VERSION ""

NS_ :

BS_:

BU_: NBICU SBICU NBCMU SBCMU DAPP Vector_XXX

BO_ 2561802145 NBCMU01_WarningInfo1: 8 NBCMU
 SG_ NBCMU01_HeatCurr : 7|12@0+ (0.1,-200) [-200|200] "A"  DAPP
 SG_ NBCMU01_SysFailSta : 9|2@0+ (1,0) [0|3] ""  DAPP
 SG_ NBCMU01_InsRes_polarity : 11|2@0+ (1,0) [0|3] ""  DAPP
 SG_ NBCMU01_BattVolt_HighWarning : 17|2@0+ (1,0) [0|3] ""  DAPP
 SG_ NBCMU01_BattVolt_LowWarning : 19|2@0+ (1,0) [0|3] ""  DAPP
 SG_ NBCMU01_CellVolt_HighWarning : 21|2@0+ (1,0) [0|3] ""  DAPP
 SG_ NBCMU01_CellVolt_LowWarning : 23|2@0+ (1,0) [0|3] ""  DAPP
 SG_ NBCMU01_ChrgTemp_HighWarning : 25|2@0+ (1,0) [0|3] ""  DAPP
 SG_ NBCMU01_ChrgTemp_LowWarning : 27|2@0+ (1,0) [0|3] ""  DAPP
 SG_ NBCMU01_DischrgTemp_HighWarning : 29|2@0+ (1,0) [0|3] ""  DAPP
 SG_ NBCMU01_DischrgTemp_LowWarning : 31|2@0+ (1,0) [0|3] ""  DAPP
 SG_ NBCMU01_TempDiff_Warning : 33|2@0+ (1,0) [0|3] ""  DAPP
 SG_ NBCMU01_CellVoltDiff_Warning : 35|2@0+ (1,0) [0|3] ""  DAPP
 SG_ NBCMU01_DischrgCurr_OverWarning : 37|2@0+ (1,0) [0|3] ""  DAPP
 SG_ NBCMU01_ChrgCurr_OverWarning : 39|2@0+ (1,0) [0|3] ""  DAPP
 SG_ NBCMU01_InsulationWarning : 41|2@0+ (1,0) [0|3] ""  DAPP
 SG_ NBCMU01_SOC_LowWarning : 43|2@0+ (1,0) [0|3] ""  DAPP
 SG_ NBCMU01_AmbientTemp_HighWarning : 45|2@0+ (1,0) [0|3] ""  DAPP
 SG_ NBCMU01_AmbientTemp_LowWarning : 47|2@0+ (1,0) [0|3] ""  DAPP
 SG_ NBCMU01_ContactorPosi_Fault : 49|2@0+ (1,0) [0|3] ""  DAPP
 SG_ NBCMU01_ContactorNega_Fault : 51|2@0+ (1,0) [0|3] ""  DAPP
 SG_ NBCMU01_ContactorBalan_Fault : 53|2@0+ (1,0) [0|3] ""  DAPP
 SG_ NBCMU01_ContactorHeat_Fault : 55|2@0+ (1,0) [0|3] ""  DAPP
 SG_ NBCMU01_CurrSensor_TimeOut : 57|1@0+ (1,0) [0|1] ""  DAPP
 SG_ NBCMU01_SOH_LowWarning : 59|2@0+ (1,0) [0|3] ""  DAPP
 SG_ NBCMU01_HVIL_Fault : 62|1@0+ (1,0) [0|1] ""  DAPP
 SG_ NBCMU01_Fuse_Fault : 63|1@0+ (1,0) [0|1] ""  DAPP

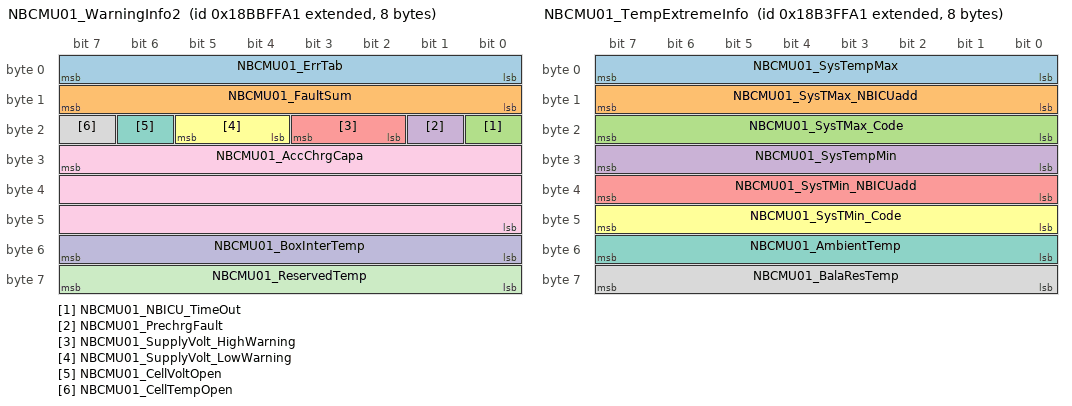
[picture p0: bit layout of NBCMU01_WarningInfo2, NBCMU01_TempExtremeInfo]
BO_ 2562457505 NBCMU01_WarningInfo2: 8 NBCMU
 SG_ NBCMU01_ErrTab : 7|8@0+ (1,0) [0|255] ""  DAPP
 SG_ NBCMU01_FaultSum : 15|8@0+ (1,0) [0|255] ""  DAPP
 SG_ NBCMU01_NBICU_TimeOut : 16|1@0+ (1,0) [0|1] ""  DAPP
 SG_ NBCMU01_PrechrgFault : 17|1@0+ (1,0) [0|1] ""  DAPP
 SG_ NBCMU01_SupplyVolt_HighWarning : 19|2@0+ (1,0) [0|3] ""  DAPP
 SG_ NBCMU01_SupplyVolt_LowWarning : 21|2@0+ (1,0) [0|3] ""  DAPP
 SG_ NBCMU01_CellVoltOpen : 22|1@0+ (1,0) [0|1] ""  DAPP
 SG_ NBCMU01_CellTempOpen : 23|1@0+ (1,0) [0|1] ""  DAPP
 SG_ NBCMU01_AccChrgCapa : 31|24@0+ (1,0) [0|16777215] "Ah"  DAPP
 SG_ NBCMU01_BoxInterTemp : 55|8@0+ (1,-40) [-40|215] "℃"  DAPP
 SG_ NBCMU01_ReservedTemp : 63|8@0+ (1,-40) [-40|215] "℃"  DAPP

BO_ 2561867681 NBCMU01_VoltExtremeInfo: 8 NBCMU
 SG_ NBCMU01_SysCellVoltMax : 7|16@0+ (1,0) [0|65535] "mV"  DAPP
 SG_ NBCMU01_SysVMax_NBICUadd : 23|8@0+ (1,0) [0|255] ""  DAPP
 SG_ NBCMU01_SysVMax_Code : 31|8@0+ (1,0) [0|255] ""  DAPP
 SG_ NBCMU01_SysCellVoltMin : 39|16@0+ (1,0) [0|65535] "mV"  DAPP
 SG_ NBCMU01_SysVMin_NBICUadd : 55|8@0+ (1,0) [0|255] ""  DAPP
 SG_ NBCMU01_SysVMin_Code : 63|8@0+ (1,0) [0|255] ""  DAPP

BO_ 2561933217 NBCMU01_TempExtremeInfo: 8 NBCMU
 SG_ NBCMU01_SysTempMax : 7|8@0+ (1,-40) [-40|215] "℃"  DAPP
 SG_ NBCMU01_SysTMax_NBICUadd : 15|8@0+ (1,0) [0|255] ""  DAPP
 SG_ NBCMU01_SysTMax_Code : 23|8@0+ (1,0) [0|255] ""  DAPP
 SG_ NBCMU01_SysTempMin : 31|8@0+ (1,-40) [-40|215] "℃"  DAPP
 SG_ NBCMU01_SysTMin_NBICUadd : 39|8@0+ (1,0) [0|255] ""  DAPP
 SG_ NBCMU01_SysTMin_Code : 47|8@0+ (1,0) [0|255] ""  DAPP
 SG_ NBCMU01_AmbientTemp : 55|8@0+ (1,-40) [-40|215] "℃"  DAPP
 SG_ NBCMU01_BalaResTemp : 63|8@0+ (1,-40) [-40|215] "℃"  DAPP

BO_ 2561998753 NBCMU01_SysSOX: 8 NBCMU
 SG_ NBCMU01_SysSOC_Actl : 7|16@0+ (0.1,0) [0|65535] "%"  DAPP
 SG_ NBCMU01_SysSOC_Dis : 23|16@0+ (0.1,0) [0|65535] "%"  DAPP
 SG_ NBCMU01_SysSOH_ByNBICU : 39|8@0+ (1,0) [0|255] "%"  DAPP
 SG_ NBCMU01_SysSOH_Cal : 47|8@0+ (1,0) [0|255] "%"  DAPP
 SG_ NBCMU01_SysSOE : 55|16@0+ (0.1,0) [0|6553.5] "%"  DAPP

BO_ 2562064289 NBCMU01_SysHVoltage: 8 NBCMU
 SG_ NBCMU01_SysHVoltage : 7|16@0+ (0.1,0) [0|6553.5] "V"  DAPP
 SG_ NBCMU01_SysSumVoltage : 23|16@0+ (0.1,0) [0|6553.5] "V"  DAPP
 SG_ NBCMU01_SysSampVoltage : 39|16@0+ (0.1,0) [0|6553.5] "V"  DAPP
 SG_ NBCMU01_SysInsRes : 55|16@0+ (1,0) [0|65535] "KΩ"  DAPP

BO_ 2562195361 NBCMU01_DischrgChrg: 8 NBCMU
 SG_ NBCMU01_MaxConDisCurnt : 7|16@0+ (0.1,0) [0|6553.5] "A"  DAPP
 SG_ NBCMU01_MaxConChrgCurnt : 23|16@0+ (0.1,0) [0|6553.5] "A"  DAPP
 SG_ NBCMU01_MaxInstanDisCurnt : 39|16@0+ (0.1,0) [0|6553.5] "A"  DAPP
 SG_ NBCMU01_MaxInstanChrgCurnt : 55|16@0+ (0.1,0) [0|6553.5] "A"  DAPP

BO_ 2560884641 NBCMU01_WarningInfo3: 8 NBCMU
 SG_ NBCMU01_SumVolt_HighWarning : 1|2@0+ (1,0) [0|3] ""  SBCMU,DAPP
 SG_ NBCMU01_SumVolt_LowWarning : 3|2@0+ (1,0) [0|3] ""  SBCMU,DAPP
 SG_ NBCMU01_CurrentLoop_HighWarning : 8|1@0+ (1,0) [0|1] ""  SBCMU,DAPP
 SG_ NBCMU01_ProtectFault : 9|1@0+ (1,0) [0|1] ""  SBCMU,DAPP
 SG_ NBCMU01_RunLed_State : 10|1@0+ (1,0) [0|1] ""  SBCMU,DAPP
 SG_ NBCMU01_Buzz_State : 11|1@0+ (1,0) [0|1] ""  SBCMU,DAPP
 SG_ NBCMU01_Heating_State : 12|1@0+ (1,0) [0|1] ""  SBCMU,DAPP
 SG_ NBCMU01_Cooling_State : 13|1@0+ (1,0) [0|1] ""  SBCMU,DAPP
 SG_ NBCMU01_BattVoltDiff_Warning : 14|1@0+ (1,0) [0|1] ""  SBCMU,DAPP
 SG_ NBCMU01_EmergyShutdown_Fault : 15|1@0+ (1,0) [0|1] ""  SBCMU,DAPP
 SG_ NBCMU01_PCS_TimeOut : 16|1@0+ (1,0) [0|1] ""  SBCMU,DAPP
 SG_ NBCMU01_EMS_TimeOut : 17|1@0+ (1,0) [0|1] ""  SBCMU,DAPP
 SG_ NBCMU01_TMS_TimeOut : 18|1@0+ (1,0) [0|1] ""  SBCMU,DAPP
 SG_ NBCMU01_SBCMU01_TimeOut : 19|1@0+ (1,0) [0|1] ""  SBCMU,DAPP
 SG_ NBCMU01_InitialFault : 30|1@0+ (1,0) [0|1] ""  SBCMU,DAPP
 SG_ NBCMU01_ThermalManagement_Fault : 31|1@0+ (1,0) [0|3] ""  SBCMU,DAPP
 SG_ NBCMU01_DCS_ActOprtMode : 26|3@0+ (1,0) [0|7] ""  SBCMU,DAPP
 SG_ NBCMU01_ChrgFault : 27|1@0+ (1,0) [0|1] ""  SBCMU,DAPP
 SG_ NBCMU01_DC_ChrgEnable : 28|1@0+ (1,0) [0|1] ""  SBCMU,DAPP
 SG_ NBCMU01_Contactor_DC_Cmd : 29|1@0+ (1,0) [0|1] ""  SBCMU,DAPP
 SG_ NBCMU01_MaxAllowChrgCur_DC : 39|16@0+ (0.1,0) [0|6553.5] "A"  SBCMU,DAPP
 SG_ NBCMU01_MaxAllowChrgVol_DC : 55|16@0+ (0.1,0) [0|6553.5] "V"  SBCMU,DAPP

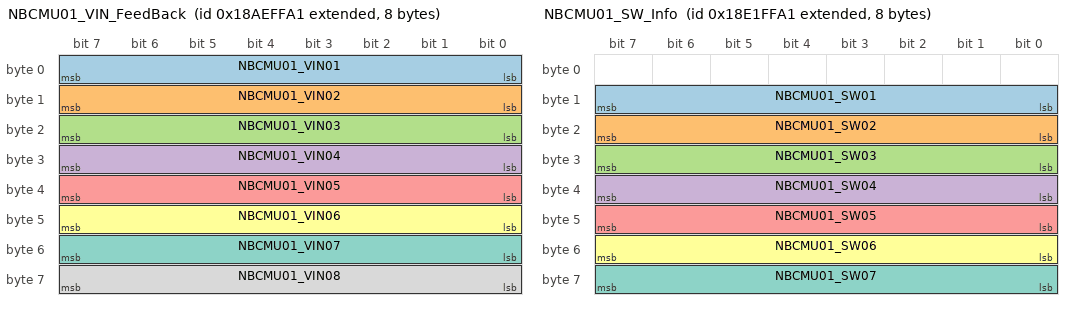
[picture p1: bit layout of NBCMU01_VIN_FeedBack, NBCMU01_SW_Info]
BO_ 2561605537 NBCMU01_VIN_FeedBack: 8 NBCMU
 SG_ NBCMU01_VIN01 : 7|8@0+ (1,0) [0|255] ""  DAPP
 SG_ NBCMU01_VIN02 : 15|8@0+ (1,0) [0|255] ""  DAPP
 SG_ NBCMU01_VIN03 : 23|8@0+ (1,0) [0|255] ""  DAPP
 SG_ NBCMU01_VIN04 : 31|8@0+ (1,0) [0|255] ""  DAPP
 SG_ NBCMU01_VIN05 : 39|8@0+ (1,0) [0|155] ""  DAPP
 SG_ NBCMU01_VIN06 : 47|8@0+ (1,0) [0|255] ""  DAPP
 SG_ NBCMU01_VIN07 : 55|8@0+ (1,0) [0|255] ""  DAPP
 SG_ NBCMU01_VIN08 : 63|8@0+ (1,0) [0|255] ""  DAPP

BO_ 2564947873 NBCMU01_SW_Info: 8 NBCMU
 SG_ NBCMU01_SW01 : 15|8@0+ (1,0) [0|255] ""  DAPP
 SG_ NBCMU01_SW02 : 23|8@0+ (1,0) [0|255] ""  DAPP
 SG_ NBCMU01_SW03 : 31|8@0+ (1,0) [0|255] ""  DAPP
 SG_ NBCMU01_SW04 : 39|8@0+ (1,0) [0|255] ""  DAPP
 SG_ NBCMU01_SW05 : 47|8@0+ (1,0) [0|255] ""  DAPP
 SG_ NBCMU01_SW06 : 55|8@0+ (1,0) [0|255] ""  DAPP
 SG_ NBCMU01_SW07 : 63|8@0+ (1,0) [0|255] ""  DAPP

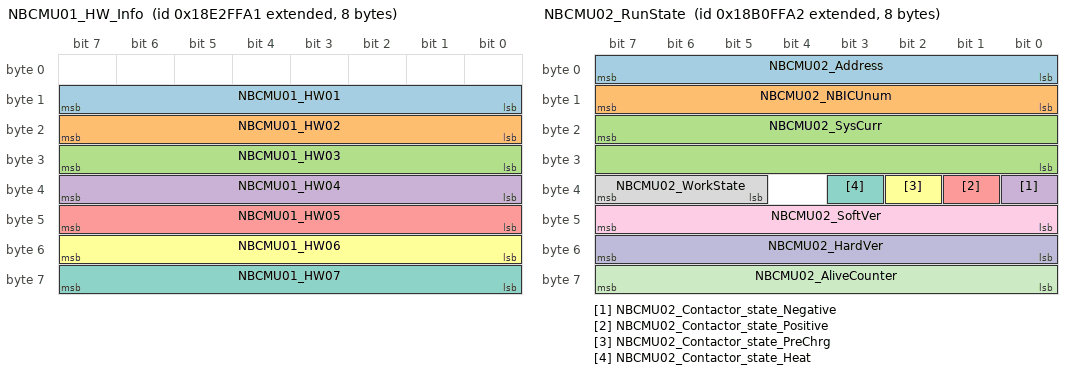
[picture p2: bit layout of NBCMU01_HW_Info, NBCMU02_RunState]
BO_ 2565013409 NBCMU01_HW_Info: 8 NBCMU
 SG_ NBCMU01_HW01 : 15|8@0+ (1,0) [0|255] ""  DAPP
 SG_ NBCMU01_HW02 : 23|8@0+ (1,0) [0|255] ""  DAPP
 SG_ NBCMU01_HW03 : 31|8@0+ (1,0) [0|255] ""  DAPP
 SG_ NBCMU01_HW04 : 39|8@0+ (1,0) [0|255] ""  DAPP
 SG_ NBCMU01_HW05 : 47|8@0+ (1,0) [0|255] ""  DAPP
 SG_ NBCMU01_HW06 : 55|8@0+ (1,0) [0|255] ""  DAPP
 SG_ NBCMU01_HW07 : 63|8@0+ (1,0) [0|255] ""  DAPP

BO_ 2561736610 NBCMU02_RunState: 8 NBCMU
 SG_ NBCMU02_Address : 7|8@0+ (1,0) [0|255] ""  DAPP
 SG_ NBCMU02_NBICUnum : 15|8@0+ (1,0) [0|255] ""  DAPP
 SG_ NBCMU02_SysCurr : 23|16@0+ (0.1,-3000) [-3000|3000] "A"  DAPP
 SG_ NBCMU02_Contactor_state_Negative : 32|1@0+ (1,0) [0|1] ""  DAPP
 SG_ NBCMU02_Contactor_state_Positive : 33|1@0+ (1,0) [0|1] ""  DAPP
 SG_ NBCMU02_Contactor_state_PreChrg : 34|1@0+ (1,0) [0|1] ""  DAPP
 SG_ NBCMU02_Contactor_state_Heat : 35|1@0+ (1,0) [0|1] ""  DAPP
 SG_ NBCMU02_WorkState : 39|3@0+ (1,0) [0|7] ""  DAPP
 SG_ NBCMU02_SoftVer : 47|8@0+ (1,0) [0|255] ""  DAPP
 SG_ NBCMU02_HardVer : 55|8@0+ (1,0) [0|255] ""  DAPP
 SG_ NBCMU02_AliveCounter : 63|8@0+ (1,0) [0|255] ""  DAPP

BO_ 2561802146 NBCMU02_WarningInfo1: 8 NBCMU
 SG_ NBCMU02_HeatCurr : 7|12@0+ (0.1,-200) [-200|200] "A"  DAPP
 SG_ NBCMU02_SysFailSta : 9|2@0+ (1,0) [0|3] ""  DAPP
 SG_ NBCMU02_InsRes_polarity : 11|2@0+ (1,0) [0|3] ""  DAPP
 SG_ NBCMU02_BattVolt_HighWarning : 17|2@0+ (1,0) [0|3] ""  DAPP
 SG_ NBCMU02_BattVolt_LowWarning : 19|2@0+ (1,0) [0|3] ""  DAPP
 SG_ NBCMU02_CellVolt_HighWarning : 21|2@0+ (1,0) [0|3] ""  DAPP
 SG_ NBCMU02_CellVolt_LowWarning : 23|2@0+ (1,0) [0|3] ""  DAPP
 SG_ NBCMU02_ChrgTemp_HighWarning : 25|2@0+ (1,0) [0|3] ""  DAPP
 SG_ NBCMU02_ChrgTemp_LowWarning : 27|2@0+ (1,0) [0|3] ""  DAPP
 SG_ NBCMU02_DischrgTemp_HighWarning : 29|2@0+ (1,0) [0|3] ""  DAPP
 SG_ NBCMU02_DischrgTemp_LowWarning : 31|2@0+ (1,0) [0|3] ""  DAPP
 SG_ NBCMU02_TempDiff_Warning : 33|2@0+ (1,0) [0|3] ""  DAPP
 SG_ NBCMU02_CellVoltDiff_Warning : 35|2@0+ (1,0) [0|3] ""  DAPP
 SG_ NBCMU02_DischrgCurr_OverWarning : 37|2@0+ (1,0) [0|3] ""  DAPP
 SG_ NBCMU02_ChrgCurr_OverWarning : 39|2@0+ (1,0) [0|3] ""  DAPP
 SG_ NBCMU02_InsulationWarning : 41|2@0+ (1,0) [0|3] ""  DAPP
 SG_ NBCMU02_SOC_LowWarning : 43|2@0+ (1,0) [0|3] ""  DAPP
 SG_ NBCMU02_AmbientTemp_HighWarning : 45|2@0+ (1,0) [0|3] ""  DAPP
 SG_ NBCMU02_AmbientTemp_LowWarning : 47|2@0+ (1,0) [0|3] ""  DAPP
 SG_ NBCMU02_ContactorPosi_Fault : 49|2@0+ (1,0) [0|3] ""  DAPP
 SG_ NBCMU02_ContactorNega_Fault : 51|2@0+ (1,0) [0|3] ""  DAPP
 SG_ NBCMU02_ContactorBalan_Fault : 53|2@0+ (1,0) [0|3] ""  DAPP
 SG_ NBCMU02_ContactorHeat_Fault : 55|2@0+ (1,0) [0|3] ""  DAPP
 SG_ NBCMU02_CurrSensor_TimeOut : 57|1@0+ (1,0) [0|1] ""  DAPP
 SG_ NBCMU02_SOH_LowWarning : 59|2@0+ (1,0) [0|3] ""  DAPP
 SG_ NBCMU02_HVIL_Fault : 62|1@0+ (1,0) [0|1] ""  DAPP
 SG_ NBCMU02_Fuse_Fault : 63|1@0+ (1,0) [0|1] ""  DAPP

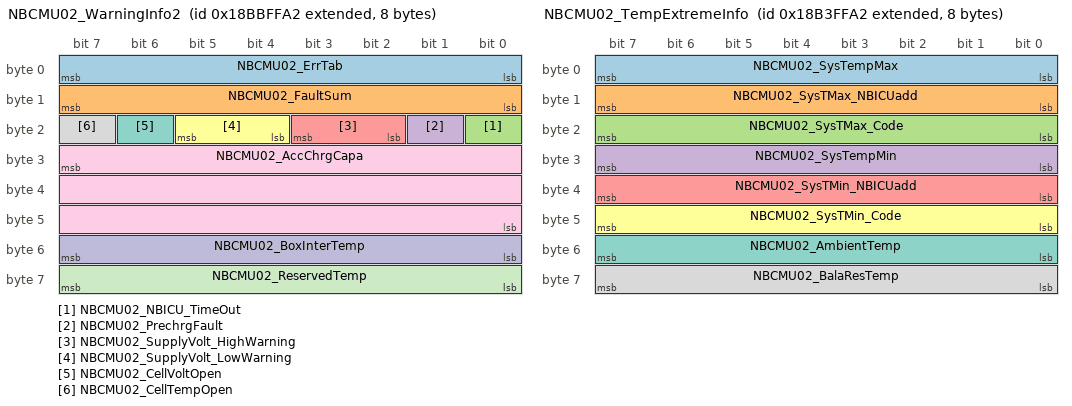
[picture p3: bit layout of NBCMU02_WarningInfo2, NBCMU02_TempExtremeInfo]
BO_ 2562457506 NBCMU02_WarningInfo2: 8 NBCMU
 SG_ NBCMU02_ErrTab : 7|8@0+ (1,0) [0|255] ""  DAPP
 SG_ NBCMU02_FaultSum : 15|8@0+ (1,0) [0|255] ""  DAPP
 SG_ NBCMU02_NBICU_TimeOut : 16|1@0+ (1,0) [0|1] ""  DAPP
 SG_ NBCMU02_PrechrgFault : 17|1@0+ (1,0) [0|1] ""  DAPP
 SG_ NBCMU02_SupplyVolt_HighWarning : 19|2@0+ (1,0) [0|3] ""  DAPP
 SG_ NBCMU02_SupplyVolt_LowWarning : 21|2@0+ (1,0) [0|3] ""  DAPP
 SG_ NBCMU02_CellVoltOpen : 22|1@0+ (1,0) [0|1] ""  DAPP
 SG_ NBCMU02_CellTempOpen : 23|1@0+ (1,0) [0|1] ""  DAPP
 SG_ NBCMU02_AccChrgCapa : 31|24@0+ (1,0) [0|16777215] "Ah"  DAPP
 SG_ NBCMU02_BoxInterTemp : 55|8@0+ (1,-40) [-40|215] "℃"  DAPP
 SG_ NBCMU02_ReservedTemp : 63|8@0+ (1,-40) [-40|215] "℃"  DAPP

BO_ 2561867682 NBCMU02_VoltExtremeInfo: 8 NBCMU
 SG_ NBCMU02_SysCellVoltMax : 7|16@0+ (1,0) [0|65535] "mV"  DAPP
 SG_ NBCMU02_SysVMax_NBICUadd : 23|8@0+ (1,0) [0|255] ""  DAPP
 SG_ NBCMU02_SysVMax_Code : 31|8@0+ (1,0) [0|255] ""  DAPP
 SG_ NBCMU02_SysCellVoltMin : 39|16@0+ (1,0) [0|65535] "mV"  DAPP
 SG_ NBCMU02_SysVMin_NBICUadd : 55|8@0+ (1,0) [0|255] ""  DAPP
 SG_ NBCMU02_SysVMin_Code : 63|8@0+ (1,0) [0|255] ""  DAPP

BO_ 2561933218 NBCMU02_TempExtremeInfo: 8 NBCMU
 SG_ NBCMU02_SysTempMax : 7|8@0+ (1,-40) [-40|215] "℃"  DAPP
 SG_ NBCMU02_SysTMax_NBICUadd : 15|8@0+ (1,0) [0|255] ""  DAPP
 SG_ NBCMU02_SysTMax_Code : 23|8@0+ (1,0) [0|255] ""  DAPP
 SG_ NBCMU02_SysTempMin : 31|8@0+ (1,-40) [-40|215] "℃"  DAPP
 SG_ NBCMU02_SysTMin_NBICUadd : 39|8@0+ (1,0) [0|255] ""  DAPP
 SG_ NBCMU02_SysTMin_Code : 47|8@0+ (1,0) [0|255] ""  DAPP
 SG_ NBCMU02_AmbientTemp : 55|8@0+ (1,-40) [-40|215] "℃"  DAPP
 SG_ NBCMU02_BalaResTemp : 63|8@0+ (1,-40) [-40|215] "℃"  DAPP

BO_ 2561998754 NBCMU02_SysSOX: 8 NBCMU
 SG_ NBCMU02_SysSOC_Actl : 7|16@0+ (0.1,0) [0|65535] "%"  DAPP
 SG_ NBCMU02_SysSOC_Dis : 23|16@0+ (0.1,0) [0|65535] "%"  DAPP
 SG_ NBCMU02_SysSOH_ByNBICU : 39|8@0+ (1,0) [0|255] "%"  DAPP
 SG_ NBCMU02_SysSOH_Cal : 47|8@0+ (1,0) [0|255] "%"  DAPP
 SG_ NBCMU02_SysSOE : 55|16@0+ (0.1,0) [0|6553.5] "%"  DAPP

BO_ 2562064290 NBCMU02_SysHVoltage: 8 NBCMU
 SG_ NBCMU02_SysHVoltage : 7|16@0+ (0.1,0) [0|6553.5] "V"  DAPP
 SG_ NBCMU02_SysSumVoltage : 23|16@0+ (0.1,0) [0|6553.5] "V"  DAPP
 SG_ NBCMU02_SysSampVoltage : 39|16@0+ (0.1,0) [0|6553.5] "V"  DAPP
 SG_ NBCMU02_SysInsRes : 55|16@0+ (1,0) [0|65535] "KΩ"  DAPP

BO_ 2562195362 NBCMU02_DischrgChrg: 8 NBCMU
 SG_ NBCMU02_MaxConDisCurnt : 7|16@0+ (0.1,0) [0|6553.5] "A"  DAPP
 SG_ NBCMU02_MaxConChrgCurnt : 23|16@0+ (0.1,0) [0|6553.5] "A"  DAPP
 SG_ NBCMU02_MaxInstanDisCurnt : 39|16@0+ (0.1,0) [0|6553.5] "A"  DAPP
 SG_ NBCMU02_MaxInstanChrgCurnt : 55|16@0+ (0.1,0) [0|6553.5] "A"  DAPP

BO_ 2560884642 NBCMU02_WarningInfo3: 8 NBCMU
 SG_ NBCMU02_SumVolt_HighWarning : 1|2@0+ (1,0) [0|3] ""  SBCMU,DAPP
 SG_ NBCMU02_SumVolt_LowWarning : 3|2@0+ (1,0) [0|3] ""  SBCMU,DAPP
 SG_ NBCMU02_CurrentLoop_HighWarning : 8|1@0+ (1,0) [0|1] ""  SBCMU,DAPP
 SG_ NBCMU02_ProtectFault : 9|1@0+ (1,0) [0|1] ""  SBCMU,DAPP
 SG_ NBCMU02_RunLed_State : 10|1@0+ (1,0) [0|1] ""  SBCMU,DAPP
 SG_ NBCMU02_Buzz_State : 11|1@0+ (1,0) [0|1] ""  SBCMU,DAPP
 SG_ NBCMU02_Heating_State : 12|1@0+ (1,0) [0|1] ""  SBCMU,DAPP
 SG_ NBCMU02_Cooling_State : 13|1@0+ (1,0) [0|1] ""  SBCMU,DAPP
 SG_ NBCMU02_BattVoltDiff_Warning : 14|1@0+ (1,0) [0|1] ""  SBCMU,DAPP
 SG_ NBCMU02_EmergyShutdown_Fault : 15|1@0+ (1,0) [0|1] ""  SBCMU,DAPP
 SG_ NBCMU02_PCS_TimeOut : 16|1@0+ (1,0) [0|1] ""  SBCMU,DAPP
 SG_ NBCMU02_EMS_TimeOut : 17|1@0+ (1,0) [0|1] ""  SBCMU,DAPP
 SG_ NBCMU02_TMS_TimeOut : 18|1@0+ (1,0) [0|1] ""  SBCMU,DAPP
 SG_ NBCMU02_SBCMU01_TimeOut : 19|1@0+ (1,0) [0|1] ""  SBCMU,DAPP
 SG_ NBCMU02_InitialFault : 30|1@0+ (1,0) [0|1] ""  SBCMU,DAPP
 SG_ NBCMU02_ThermalManagement_Fault : 31|1@0+ (1,0) [0|3] ""  SBCMU,DAPP
 SG_ NBCMU02_DCS_ActOprtMode : 26|3@0+ (1,0) [0|7] ""  SBCMU,DAPP
 SG_ NBCMU02_ChrgFault : 27|1@0+ (1,0) [0|1] ""  SBCMU,DAPP
 SG_ NBCMU02_DC_ChrgEnable : 28|1@0+ (1,0) [0|1] ""  SBCMU,DAPP
 SG_ NBCMU02_Contactor_DC_Cmd : 29|1@0+ (1,0) [0|1] ""  SBCMU,DAPP
 SG_ NBCMU02_MaxAllowChrgCur_DC : 39|16@0+ (0.1,0) [0|6553.5] "A"  SBCMU,DAPP
 SG_ NBCMU02_MaxAllowChrgVol_DC : 55|16@0+ (0.1,0) [0|6553.5] "V"  SBCMU,DAPP

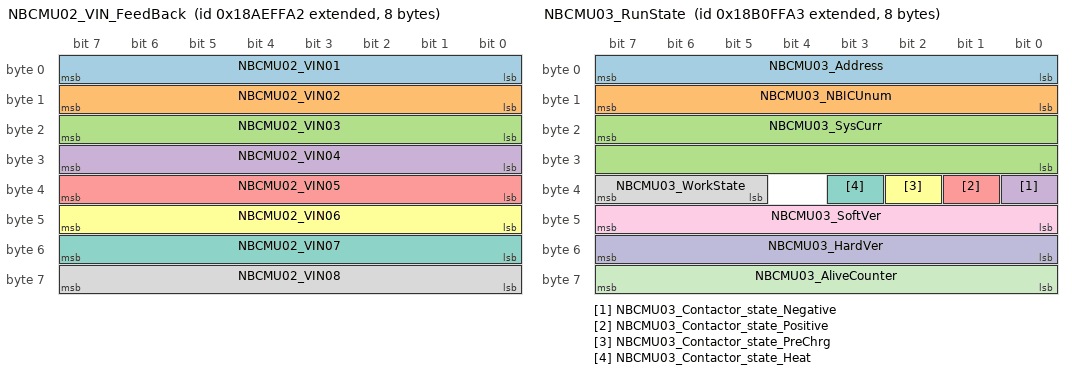
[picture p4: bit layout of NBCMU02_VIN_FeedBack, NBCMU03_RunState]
BO_ 2561605538 NBCMU02_VIN_FeedBack: 8 NBCMU
 SG_ NBCMU02_VIN01 : 7|8@0+ (1,0) [0|255] ""  DAPP
 SG_ NBCMU02_VIN02 : 15|8@0+ (1,0) [0|255] ""  DAPP
 SG_ NBCMU02_VIN03 : 23|8@0+ (1,0) [0|255] ""  DAPP
 SG_ NBCMU02_VIN04 : 31|8@0+ (1,0) [0|255] ""  DAPP
 SG_ NBCMU02_VIN05 : 39|8@0+ (1,0) [0|155] ""  DAPP
 SG_ NBCMU02_VIN06 : 47|8@0+ (1,0) [0|255] ""  DAPP
 SG_ NBCMU02_VIN07 : 55|8@0+ (1,0) [0|255] ""  DAPP
 SG_ NBCMU02_VIN08 : 63|8@0+ (1,0) [0|255] ""  DAPP

BO_ 2564947874 NBCMU02_SW_Info: 8 NBCMU
 SG_ NBCMU02_SW01 : 15|8@0+ (1,0) [0|255] ""  DAPP
 SG_ NBCMU02_SW02 : 23|8@0+ (1,0) [0|255] ""  DAPP
 SG_ NBCMU02_SW03 : 31|8@0+ (1,0) [0|255] ""  DAPP
 SG_ NBCMU02_SW04 : 39|8@0+ (1,0) [0|255] ""  DAPP
 SG_ NBCMU02_SW05 : 47|8@0+ (1,0) [0|255] ""  DAPP
 SG_ NBCMU02_SW06 : 55|8@0+ (1,0) [0|255] ""  DAPP
 SG_ NBCMU02_SW07 : 63|8@0+ (1,0) [0|255] ""  DAPP

BO_ 2565013410 NBCMU02_HW_Info: 8 NBCMU
 SG_ NBCMU02_HW01 : 15|8@0+ (1,0) [0|255] ""  DAPP
 SG_ NBCMU02_HW02 : 23|8@0+ (1,0) [0|255] ""  DAPP
 SG_ NBCMU02_HW03 : 31|8@0+ (1,0) [0|255] ""  DAPP
 SG_ NBCMU02_HW04 : 39|8@0+ (1,0) [0|255] ""  DAPP
 SG_ NBCMU02_HW05 : 47|8@0+ (1,0) [0|255] ""  DAPP
 SG_ NBCMU02_HW06 : 55|8@0+ (1,0) [0|255] ""  DAPP
 SG_ NBCMU02_HW07 : 63|8@0+ (1,0) [0|255] ""  DAPP

BO_ 2561736611 NBCMU03_RunState: 8 NBCMU
 SG_ NBCMU03_Address : 7|8@0+ (1,0) [0|255] ""  DAPP
 SG_ NBCMU03_NBICUnum : 15|8@0+ (1,0) [0|255] ""  DAPP
 SG_ NBCMU03_SysCurr : 23|16@0+ (0.1,-3000) [-3000|3000] "A"  DAPP
 SG_ NBCMU03_Contactor_state_Negative : 32|1@0+ (1,0) [0|1] ""  DAPP
 SG_ NBCMU03_Contactor_state_Positive : 33|1@0+ (1,0) [0|1] ""  DAPP
 SG_ NBCMU03_Contactor_state_PreChrg : 34|1@0+ (1,0) [0|1] ""  DAPP
 SG_ NBCMU03_Contactor_state_Heat : 35|1@0+ (1,0) [0|1] ""  DAPP
 SG_ NBCMU03_WorkState : 39|3@0+ (1,0) [0|7] ""  DAPP
 SG_ NBCMU03_SoftVer : 47|8@0+ (1,0) [0|255] ""  DAPP
 SG_ NBCMU03_HardVer : 55|8@0+ (1,0) [0|255] ""  DAPP
 SG_ NBCMU03_AliveCounter : 63|8@0+ (1,0) [0|255] ""  DAPP

BO_ 2561802147 NBCMU03_WarningInfo1: 8 NBCMU
 SG_ NBCMU03_HeatCurr : 7|12@0+ (0.1,-200) [-200|200] "A"  DAPP
 SG_ NBCMU03_SysFailSta : 9|2@0+ (1,0) [0|3] ""  DAPP
 SG_ NBCMU03_InsRes_polarity : 11|2@0+ (1,0) [0|3] ""  DAPP
 SG_ NBCMU03_BattVolt_HighWarning : 17|2@0+ (1,0) [0|3] ""  DAPP
 SG_ NBCMU03_BattVolt_LowWarning : 19|2@0+ (1,0) [0|3] ""  DAPP
 SG_ NBCMU03_CellVolt_HighWarning : 21|2@0+ (1,0) [0|3] ""  DAPP
 SG_ NBCMU03_CellVolt_LowWarning : 23|2@0+ (1,0) [0|3] ""  DAPP
 SG_ NBCMU03_ChrgTemp_HighWarning : 25|2@0+ (1,0) [0|3] ""  DAPP
 SG_ NBCMU03_ChrgTemp_LowWarning : 27|2@0+ (1,0) [0|3] ""  DAPP
 SG_ NBCMU03_DischrgTemp_HighWarning : 29|2@0+ (1,0) [0|3] ""  DAPP
 SG_ NBCMU03_DischrgTemp_LowWarning : 31|2@0+ (1,0) [0|3] ""  DAPP
 SG_ NBCMU03_TempDiff_Warning : 33|2@0+ (1,0) [0|3] ""  DAPP
 SG_ NBCMU03_CellVoltDiff_Warning : 35|2@0+ (1,0) [0|3] ""  DAPP
 SG_ NBCMU03_DischrgCurr_OverWarning : 37|2@0+ (1,0) [0|3] ""  DAPP
 SG_ NBCMU03_ChrgCurr_OverWarning : 39|2@0+ (1,0) [0|3] ""  DAPP
 SG_ NBCMU03_InsulationWarning : 41|2@0+ (1,0) [0|3] ""  DAPP
 SG_ NBCMU03_SOC_LowWarning : 43|2@0+ (1,0) [0|3] ""  DAPP
 SG_ NBCMU03_AmbientTemp_HighWarning : 45|2@0+ (1,0) [0|3] ""  DAPP
 SG_ NBCMU03_AmbientTemp_LowWarning : 47|2@0+ (1,0) [0|3] ""  DAPP
 SG_ NBCMU03_ContactorPosi_Fault : 49|2@0+ (1,0) [0|3] ""  DAPP
 SG_ NBCMU03_ContactorNega_Fault : 51|2@0+ (1,0) [0|3] ""  DAPP
 SG_ NBCMU03_ContactorBalan_Fault : 53|2@0+ (1,0) [0|3] ""  DAPP
 SG_ NBCMU03_ContactorHeat_Fault : 55|2@0+ (1,0) [0|3] ""  DAPP
 SG_ NBCMU03_CurrSensor_TimeOut : 57|1@0+ (1,0) [0|1] ""  DAPP
 SG_ NBCMU03_SOH_LowWarning : 59|2@0+ (1,0) [0|3] ""  DAPP
 SG_ NBCMU03_HVIL_Fault : 62|1@0+ (1,0) [0|1] ""  DAPP
 SG_ NBCMU03_Fuse_Fault : 63|1@0+ (1,0) [0|1] ""  DAPP

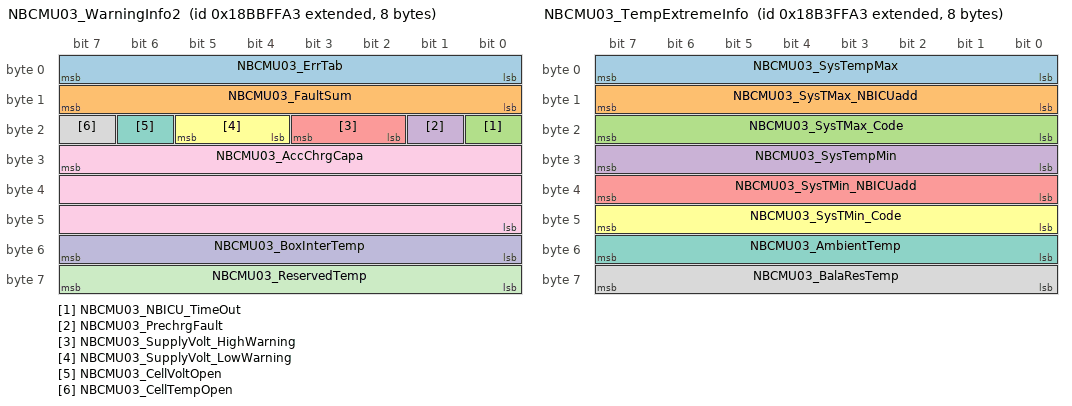
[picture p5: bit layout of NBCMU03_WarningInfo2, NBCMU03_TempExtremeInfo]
BO_ 2562457507 NBCMU03_WarningInfo2: 8 NBCMU
 SG_ NBCMU03_ErrTab : 7|8@0+ (1,0) [0|255] ""  DAPP
 SG_ NBCMU03_FaultSum : 15|8@0+ (1,0) [0|255] ""  DAPP
 SG_ NBCMU03_NBICU_TimeOut : 16|1@0+ (1,0) [0|1] ""  DAPP
 SG_ NBCMU03_PrechrgFault : 17|1@0+ (1,0) [0|1] ""  DAPP
 SG_ NBCMU03_SupplyVolt_HighWarning : 19|2@0+ (1,0) [0|3] ""  DAPP
 SG_ NBCMU03_SupplyVolt_LowWarning : 21|2@0+ (1,0) [0|3] ""  DAPP
 SG_ NBCMU03_CellVoltOpen : 22|1@0+ (1,0) [0|1] ""  DAPP
 SG_ NBCMU03_CellTempOpen : 23|1@0+ (1,0) [0|1] ""  DAPP
 SG_ NBCMU03_AccChrgCapa : 31|24@0+ (1,0) [0|16777215] "Ah"  DAPP
 SG_ NBCMU03_BoxInterTemp : 55|8@0+ (1,-40) [-40|215] "℃"  DAPP
 SG_ NBCMU03_ReservedTemp : 63|8@0+ (1,-40) [-40|215] "℃"  DAPP

BO_ 2561867683 NBCMU03_VoltExtremeInfo: 8 NBCMU
 SG_ NBCMU03_SysCellVoltMax : 7|16@0+ (1,0) [0|65535] "mV"  DAPP
 SG_ NBCMU03_SysVMax_NBICUadd : 23|8@0+ (1,0) [0|255] ""  DAPP
 SG_ NBCMU03_SysVMax_Code : 31|8@0+ (1,0) [0|255] ""  DAPP
 SG_ NBCMU03_SysCellVoltMin : 39|16@0+ (1,0) [0|65535] "mV"  DAPP
 SG_ NBCMU03_SysVMin_NBICUadd : 55|8@0+ (1,0) [0|255] ""  DAPP
 SG_ NBCMU03_SysVMin_Code : 63|8@0+ (1,0) [0|255] ""  DAPP

BO_ 2561933219 NBCMU03_TempExtremeInfo: 8 NBCMU
 SG_ NBCMU03_SysTempMax : 7|8@0+ (1,-40) [-40|215] "℃"  DAPP
 SG_ NBCMU03_SysTMax_NBICUadd : 15|8@0+ (1,0) [0|255] ""  DAPP
 SG_ NBCMU03_SysTMax_Code : 23|8@0+ (1,0) [0|255] ""  DAPP
 SG_ NBCMU03_SysTempMin : 31|8@0+ (1,-40) [-40|215] "℃"  DAPP
 SG_ NBCMU03_SysTMin_NBICUadd : 39|8@0+ (1,0) [0|255] ""  DAPP
 SG_ NBCMU03_SysTMin_Code : 47|8@0+ (1,0) [0|255] ""  DAPP
 SG_ NBCMU03_AmbientTemp : 55|8@0+ (1,-40) [-40|215] "℃"  DAPP
 SG_ NBCMU03_BalaResTemp : 63|8@0+ (1,-40) [-40|215] "℃"  DAPP

BO_ 2561998755 NBCMU03_SysSOX: 8 NBCMU
 SG_ NBCMU03_SysSOC_Actl : 7|16@0+ (0.1,0) [0|65535] "%"  DAPP
 SG_ NBCMU03_SysSOC_Dis : 23|16@0+ (0.1,0) [0|65535] "%"  DAPP
 SG_ NBCMU03_SysSOH_ByNBICU : 39|8@0+ (1,0) [0|255] "%"  DAPP
 SG_ NBCMU03_SysSOH_Cal : 47|8@0+ (1,0) [0|255] "%"  DAPP
 SG_ NBCMU03_SysSOE : 55|16@0+ (0.1,0) [0|6553.5] "%"  DAPP

BO_ 2562064291 NBCMU03_SysHVoltage: 8 NBCMU
 SG_ NBCMU03_SysHVoltage : 7|16@0+ (0.1,0) [0|6553.5] "V"  DAPP
 SG_ NBCMU03_SysSumVoltage : 23|16@0+ (0.1,0) [0|6553.5] "V"  DAPP
 SG_ NBCMU03_SysSampVoltage : 39|16@0+ (0.1,0) [0|6553.5] "V"  DAPP
 SG_ NBCMU03_SysInsRes : 55|16@0+ (1,0) [0|65535] "KΩ"  DAPP

BO_ 2562195363 NBCMU03_DischrgChrg: 8 NBCMU
 SG_ NBCMU03_MaxConDisCurnt : 7|16@0+ (0.1,0) [0|6553.5] "A"  DAPP
 SG_ NBCMU03_MaxConChrgCurnt : 23|16@0+ (0.1,0) [0|6553.5] "A"  DAPP
 SG_ NBCMU03_MaxInstanDisCurnt : 39|16@0+ (0.1,0) [0|6553.5] "A"  DAPP
 SG_ NBCMU03_MaxInstanChrgCurnt : 55|16@0+ (0.1,0) [0|6553.5] "A"  DAPP

BO_ 2560884643 NBCMU03_WarningInfo3: 8 NBCMU
 SG_ NBCMU03_SumVolt_HighWarning : 1|2@0+ (1,0) [0|3] ""  SBCMU,DAPP
 SG_ NBCMU03_SumVolt_LowWarning : 3|2@0+ (1,0) [0|3] ""  SBCMU,DAPP
 SG_ NBCMU03_CurrentLoop_HighWarning : 8|1@0+ (1,0) [0|1] ""  SBCMU,DAPP
 SG_ NBCMU03_ProtectFault : 9|1@0+ (1,0) [0|1] ""  SBCMU,DAPP
 SG_ NBCMU03_RunLed_State : 10|1@0+ (1,0) [0|1] ""  SBCMU,DAPP
 SG_ NBCMU03_Buzz_State : 11|1@0+ (1,0) [0|1] ""  SBCMU,DAPP
 SG_ NBCMU03_Heating_State : 12|1@0+ (1,0) [0|1] ""  SBCMU,DAPP
 SG_ NBCMU03_Cooling_State : 13|1@0+ (1,0) [0|1] ""  SBCMU,DAPP
 SG_ NBCMU03_BattVoltDiff_Warning : 14|1@0+ (1,0) [0|1] ""  SBCMU,DAPP
 SG_ NBCMU03_EmergyShutdown_Fault : 15|1@0+ (1,0) [0|1] ""  SBCMU,DAPP
 SG_ NBCMU03_PCS_TimeOut : 16|1@0+ (1,0) [0|1] ""  SBCMU,DAPP
 SG_ NBCMU03_EMS_TimeOut : 17|1@0+ (1,0) [0|1] ""  SBCMU,DAPP
 SG_ NBCMU03_TMS_TimeOut : 18|1@0+ (1,0) [0|1] ""  SBCMU,DAPP
 SG_ NBCMU03_SBCMU01_TimeOut : 19|1@0+ (1,0) [0|1] ""  SBCMU,DAPP
 SG_ NBCMU03_InitialFault : 30|1@0+ (1,0) [0|1] ""  SBCMU,DAPP
 SG_ NBCMU03_ThermalManagement_Fault : 31|1@0+ (1,0) [0|3] ""  SBCMU,DAPP
 SG_ NBCMU03_DCS_ActOprtMode : 26|3@0+ (1,0) [0|7] ""  SBCMU,DAPP
 SG_ NBCMU03_ChrgFault : 27|1@0+ (1,0) [0|1] ""  SBCMU,DAPP
 SG_ NBCMU03_DC_ChrgEnable : 28|1@0+ (1,0) [0|1] ""  SBCMU,DAPP
 SG_ NBCMU03_Contactor_DC_Cmd : 29|1@0+ (1,0) [0|1] ""  SBCMU,DAPP
 SG_ NBCMU03_MaxAllowChrgCur_DC : 39|16@0+ (0.1,0) [0|6553.5] "A"  SBCMU,DAPP
 SG_ NBCMU03_MaxAllowChrgVol_DC : 55|16@0+ (0.1,0) [0|6553.5] "V"  SBCMU,DAPP

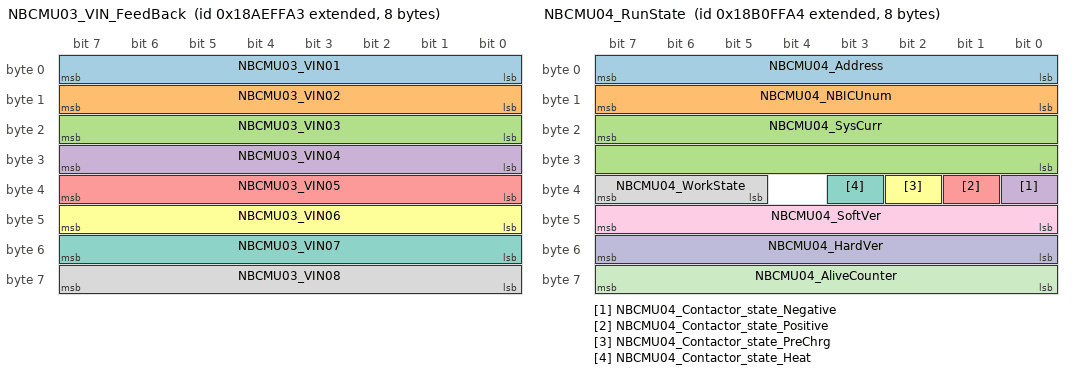
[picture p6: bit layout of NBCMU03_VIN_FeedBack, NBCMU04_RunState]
BO_ 2561605539 NBCMU03_VIN_FeedBack: 8 NBCMU
 SG_ NBCMU03_VIN01 : 7|8@0+ (1,0) [0|255] ""  DAPP
 SG_ NBCMU03_VIN02 : 15|8@0+ (1,0) [0|255] ""  DAPP
 SG_ NBCMU03_VIN03 : 23|8@0+ (1,0) [0|255] ""  DAPP
 SG_ NBCMU03_VIN04 : 31|8@0+ (1,0) [0|255] ""  DAPP
 SG_ NBCMU03_VIN05 : 39|8@0+ (1,0) [0|155] ""  DAPP
 SG_ NBCMU03_VIN06 : 47|8@0+ (1,0) [0|255] ""  DAPP
 SG_ NBCMU03_VIN07 : 55|8@0+ (1,0) [0|255] ""  DAPP
 SG_ NBCMU03_VIN08 : 63|8@0+ (1,0) [0|255] ""  DAPP

BO_ 2564947875 NBCMU03_SW_Info: 8 NBCMU
 SG_ NBCMU03_SW01 : 15|8@0+ (1,0) [0|255] ""  DAPP
 SG_ NBCMU03_SW02 : 23|8@0+ (1,0) [0|255] ""  DAPP
 SG_ NBCMU03_SW03 : 31|8@0+ (1,0) [0|255] ""  DAPP
 SG_ NBCMU03_SW04 : 39|8@0+ (1,0) [0|255] ""  DAPP
 SG_ NBCMU03_SW05 : 47|8@0+ (1,0) [0|255] ""  DAPP
 SG_ NBCMU03_SW06 : 55|8@0+ (1,0) [0|255] ""  DAPP
 SG_ NBCMU03_SW07 : 63|8@0+ (1,0) [0|255] ""  DAPP

BO_ 2565013411 NBCMU03_HW_Info: 8 NBCMU
 SG_ NBCMU03_HW01 : 15|8@0+ (1,0) [0|255] ""  DAPP
 SG_ NBCMU03_HW02 : 23|8@0+ (1,0) [0|255] ""  DAPP
 SG_ NBCMU03_HW03 : 31|8@0+ (1,0) [0|255] ""  DAPP
 SG_ NBCMU03_HW04 : 39|8@0+ (1,0) [0|255] ""  DAPP
 SG_ NBCMU03_HW05 : 47|8@0+ (1,0) [0|255] ""  DAPP
 SG_ NBCMU03_HW06 : 55|8@0+ (1,0) [0|255] ""  DAPP
 SG_ NBCMU03_HW07 : 63|8@0+ (1,0) [0|255] ""  DAPP

BO_ 2561736612 NBCMU04_RunState: 8 NBCMU
 SG_ NBCMU04_Address : 7|8@0+ (1,0) [0|255] ""  DAPP
 SG_ NBCMU04_NBICUnum : 15|8@0+ (1,0) [0|255] ""  DAPP
 SG_ NBCMU04_SysCurr : 23|16@0+ (0.1,-3000) [-3000|3000] "A"  DAPP
 SG_ NBCMU04_Contactor_state_Negative : 32|1@0+ (1,0) [0|1] ""  DAPP
 SG_ NBCMU04_Contactor_state_Positive : 33|1@0+ (1,0) [0|1] ""  DAPP
 SG_ NBCMU04_Contactor_state_PreChrg : 34|1@0+ (1,0) [0|1] ""  DAPP
 SG_ NBCMU04_Contactor_state_Heat : 35|1@0+ (1,0) [0|1] ""  DAPP
 SG_ NBCMU04_WorkState : 39|3@0+ (1,0) [0|7] ""  DAPP
 SG_ NBCMU04_SoftVer : 47|8@0+ (1,0) [0|255] ""  DAPP
 SG_ NBCMU04_HardVer : 55|8@0+ (1,0) [0|255] ""  DAPP
 SG_ NBCMU04_AliveCounter : 63|8@0+ (1,0) [0|255] ""  DAPP

BO_ 2561802148 NBCMU04_WarningInfo1: 8 NBCMU
 SG_ NBCMU04_HeatCurr : 7|12@0+ (0.1,-200) [-200|200] "A"  DAPP
 SG_ NBCMU04_SysFailSta : 9|2@0+ (1,0) [0|3] ""  DAPP
 SG_ NBCMU04_InsRes_polarity : 11|2@0+ (1,0) [0|3] ""  DAPP
 SG_ NBCMU04_BattVolt_HighWarning : 17|2@0+ (1,0) [0|3] ""  DAPP
 SG_ NBCMU04_BattVolt_LowWarning : 19|2@0+ (1,0) [0|3] ""  DAPP
 SG_ NBCMU04_CellVolt_HighWarning : 21|2@0+ (1,0) [0|3] ""  DAPP
 SG_ NBCMU04_CellVolt_LowWarning : 23|2@0+ (1,0) [0|3] ""  DAPP
 SG_ NBCMU04_ChrgTemp_HighWarning : 25|2@0+ (1,0) [0|3] ""  DAPP
 SG_ NBCMU04_ChrgTemp_LowWarning : 27|2@0+ (1,0) [0|3] ""  DAPP
 SG_ NBCMU04_DischrgTemp_HighWarning : 29|2@0+ (1,0) [0|3] ""  DAPP
 SG_ NBCMU04_DischrgTemp_LowWarning : 31|2@0+ (1,0) [0|3] ""  DAPP
 SG_ NBCMU04_TempDiff_Warning : 33|2@0+ (1,0) [0|3] ""  DAPP
 SG_ NBCMU04_CellVoltDiff_Warning : 35|2@0+ (1,0) [0|3] ""  DAPP
 SG_ NBCMU04_DischrgCurr_OverWarning : 37|2@0+ (1,0) [0|3] ""  DAPP
 SG_ NBCMU04_ChrgCurr_OverWarning : 39|2@0+ (1,0) [0|3] ""  DAPP
 SG_ NBCMU04_InsulationWarning : 41|2@0+ (1,0) [0|3] ""  DAPP
 SG_ NBCMU04_SOC_LowWarning : 43|2@0+ (1,0) [0|3] ""  DAPP
 SG_ NBCMU04_AmbientTemp_HighWarning : 45|2@0+ (1,0) [0|3] ""  DAPP
 SG_ NBCMU04_AmbientTemp_LowWarning : 47|2@0+ (1,0) [0|3] ""  DAPP
 SG_ NBCMU04_ContactorPosi_Fault : 49|2@0+ (1,0) [0|3] ""  DAPP
 SG_ NBCMU04_ContactorNega_Fault : 51|2@0+ (1,0) [0|3] ""  DAPP
 SG_ NBCMU04_ContactorBalan_Fault : 53|2@0+ (1,0) [0|3] ""  DAPP
 SG_ NBCMU04_ContactorHeat_Fault : 55|2@0+ (1,0) [0|3] ""  DAPP
 SG_ NBCMU04_CurrSensor_TimeOut : 57|1@0+ (1,0) [0|1] ""  DAPP
 SG_ NBCMU04_SOH_LowWarning : 59|2@0+ (1,0) [0|3] ""  DAPP
 SG_ NBCMU04_HVIL_Fault : 62|1@0+ (1,0) [0|1] ""  DAPP
 SG_ NBCMU04_Fuse_Fault : 63|1@0+ (1,0) [0|1] ""  DAPP

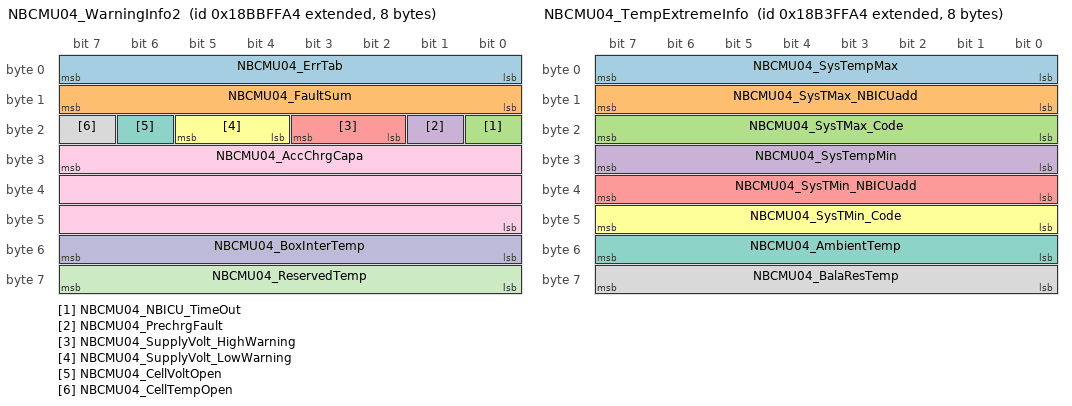
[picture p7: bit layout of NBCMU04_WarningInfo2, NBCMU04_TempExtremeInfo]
BO_ 2562457508 NBCMU04_WarningInfo2: 8 NBCMU
 SG_ NBCMU04_ErrTab : 7|8@0+ (1,0) [0|255] ""  DAPP
 SG_ NBCMU04_FaultSum : 15|8@0+ (1,0) [0|255] ""  DAPP
 SG_ NBCMU04_NBICU_TimeOut : 16|1@0+ (1,0) [0|1] ""  DAPP
 SG_ NBCMU04_PrechrgFault : 17|1@0+ (1,0) [0|1] ""  DAPP
 SG_ NBCMU04_SupplyVolt_HighWarning : 19|2@0+ (1,0) [0|3] ""  DAPP
 SG_ NBCMU04_SupplyVolt_LowWarning : 21|2@0+ (1,0) [0|3] ""  DAPP
 SG_ NBCMU04_CellVoltOpen : 22|1@0+ (1,0) [0|1] ""  DAPP
 SG_ NBCMU04_CellTempOpen : 23|1@0+ (1,0) [0|1] ""  DAPP
 SG_ NBCMU04_AccChrgCapa : 31|24@0+ (1,0) [0|16777215] "Ah"  DAPP
 SG_ NBCMU04_BoxInterTemp : 55|8@0+ (1,-40) [-40|215] "℃"  DAPP
 SG_ NBCMU04_ReservedTemp : 63|8@0+ (1,-40) [-40|215] "℃"  DAPP

BO_ 2561867684 NBCMU04_VoltExtremeInfo: 8 NBCMU
 SG_ NBCMU04_SysCellVoltMax : 7|16@0+ (1,0) [0|65535] "mV"  DAPP
 SG_ NBCMU04_SysVMax_NBICUadd : 23|8@0+ (1,0) [0|255] ""  DAPP
 SG_ NBCMU04_SysVMax_Code : 31|8@0+ (1,0) [0|255] ""  DAPP
 SG_ NBCMU04_SysCellVoltMin : 39|16@0+ (1,0) [0|65535] "mV"  DAPP
 SG_ NBCMU04_SysVMin_NBICUadd : 55|8@0+ (1,0) [0|255] ""  DAPP
 SG_ NBCMU04_SysVMin_Code : 63|8@0+ (1,0) [0|255] ""  DAPP

BO_ 2561933220 NBCMU04_TempExtremeInfo: 8 NBCMU
 SG_ NBCMU04_SysTempMax : 7|8@0+ (1,-40) [-40|215] "℃"  DAPP
 SG_ NBCMU04_SysTMax_NBICUadd : 15|8@0+ (1,0) [0|255] ""  DAPP
 SG_ NBCMU04_SysTMax_Code : 23|8@0+ (1,0) [0|255] ""  DAPP
 SG_ NBCMU04_SysTempMin : 31|8@0+ (1,-40) [-40|215] "℃"  DAPP
 SG_ NBCMU04_SysTMin_NBICUadd : 39|8@0+ (1,0) [0|255] ""  DAPP
 SG_ NBCMU04_SysTMin_Code : 47|8@0+ (1,0) [0|255] ""  DAPP
 SG_ NBCMU04_AmbientTemp : 55|8@0+ (1,-40) [-40|215] "℃"  DAPP
 SG_ NBCMU04_BalaResTemp : 63|8@0+ (1,-40) [-40|215] "℃"  DAPP

BO_ 2561998756 NBCMU04_SysSOX: 8 NBCMU
 SG_ NBCMU04_SysSOC_Actl : 7|16@0+ (0.1,0) [0|65535] "%"  DAPP
 SG_ NBCMU04_SysSOC_Dis : 23|16@0+ (0.1,0) [0|65535] "%"  DAPP
 SG_ NBCMU04_SysSOH_ByNBICU : 39|8@0+ (1,0) [0|255] "%"  DAPP
 SG_ NBCMU04_SysSOH_Cal : 47|8@0+ (1,0) [0|255] "%"  DAPP
 SG_ NBCMU04_SysSOE : 55|16@0+ (0.1,0) [0|6553.5] "%"  DAPP

BO_ 2562064292 NBCMU04_SysHVoltage: 8 NBCMU
 SG_ NBCMU04_SysHVoltage : 7|16@0+ (0.1,0) [0|6553.5] "V"  DAPP
 SG_ NBCMU04_SysSumVoltage : 23|16@0+ (0.1,0) [0|6553.5] "V"  DAPP
 SG_ NBCMU04_SysSampVoltage : 39|16@0+ (0.1,0) [0|6553.5] "V"  DAPP
 SG_ NBCMU04_SysInsRes : 55|16@0+ (1,0) [0|65535] "KΩ"  DAPP

BO_ 2562195364 NBCMU04_DischrgChrg: 8 NBCMU
 SG_ NBCMU04_MaxConDisCurnt : 7|16@0+ (0.1,0) [0|6553.5] "A"  DAPP
 SG_ NBCMU04_MaxConChrgCurnt : 23|16@0+ (0.1,0) [0|6553.5] "A"  DAPP
 SG_ NBCMU04_MaxInstanDisCurnt : 39|16@0+ (0.1,0) [0|6553.5] "A"  DAPP
 SG_ NBCMU04_MaxInstanChrgCurnt : 55|16@0+ (0.1,0) [0|6553.5] "A"  DAPP

BO_ 2560884644 NBCMU04_WarningInfo3: 8 NBCMU
 SG_ NBCMU04_SumVolt_HighWarning : 1|2@0+ (1,0) [0|3] ""  SBCMU,DAPP
 SG_ NBCMU04_SumVolt_LowWarning : 3|2@0+ (1,0) [0|3] ""  SBCMU,DAPP
 SG_ NBCMU04_CurrentLoop_HighWarning : 8|1@0+ (1,0) [0|1] ""  SBCMU,DAPP
 SG_ NBCMU04_ProtectFault : 9|1@0+ (1,0) [0|1] ""  SBCMU,DAPP
 SG_ NBCMU04_RunLed_State : 10|1@0+ (1,0) [0|1] ""  SBCMU,DAPP
 SG_ NBCMU04_Buzz_State : 11|1@0+ (1,0) [0|1] ""  SBCMU,DAPP
 SG_ NBCMU04_Heating_State : 12|1@0+ (1,0) [0|1] ""  SBCMU,DAPP
 SG_ NBCMU04_Cooling_State : 13|1@0+ (1,0) [0|1] ""  SBCMU,DAPP
 SG_ NBCMU04_BattVoltDiff_Warning : 14|1@0+ (1,0) [0|1] ""  SBCMU,DAPP
 SG_ NBCMU04_EmergyShutdown_Fault : 15|1@0+ (1,0) [0|1] ""  SBCMU,DAPP
 SG_ NBCMU04_PCS_TimeOut : 16|1@0+ (1,0) [0|1] ""  SBCMU,DAPP
 SG_ NBCMU04_EMS_TimeOut : 17|1@0+ (1,0) [0|1] ""  SBCMU,DAPP
 SG_ NBCMU04_TMS_TimeOut : 18|1@0+ (1,0) [0|1] ""  SBCMU,DAPP
 SG_ NBCMU04_SBCMU01_TimeOut : 19|1@0+ (1,0) [0|1] ""  SBCMU,DAPP
 SG_ NBCMU04_InitialFault : 30|1@0+ (1,0) [0|1] ""  SBCMU,DAPP
 SG_ NBCMU04_ThermalManagement_Fault : 31|1@0+ (1,0) [0|3] ""  SBCMU,DAPP
 SG_ NBCMU04_DCS_ActOprtMode : 26|3@0+ (1,0) [0|7] ""  SBCMU,DAPP
 SG_ NBCMU04_ChrgFault : 27|1@0+ (1,0) [0|1] ""  SBCMU,DAPP
 SG_ NBCMU04_DC_ChrgEnable : 28|1@0+ (1,0) [0|1] ""  SBCMU,DAPP
 SG_ NBCMU04_Contactor_DC_Cmd : 29|1@0+ (1,0) [0|1] ""  SBCMU,DAPP
 SG_ NBCMU04_MaxAllowChrgCur_DC : 39|16@0+ (0.1,0) [0|6553.5] "A"  SBCMU,DAPP
 SG_ NBCMU04_MaxAllowChrgVol_DC : 55|16@0+ (0.1,0) [0|6553.5] "V"  SBCMU,DAPP

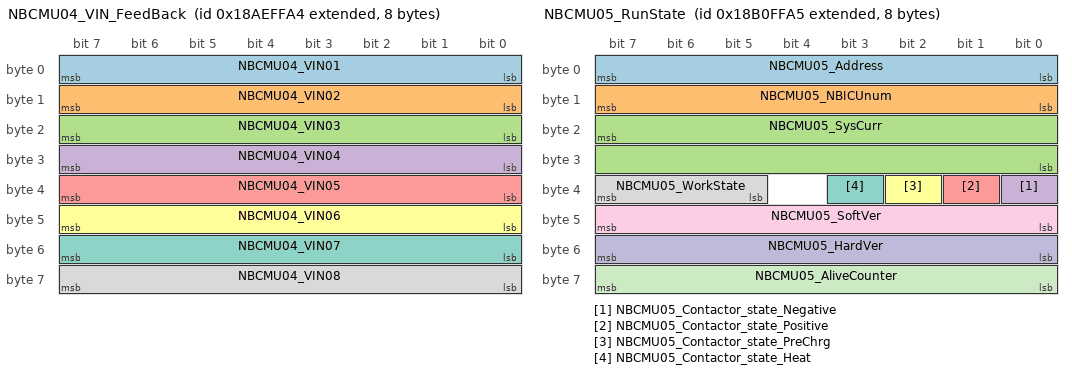
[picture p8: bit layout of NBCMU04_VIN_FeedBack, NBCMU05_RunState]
BO_ 2561605540 NBCMU04_VIN_FeedBack: 8 NBCMU
 SG_ NBCMU04_VIN01 : 7|8@0+ (1,0) [0|255] ""  DAPP
 SG_ NBCMU04_VIN02 : 15|8@0+ (1,0) [0|255] ""  DAPP
 SG_ NBCMU04_VIN03 : 23|8@0+ (1,0) [0|255] ""  DAPP
 SG_ NBCMU04_VIN04 : 31|8@0+ (1,0) [0|255] ""  DAPP
 SG_ NBCMU04_VIN05 : 39|8@0+ (1,0) [0|155] ""  DAPP
 SG_ NBCMU04_VIN06 : 47|8@0+ (1,0) [0|255] ""  DAPP
 SG_ NBCMU04_VIN07 : 55|8@0+ (1,0) [0|255] ""  DAPP
 SG_ NBCMU04_VIN08 : 63|8@0+ (1,0) [0|255] ""  DAPP

BO_ 2564947876 NBCMU04_SW_Info: 8 NBCMU
 SG_ NBCMU04_SW01 : 15|8@0+ (1,0) [0|255] ""  DAPP
 SG_ NBCMU04_SW02 : 23|8@0+ (1,0) [0|255] ""  DAPP
 SG_ NBCMU04_SW03 : 31|8@0+ (1,0) [0|255] ""  DAPP
 SG_ NBCMU04_SW04 : 39|8@0+ (1,0) [0|255] ""  DAPP
 SG_ NBCMU04_SW05 : 47|8@0+ (1,0) [0|255] ""  DAPP
 SG_ NBCMU04_SW06 : 55|8@0+ (1,0) [0|255] ""  DAPP
 SG_ NBCMU04_SW07 : 63|8@0+ (1,0) [0|255] ""  DAPP

BO_ 2565013412 NBCMU04_HW_Info: 8 NBCMU
 SG_ NBCMU04_HW01 : 15|8@0+ (1,0) [0|255] ""  DAPP
 SG_ NBCMU04_HW02 : 23|8@0+ (1,0) [0|255] ""  DAPP
 SG_ NBCMU04_HW03 : 31|8@0+ (1,0) [0|255] ""  DAPP
 SG_ NBCMU04_HW04 : 39|8@0+ (1,0) [0|255] ""  DAPP
 SG_ NBCMU04_HW05 : 47|8@0+ (1,0) [0|255] ""  DAPP
 SG_ NBCMU04_HW06 : 55|8@0+ (1,0) [0|255] ""  DAPP
 SG_ NBCMU04_HW07 : 63|8@0+ (1,0) [0|255] ""  DAPP

BO_ 2561736613 NBCMU05_RunState: 8 NBCMU
 SG_ NBCMU05_Address : 7|8@0+ (1,0) [0|255] ""  DAPP
 SG_ NBCMU05_NBICUnum : 15|8@0+ (1,0) [0|255] ""  DAPP
 SG_ NBCMU05_SysCurr : 23|16@0+ (0.1,-3000) [-3000|3000] "A"  DAPP
 SG_ NBCMU05_Contactor_state_Negative : 32|1@0+ (1,0) [0|1] ""  DAPP
 SG_ NBCMU05_Contactor_state_Positive : 33|1@0+ (1,0) [0|1] ""  DAPP
 SG_ NBCMU05_Contactor_state_PreChrg : 34|1@0+ (1,0) [0|1] ""  DAPP
 SG_ NBCMU05_Contactor_state_Heat : 35|1@0+ (1,0) [0|1] ""  DAPP
 SG_ NBCMU05_WorkState : 39|3@0+ (1,0) [0|7] ""  DAPP
 SG_ NBCMU05_SoftVer : 47|8@0+ (1,0) [0|255] ""  DAPP
 SG_ NBCMU05_HardVer : 55|8@0+ (1,0) [0|255] ""  DAPP
 SG_ NBCMU05_AliveCounter : 63|8@0+ (1,0) [0|255] ""  DAPP

BO_ 2561802149 NBCMU05_WarningInfo1: 8 NBCMU
 SG_ NBCMU05_HeatCurr : 7|12@0+ (0.1,-200) [-200|200] "A"  DAPP
 SG_ NBCMU05_SysFailSta : 9|2@0+ (1,0) [0|3] ""  DAPP
 SG_ NBCMU05_InsRes_polarity : 11|2@0+ (1,0) [0|3] ""  DAPP
 SG_ NBCMU05_BattVolt_HighWarning : 17|2@0+ (1,0) [0|3] ""  DAPP
 SG_ NBCMU05_BattVolt_LowWarning : 19|2@0+ (1,0) [0|3] ""  DAPP
 SG_ NBCMU05_CellVolt_HighWarning : 21|2@0+ (1,0) [0|3] ""  DAPP
 SG_ NBCMU05_CellVolt_LowWarning : 23|2@0+ (1,0) [0|3] ""  DAPP
 SG_ NBCMU05_ChrgTemp_HighWarning : 25|2@0+ (1,0) [0|3] ""  DAPP
 SG_ NBCMU05_ChrgTemp_LowWarning : 27|2@0+ (1,0) [0|3] ""  DAPP
 SG_ NBCMU05_DischrgTemp_HighWarning : 29|2@0+ (1,0) [0|3] ""  DAPP
 SG_ NBCMU05_DischrgTemp_LowWarning : 31|2@0+ (1,0) [0|3] ""  DAPP
 SG_ NBCMU05_TempDiff_Warning : 33|2@0+ (1,0) [0|3] ""  DAPP
 SG_ NBCMU05_CellVoltDiff_Warning : 35|2@0+ (1,0) [0|3] ""  DAPP
 SG_ NBCMU05_DischrgCurr_OverWarning : 37|2@0+ (1,0) [0|3] ""  DAPP
 SG_ NBCMU05_ChrgCurr_OverWarning : 39|2@0+ (1,0) [0|3] ""  DAPP
 SG_ NBCMU05_InsulationWarning : 41|2@0+ (1,0) [0|3] ""  DAPP
 SG_ NBCMU05_SOC_LowWarning : 43|2@0+ (1,0) [0|3] ""  DAPP
 SG_ NBCMU05_AmbientTemp_HighWarning : 45|2@0+ (1,0) [0|3] ""  DAPP
 SG_ NBCMU05_AmbientTemp_LowWarning : 47|2@0+ (1,0) [0|3] ""  DAPP
 SG_ NBCMU05_ContactorPosi_Fault : 49|2@0+ (1,0) [0|3] ""  DAPP
 SG_ NBCMU05_ContactorNega_Fault : 51|2@0+ (1,0) [0|3] ""  DAPP
 SG_ NBCMU05_ContactorBalan_Fault : 53|2@0+ (1,0) [0|3] ""  DAPP
 SG_ NBCMU05_ContactorHeat_Fault : 55|2@0+ (1,0) [0|3] ""  DAPP
 SG_ NBCMU05_CurrSensor_TimeOut : 57|1@0+ (1,0) [0|1] ""  DAPP
 SG_ NBCMU05_SOH_LowWarning : 59|2@0+ (1,0) [0|3] ""  DAPP
 SG_ NBCMU05_HVIL_Fault : 62|1@0+ (1,0) [0|1] ""  DAPP
 SG_ NBCMU05_Fuse_Fault : 63|1@0+ (1,0) [0|1] ""  DAPP

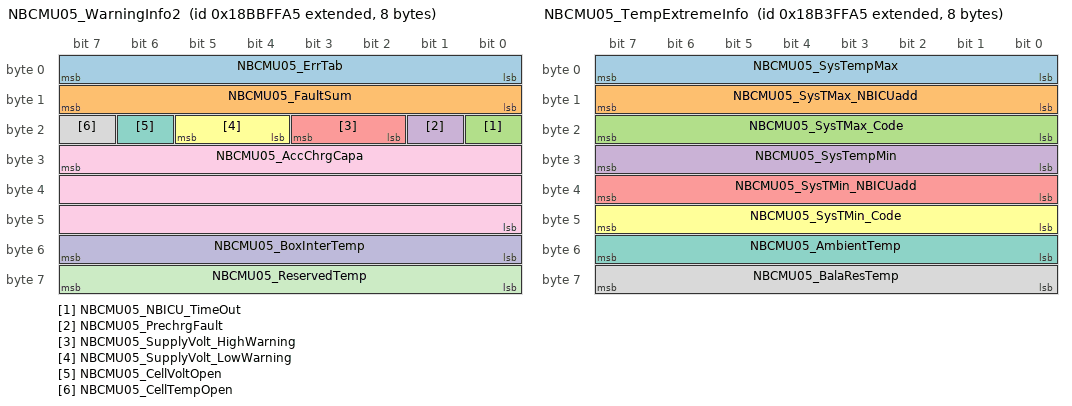
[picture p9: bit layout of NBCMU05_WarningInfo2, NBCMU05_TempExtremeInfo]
BO_ 2562457509 NBCMU05_WarningInfo2: 8 NBCMU
 SG_ NBCMU05_ErrTab : 7|8@0+ (1,0) [0|255] ""  DAPP
 SG_ NBCMU05_FaultSum : 15|8@0+ (1,0) [0|255] ""  DAPP
 SG_ NBCMU05_NBICU_TimeOut : 16|1@0+ (1,0) [0|1] ""  DAPP
 SG_ NBCMU05_PrechrgFault : 17|1@0+ (1,0) [0|1] ""  DAPP
 SG_ NBCMU05_SupplyVolt_HighWarning : 19|2@0+ (1,0) [0|3] ""  DAPP
 SG_ NBCMU05_SupplyVolt_LowWarning : 21|2@0+ (1,0) [0|3] ""  DAPP
 SG_ NBCMU05_CellVoltOpen : 22|1@0+ (1,0) [0|1] ""  DAPP
 SG_ NBCMU05_CellTempOpen : 23|1@0+ (1,0) [0|1] ""  DAPP
 SG_ NBCMU05_AccChrgCapa : 31|24@0+ (1,0) [0|16777215] "Ah"  DAPP
 SG_ NBCMU05_BoxInterTemp : 55|8@0+ (1,-40) [-40|215] "℃"  DAPP
 SG_ NBCMU05_ReservedTemp : 63|8@0+ (1,-40) [-40|215] "℃"  DAPP

BO_ 2561867685 NBCMU05_VoltExtremeInfo: 8 NBCMU
 SG_ NBCMU05_SysCellVoltMax : 7|16@0+ (1,0) [0|65535] "mV"  DAPP
 SG_ NBCMU05_SysVMax_NBICUadd : 23|8@0+ (1,0) [0|255] ""  DAPP
 SG_ NBCMU05_SysVMax_Code : 31|8@0+ (1,0) [0|255] ""  DAPP
 SG_ NBCMU05_SysCellVoltMin : 39|16@0+ (1,0) [0|65535] "mV"  DAPP
 SG_ NBCMU05_SysVMin_NBICUadd : 55|8@0+ (1,0) [0|255] ""  DAPP
 SG_ NBCMU05_SysVMin_Code : 63|8@0+ (1,0) [0|255] ""  DAPP

BO_ 2561933221 NBCMU05_TempExtremeInfo: 8 NBCMU
 SG_ NBCMU05_SysTempMax : 7|8@0+ (1,-40) [-40|215] "℃"  DAPP
 SG_ NBCMU05_SysTMax_NBICUadd : 15|8@0+ (1,0) [0|255] ""  DAPP
 SG_ NBCMU05_SysTMax_Code : 23|8@0+ (1,0) [0|255] ""  DAPP
 SG_ NBCMU05_SysTempMin : 31|8@0+ (1,-40) [-40|215] "℃"  DAPP
 SG_ NBCMU05_SysTMin_NBICUadd : 39|8@0+ (1,0) [0|255] ""  DAPP
 SG_ NBCMU05_SysTMin_Code : 47|8@0+ (1,0) [0|255] ""  DAPP
 SG_ NBCMU05_AmbientTemp : 55|8@0+ (1,-40) [-40|215] "℃"  DAPP
 SG_ NBCMU05_BalaResTemp : 63|8@0+ (1,-40) [-40|215] "℃"  DAPP

BO_ 2561998757 NBCMU05_SysSOX: 8 NBCMU
 SG_ NBCMU05_SysSOC_Actl : 7|16@0+ (0.1,0) [0|65535] "%"  DAPP
 SG_ NBCMU05_SysSOC_Dis : 23|16@0+ (0.1,0) [0|65535] "%"  DAPP
 SG_ NBCMU05_SysSOH_ByNBICU : 39|8@0+ (1,0) [0|255] "%"  DAPP
 SG_ NBCMU05_SysSOH_Cal : 47|8@0+ (1,0) [0|255] "%"  DAPP
 SG_ NBCMU05_SysSOE : 55|16@0+ (0.1,0) [0|6553.5] "%"  DAPP

BO_ 2562064293 NBCMU05_SysHVoltage: 8 NBCMU
 SG_ NBCMU05_SysHVoltage : 7|16@0+ (0.1,0) [0|6553.5] "V"  DAPP
 SG_ NBCMU05_SysSumVoltage : 23|16@0+ (0.1,0) [0|6553.5] "V"  DAPP
 SG_ NBCMU05_SysSampVoltage : 39|16@0+ (0.1,0) [0|6553.5] "V"  DAPP
 SG_ NBCMU05_SysInsRes : 55|16@0+ (1,0) [0|65535] "KΩ"  DAPP

BO_ 2562195365 NBCMU05_DischrgChrg: 8 NBCMU
 SG_ NBCMU05_MaxConDisCurnt : 7|16@0+ (0.1,0) [0|6553.5] "A"  DAPP
 SG_ NBCMU05_MaxConChrgCurnt : 23|16@0+ (0.1,0) [0|6553.5] "A"  DAPP
 SG_ NBCMU05_MaxInstanDisCurnt : 39|16@0+ (0.1,0) [0|6553.5] "A"  DAPP
 SG_ NBCMU05_MaxInstanChrgCurnt : 55|16@0+ (0.1,0) [0|6553.5] "A"  DAPP

BO_ 2560884645 NBCMU05_WarningInfo3: 8 NBCMU
 SG_ NBCMU05_SumVolt_HighWarning : 1|2@0+ (1,0) [0|3] ""  SBCMU,DAPP
 SG_ NBCMU05_SumVolt_LowWarning : 3|2@0+ (1,0) [0|3] ""  SBCMU,DAPP
 SG_ NBCMU05_CurrentLoop_HighWarning : 8|1@0+ (1,0) [0|1] ""  SBCMU,DAPP
 SG_ NBCMU05_ProtectFault : 9|1@0+ (1,0) [0|1] ""  SBCMU,DAPP
 SG_ NBCMU05_RunLed_State : 10|1@0+ (1,0) [0|1] ""  SBCMU,DAPP
 SG_ NBCMU05_Buzz_State : 11|1@0+ (1,0) [0|1] ""  SBCMU,DAPP
 SG_ NBCMU05_Heating_State : 12|1@0+ (1,0) [0|1] ""  SBCMU,DAPP
 SG_ NBCMU05_Cooling_State : 13|1@0+ (1,0) [0|1] ""  SBCMU,DAPP
 SG_ NBCMU05_BattVoltDiff_Warning : 14|1@0+ (1,0) [0|1] ""  SBCMU,DAPP
 SG_ NBCMU05_EmergyShutdown_Fault : 15|1@0+ (1,0) [0|1] ""  SBCMU,DAPP
 SG_ NBCMU05_PCS_TimeOut : 16|1@0+ (1,0) [0|1] ""  SBCMU,DAPP
 SG_ NBCMU05_EMS_TimeOut : 17|1@0+ (1,0) [0|1] ""  SBCMU,DAPP
 SG_ NBCMU05_TMS_TimeOut : 18|1@0+ (1,0) [0|1] ""  SBCMU,DAPP
 SG_ NBCMU05_SBCMU01_TimeOut : 19|1@0+ (1,0) [0|1] ""  SBCMU,DAPP
 SG_ NBCMU05_InitialFault : 30|1@0+ (1,0) [0|1] ""  SBCMU,DAPP
 SG_ NBCMU05_ThermalManagement_Fault : 31|1@0+ (1,0) [0|3] ""  SBCMU,DAPP
 SG_ NBCMU05_DCS_ActOprtMode : 26|3@0+ (1,0) [0|7] ""  SBCMU,DAPP
 SG_ NBCMU05_ChrgFault : 27|1@0+ (1,0) [0|1] ""  SBCMU,DAPP
 SG_ NBCMU05_DC_ChrgEnable : 28|1@0+ (1,0) [0|1] ""  SBCMU,DAPP
 SG_ NBCMU05_Contactor_DC_Cmd : 29|1@0+ (1,0) [0|1] ""  SBCMU,DAPP
 SG_ NBCMU05_MaxAllowChrgCur_DC : 39|16@0+ (0.1,0) [0|6553.5] "A"  SBCMU,DAPP
 SG_ NBCMU05_MaxAllowChrgVol_DC : 55|16@0+ (0.1,0) [0|6553.5] "V"  SBCMU,DAPP

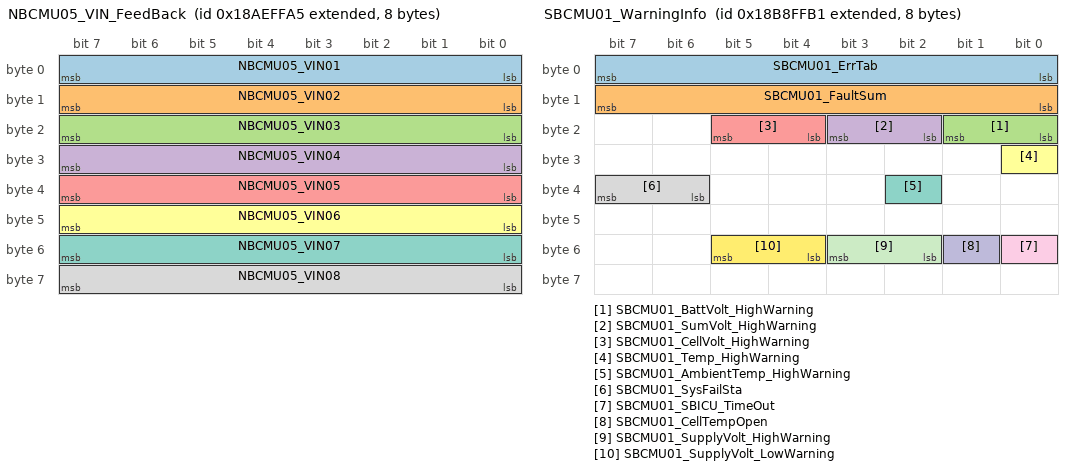
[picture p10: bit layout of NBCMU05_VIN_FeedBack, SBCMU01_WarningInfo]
BO_ 2561605541 NBCMU05_VIN_FeedBack: 8 NBCMU
 SG_ NBCMU05_VIN01 : 7|8@0+ (1,0) [0|255] ""  DAPP
 SG_ NBCMU05_VIN02 : 15|8@0+ (1,0) [0|255] ""  DAPP
 SG_ NBCMU05_VIN03 : 23|8@0+ (1,0) [0|255] ""  DAPP
 SG_ NBCMU05_VIN04 : 31|8@0+ (1,0) [0|255] ""  DAPP
 SG_ NBCMU05_VIN05 : 39|8@0+ (1,0) [0|155] ""  DAPP
 SG_ NBCMU05_VIN06 : 47|8@0+ (1,0) [0|255] ""  DAPP
 SG_ NBCMU05_VIN07 : 55|8@0+ (1,0) [0|255] ""  DAPP
 SG_ NBCMU05_VIN08 : 63|8@0+ (1,0) [0|255] ""  DAPP

BO_ 2564947877 NBCMU05_SW_Info: 8 NBCMU
 SG_ NBCMU05_SW01 : 15|8@0+ (1,0) [0|255] ""  DAPP
 SG_ NBCMU05_SW02 : 23|8@0+ (1,0) [0|255] ""  DAPP
 SG_ NBCMU05_SW03 : 31|8@0+ (1,0) [0|255] ""  DAPP
 SG_ NBCMU05_SW04 : 39|8@0+ (1,0) [0|255] ""  DAPP
 SG_ NBCMU05_SW05 : 47|8@0+ (1,0) [0|255] ""  DAPP
 SG_ NBCMU05_SW06 : 55|8@0+ (1,0) [0|255] ""  DAPP
 SG_ NBCMU05_SW07 : 63|8@0+ (1,0) [0|255] ""  DAPP

BO_ 2565013413 NBCMU05_HW_Info: 8 NBCMU
 SG_ NBCMU05_HW01 : 15|8@0+ (1,0) [0|255] ""  DAPP
 SG_ NBCMU05_HW02 : 23|8@0+ (1,0) [0|255] ""  DAPP
 SG_ NBCMU05_HW03 : 31|8@0+ (1,0) [0|255] ""  DAPP
 SG_ NBCMU05_HW04 : 39|8@0+ (1,0) [0|255] ""  DAPP
 SG_ NBCMU05_HW05 : 47|8@0+ (1,0) [0|255] ""  DAPP
 SG_ NBCMU05_HW06 : 55|8@0+ (1,0) [0|255] ""  DAPP
 SG_ NBCMU05_HW07 : 63|8@0+ (1,0) [0|255] ""  DAPP

BO_ 2562326448 SBCMU_SBICU_Control: 8 SBCMU
 SG_ SBCMU_OnlineSBICUnum : 39|8@0+ (1,0) [0|255] ""  SBICU,DAPP
 SG_ SBCMU_SBICU_Address : 63|8@0+ (1,0) [0|255] ""  SBICU,DAPP

BO_ 2562260913 SBCMU01_WarningInfo: 8 SBCMU
 SG_ SBCMU01_ErrTab : 7|8@0+ (1,0) [0|255] ""  DAPP
 SG_ SBCMU01_FaultSum : 15|8@0+ (1,0) [0|255] ""  DAPP
 SG_ SBCMU01_BattVolt_HighWarning : 17|2@0+ (1,0) [0|3] ""  DAPP
 SG_ SBCMU01_SumVolt_HighWarning : 19|2@0+ (1,0) [0|3] ""  DAPP
 SG_ SBCMU01_CellVolt_HighWarning : 21|2@0+ (1,0) [0|3] ""  DAPP
 SG_ SBCMU01_Temp_HighWarning : 24|1@0+ (1,0) [0|1] ""  DAPP
 SG_ SBCMU01_AmbientTemp_HighWarning : 34|1@0+ (1,0) [0|1] ""  DAPP
 SG_ SBCMU01_SysFailSta : 39|2@0+ (1,0) [0|3] ""  DAPP
 SG_ SBCMU01_SBICU_TimeOut : 48|1@0+ (1,0) [0|1] ""  DAPP
 SG_ SBCMU01_CellTempOpen : 49|1@0+ (1,0) [0|1] ""  DAPP
 SG_ SBCMU01_SupplyVolt_HighWarning : 51|2@0+ (1,0) [0|3] ""  DAPP
 SG_ SBCMU01_SupplyVolt_LowWarning : 53|2@0+ (1,0) [0|3] ""  DAPP

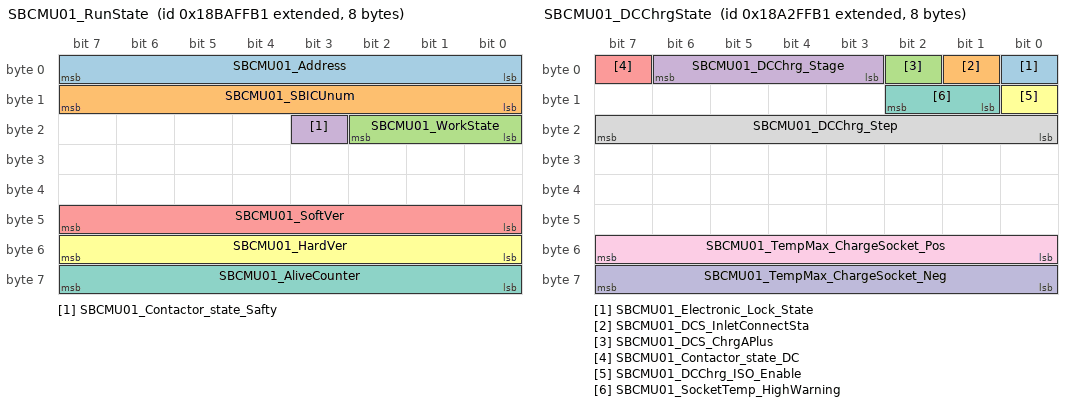
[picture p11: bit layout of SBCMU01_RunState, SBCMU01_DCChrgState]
BO_ 2562391985 SBCMU01_RunState: 8 SBCMU
 SG_ SBCMU01_Address : 7|8@0+ (1,0) [0|255] ""  DAPP
 SG_ SBCMU01_SBICUnum : 15|8@0+ (1,0) [0|255] ""  DAPP
 SG_ SBCMU01_WorkState : 18|3@0+ (1,0) [0|7] ""  DAPP
 SG_ SBCMU01_Contactor_state_Safty : 19|1@0+ (1,0) [0|1] ""  DAPP
 SG_ SBCMU01_SoftVer : 47|8@0+ (1,0) [0|255] ""  DAPP
 SG_ SBCMU01_HardVer : 55|8@0+ (1,0) [0|255] ""  DAPP
 SG_ SBCMU01_AliveCounter : 63|8@0+ (1,0) [0|255] ""  DAPP

BO_ 2560819121 SBCMU01_DCChrgState: 8 SBCMU
 SG_ SBCMU01_Electronic_Lock_State : 0|1@0+ (1,0) [0|1] ""  NBCMU,DAPP
 SG_ SBCMU01_DCS_InletConnectSta : 1|1@0+ (1,0) [0|1] ""  NBCMU,DAPP
 SG_ SBCMU01_DCS_ChrgAPlus : 2|1@0+ (1,0) [0|1] ""  NBCMU,DAPP
 SG_ SBCMU01_DCChrg_Stage : 6|4@0+ (1,0) [0|15] ""  NBCMU,DAPP
 SG_ SBCMU01_Contactor_state_DC : 7|1@0+ (1,0) [0|1] ""  NBCMU,DAPP
 SG_ SBCMU01_DCChrg_ISO_Enable : 8|1@0+ (1,0) [0|1] ""  NBCMU,DAPP
 SG_ SBCMU01_SocketTemp_HighWarning : 10|2@0+ (1,0) [0|3] ""  NBCMU,DAPP
 SG_ SBCMU01_DCChrg_Step : 23|8@0+ (1,0) [0|255] ""  NBCMU,DAPP
 SG_ SBCMU01_TempMax_ChargeSocket_Pos : 55|8@0+ (1,-40) [-40|215] "℃"  NBCMU,DAPP
 SG_ SBCMU01_TempMax_ChargeSocket_Neg : 63|8@0+ (1,-40) [-40|215] "℃"  NBCMU,DAPP

BO_ 2564947889 SBCMU01_SW_Info: 8 SBCMU
 SG_ SBCMU01_SW01 : 15|8@0+ (1,0) [0|255] ""  DAPP
 SG_ SBCMU01_SW02 : 23|8@0+ (1,0) [0|255] ""  DAPP
 SG_ SBCMU01_SW03 : 31|8@0+ (1,0) [0|255] ""  DAPP
 SG_ SBCMU01_SW04 : 39|8@0+ (1,0) [0|255] ""  DAPP
 SG_ SBCMU01_SW05 : 47|8@0+ (1,0) [0|255] ""  DAPP
 SG_ SBCMU01_SW06 : 55|8@0+ (1,0) [0|255] ""  DAPP
 SG_ SBCMU01_SW07 : 63|8@0+ (1,0) [0|255] ""  DAPP

BO_ 2565013425 SBCMU01_HW_Info: 8 SBCMU
 SG_ SBCMU01_HW01 : 15|8@0+ (1,0) [0|255] ""  DAPP
 SG_ SBCMU01_HW02 : 23|8@0+ (1,0) [0|255] ""  DAPP
 SG_ SBCMU01_HW03 : 31|8@0+ (1,0) [0|255] ""  DAPP
 SG_ SBCMU01_HW04 : 39|8@0+ (1,0) [0|255] ""  DAPP
 SG_ SBCMU01_HW05 : 47|8@0+ (1,0) [0|255] ""  DAPP
 SG_ SBCMU01_HW06 : 55|8@0+ (1,0) [0|255] ""  DAPP
 SG_ SBCMU01_HW07 : 63|8@0+ (1,0) [0|255] ""  DAPP

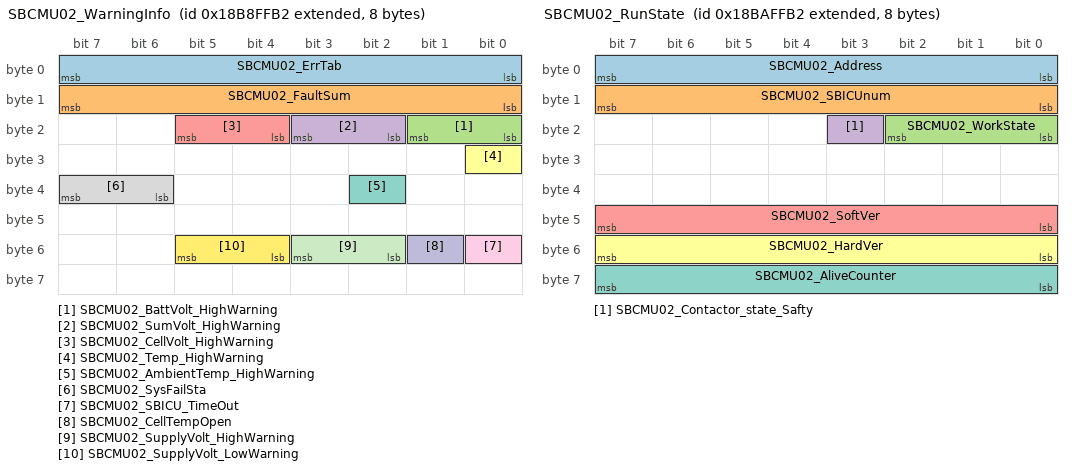
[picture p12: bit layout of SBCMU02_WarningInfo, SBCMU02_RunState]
BO_ 2562260914 SBCMU02_WarningInfo: 8 SBCMU
 SG_ SBCMU02_ErrTab : 7|8@0+ (1,0) [0|255] ""  DAPP
 SG_ SBCMU02_FaultSum : 15|8@0+ (1,0) [0|255] ""  DAPP
 SG_ SBCMU02_BattVolt_HighWarning : 17|2@0+ (1,0) [0|3] ""  DAPP
 SG_ SBCMU02_SumVolt_HighWarning : 19|2@0+ (1,0) [0|3] ""  DAPP
 SG_ SBCMU02_CellVolt_HighWarning : 21|2@0+ (1,0) [0|3] ""  DAPP
 SG_ SBCMU02_Temp_HighWarning : 24|1@0+ (1,0) [0|1] ""  DAPP
 SG_ SBCMU02_AmbientTemp_HighWarning : 34|1@0+ (1,0) [0|1] ""  DAPP
 SG_ SBCMU02_SysFailSta : 39|2@0+ (1,0) [0|3] ""  DAPP
 SG_ SBCMU02_SBICU_TimeOut : 48|1@0+ (1,0) [0|1] ""  DAPP
 SG_ SBCMU02_CellTempOpen : 49|1@0+ (1,0) [0|1] ""  DAPP
 SG_ SBCMU02_SupplyVolt_HighWarning : 51|2@0+ (1,0) [0|3] ""  DAPP
 SG_ SBCMU02_SupplyVolt_LowWarning : 53|2@0+ (1,0) [0|3] ""  DAPP

BO_ 2562391986 SBCMU02_RunState: 8 SBCMU
 SG_ SBCMU02_Address : 7|8@0+ (1,0) [0|255] ""  DAPP
 SG_ SBCMU02_SBICUnum : 15|8@0+ (1,0) [0|255] ""  DAPP
 SG_ SBCMU02_WorkState : 18|3@0+ (1,0) [0|7] ""  DAPP
 SG_ SBCMU02_Contactor_state_Safty : 19|1@0+ (1,0) [0|1] ""  DAPP
 SG_ SBCMU02_SoftVer : 47|8@0+ (1,0) [0|255] ""  DAPP
 SG_ SBCMU02_HardVer : 55|8@0+ (1,0) [0|255] ""  DAPP
 SG_ SBCMU02_AliveCounter : 63|8@0+ (1,0) [0|255] ""  DAPP

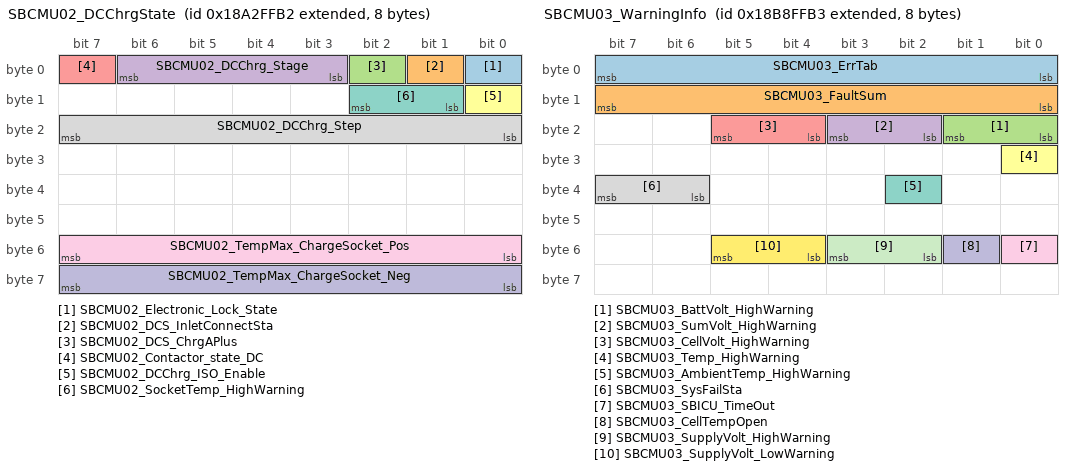
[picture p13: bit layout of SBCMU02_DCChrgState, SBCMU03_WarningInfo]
BO_ 2560819122 SBCMU02_DCChrgState: 8 SBCMU
 SG_ SBCMU02_Electronic_Lock_State : 0|1@0+ (1,0) [0|1] ""  NBCMU,DAPP
 SG_ SBCMU02_DCS_InletConnectSta : 1|1@0+ (1,0) [0|1] ""  NBCMU,DAPP
 SG_ SBCMU02_DCS_ChrgAPlus : 2|1@0+ (1,0) [0|1] ""  NBCMU,DAPP
 SG_ SBCMU02_DCChrg_Stage : 6|4@0+ (1,0) [0|15] ""  NBCMU,DAPP
 SG_ SBCMU02_Contactor_state_DC : 7|1@0+ (1,0) [0|1] ""  NBCMU,DAPP
 SG_ SBCMU02_DCChrg_ISO_Enable : 8|1@0+ (1,0) [0|1] ""  NBCMU,DAPP
 SG_ SBCMU02_SocketTemp_HighWarning : 10|2@0+ (1,0) [0|3] ""  NBCMU,DAPP
 SG_ SBCMU02_DCChrg_Step : 23|8@0+ (1,0) [0|255] ""  NBCMU,DAPP
 SG_ SBCMU02_TempMax_ChargeSocket_Pos : 55|8@0+ (1,-40) [-40|215] "℃"  NBCMU,DAPP
 SG_ SBCMU02_TempMax_ChargeSocket_Neg : 63|8@0+ (1,-40) [-40|215] "℃"  NBCMU,DAPP

BO_ 2564947890 SBCMU02_SW_Info: 8 SBCMU
 SG_ SBCMU02_SW01 : 15|8@0+ (1,0) [0|255] ""  DAPP
 SG_ SBCMU02_SW02 : 23|8@0+ (1,0) [0|255] ""  DAPP
 SG_ SBCMU02_SW03 : 31|8@0+ (1,0) [0|255] ""  DAPP
 SG_ SBCMU02_SW04 : 39|8@0+ (1,0) [0|255] ""  DAPP
 SG_ SBCMU02_SW05 : 47|8@0+ (1,0) [0|255] ""  DAPP
 SG_ SBCMU02_SW06 : 55|8@0+ (1,0) [0|255] ""  DAPP
 SG_ SBCMU02_SW07 : 63|8@0+ (1,0) [0|255] ""  DAPP

BO_ 2565013426 SBCMU02_HW_Info: 8 SBCMU
 SG_ SBCMU02_HW01 : 15|8@0+ (1,0) [0|255] ""  DAPP
 SG_ SBCMU02_HW02 : 23|8@0+ (1,0) [0|255] ""  DAPP
 SG_ SBCMU02_HW03 : 31|8@0+ (1,0) [0|255] ""  DAPP
 SG_ SBCMU02_HW04 : 39|8@0+ (1,0) [0|255] ""  DAPP
 SG_ SBCMU02_HW05 : 47|8@0+ (1,0) [0|255] ""  DAPP
 SG_ SBCMU02_HW06 : 55|8@0+ (1,0) [0|255] ""  DAPP
 SG_ SBCMU02_HW07 : 63|8@0+ (1,0) [0|255] ""  DAPP

BO_ 2562260915 SBCMU03_WarningInfo: 8 SBCMU
 SG_ SBCMU03_ErrTab : 7|8@0+ (1,0) [0|255] ""  DAPP
 SG_ SBCMU03_FaultSum : 15|8@0+ (1,0) [0|255] ""  DAPP
 SG_ SBCMU03_BattVolt_HighWarning : 17|2@0+ (1,0) [0|3] ""  DAPP
 SG_ SBCMU03_SumVolt_HighWarning : 19|2@0+ (1,0) [0|3] ""  DAPP
 SG_ SBCMU03_CellVolt_HighWarning : 21|2@0+ (1,0) [0|3] ""  DAPP
 SG_ SBCMU03_Temp_HighWarning : 24|1@0+ (1,0) [0|1] ""  DAPP
 SG_ SBCMU03_AmbientTemp_HighWarning : 34|1@0+ (1,0) [0|1] ""  DAPP
 SG_ SBCMU03_SysFailSta : 39|2@0+ (1,0) [0|3] ""  DAPP
 SG_ SBCMU03_SBICU_TimeOut : 48|1@0+ (1,0) [0|1] ""  DAPP
 SG_ SBCMU03_CellTempOpen : 49|1@0+ (1,0) [0|1] ""  DAPP
 SG_ SBCMU03_SupplyVolt_HighWarning : 51|2@0+ (1,0) [0|3] ""  DAPP
 SG_ SBCMU03_SupplyVolt_LowWarning : 53|2@0+ (1,0) [0|3] ""  DAPP

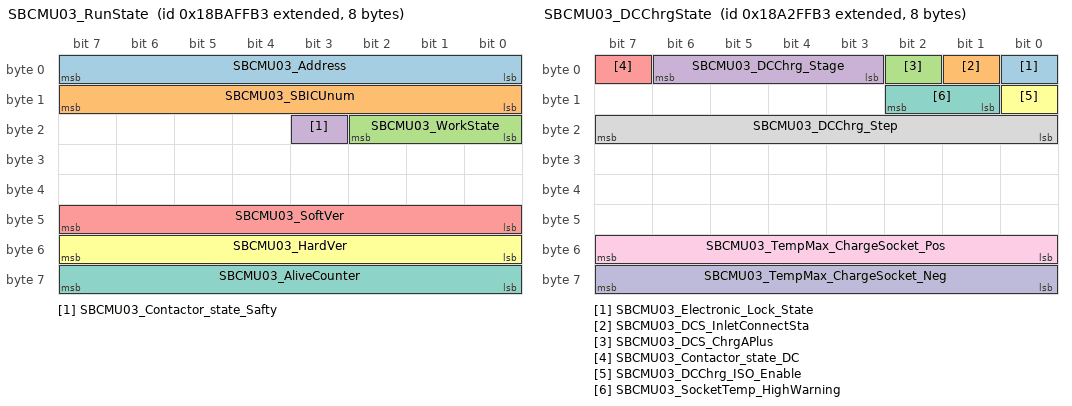
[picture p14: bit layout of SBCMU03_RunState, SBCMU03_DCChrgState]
BO_ 2562391987 SBCMU03_RunState: 8 SBCMU
 SG_ SBCMU03_Address : 7|8@0+ (1,0) [0|255] ""  DAPP
 SG_ SBCMU03_SBICUnum : 15|8@0+ (1,0) [0|255] ""  DAPP
 SG_ SBCMU03_WorkState : 18|3@0+ (1,0) [0|7] ""  DAPP
 SG_ SBCMU03_Contactor_state_Safty : 19|1@0+ (1,0) [0|1] ""  DAPP
 SG_ SBCMU03_SoftVer : 47|8@0+ (1,0) [0|255] ""  DAPP
 SG_ SBCMU03_HardVer : 55|8@0+ (1,0) [0|255] ""  DAPP
 SG_ SBCMU03_AliveCounter : 63|8@0+ (1,0) [0|255] ""  DAPP

BO_ 2560819123 SBCMU03_DCChrgState: 8 SBCMU
 SG_ SBCMU03_Electronic_Lock_State : 0|1@0+ (1,0) [0|1] ""  NBCMU,DAPP
 SG_ SBCMU03_DCS_InletConnectSta : 1|1@0+ (1,0) [0|1] ""  NBCMU,DAPP
 SG_ SBCMU03_DCS_ChrgAPlus : 2|1@0+ (1,0) [0|1] ""  NBCMU,DAPP
 SG_ SBCMU03_DCChrg_Stage : 6|4@0+ (1,0) [0|15] ""  NBCMU,DAPP
 SG_ SBCMU03_Contactor_state_DC : 7|1@0+ (1,0) [0|1] ""  NBCMU,DAPP
 SG_ SBCMU03_DCChrg_ISO_Enable : 8|1@0+ (1,0) [0|1] ""  NBCMU,DAPP
 SG_ SBCMU03_SocketTemp_HighWarning : 10|2@0+ (1,0) [0|3] ""  NBCMU,DAPP
 SG_ SBCMU03_DCChrg_Step : 23|8@0+ (1,0) [0|255] ""  NBCMU,DAPP
 SG_ SBCMU03_TempMax_ChargeSocket_Pos : 55|8@0+ (1,-40) [-40|215] "℃"  NBCMU,DAPP
 SG_ SBCMU03_TempMax_ChargeSocket_Neg : 63|8@0+ (1,-40) [-40|215] "℃"  NBCMU,DAPP

BO_ 2564947891 SBCMU03_SW_Info: 8 SBCMU
 SG_ SBCMU03_SW01 : 15|8@0+ (1,0) [0|255] ""  DAPP
 SG_ SBCMU03_SW02 : 23|8@0+ (1,0) [0|255] ""  DAPP
 SG_ SBCMU03_SW03 : 31|8@0+ (1,0) [0|255] ""  DAPP
 SG_ SBCMU03_SW04 : 39|8@0+ (1,0) [0|255] ""  DAPP
 SG_ SBCMU03_SW05 : 47|8@0+ (1,0) [0|255] ""  DAPP
 SG_ SBCMU03_SW06 : 55|8@0+ (1,0) [0|255] ""  DAPP
 SG_ SBCMU03_SW07 : 63|8@0+ (1,0) [0|255] ""  DAPP

BO_ 2565013427 SBCMU03_HW_Info: 8 SBCMU
 SG_ SBCMU03_HW01 : 15|8@0+ (1,0) [0|255] ""  DAPP
 SG_ SBCMU03_HW02 : 23|8@0+ (1,0) [0|255] ""  DAPP
 SG_ SBCMU03_HW03 : 31|8@0+ (1,0) [0|255] ""  DAPP
 SG_ SBCMU03_HW04 : 39|8@0+ (1,0) [0|255] ""  DAPP
 SG_ SBCMU03_HW05 : 47|8@0+ (1,0) [0|255] ""  DAPP
 SG_ SBCMU03_HW06 : 55|8@0+ (1,0) [0|255] ""  DAPP
 SG_ SBCMU03_HW07 : 63|8@0+ (1,0) [0|255] ""  DAPP

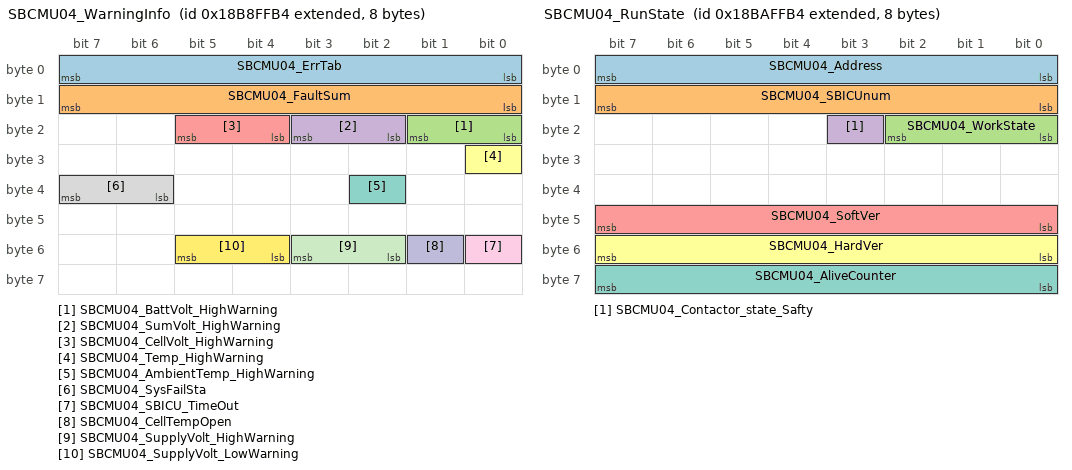
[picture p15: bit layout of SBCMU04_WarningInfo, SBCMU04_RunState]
BO_ 2562260916 SBCMU04_WarningInfo: 8 SBCMU
 SG_ SBCMU04_ErrTab : 7|8@0+ (1,0) [0|255] ""  DAPP
 SG_ SBCMU04_FaultSum : 15|8@0+ (1,0) [0|255] ""  DAPP
 SG_ SBCMU04_BattVolt_HighWarning : 17|2@0+ (1,0) [0|3] ""  DAPP
 SG_ SBCMU04_SumVolt_HighWarning : 19|2@0+ (1,0) [0|3] ""  DAPP
 SG_ SBCMU04_CellVolt_HighWarning : 21|2@0+ (1,0) [0|3] ""  DAPP
 SG_ SBCMU04_Temp_HighWarning : 24|1@0+ (1,0) [0|1] ""  DAPP
 SG_ SBCMU04_AmbientTemp_HighWarning : 34|1@0+ (1,0) [0|1] ""  DAPP
 SG_ SBCMU04_SysFailSta : 39|2@0+ (1,0) [0|3] ""  DAPP
 SG_ SBCMU04_SBICU_TimeOut : 48|1@0+ (1,0) [0|1] ""  DAPP
 SG_ SBCMU04_CellTempOpen : 49|1@0+ (1,0) [0|1] ""  DAPP
 SG_ SBCMU04_SupplyVolt_HighWarning : 51|2@0+ (1,0) [0|3] ""  DAPP
 SG_ SBCMU04_SupplyVolt_LowWarning : 53|2@0+ (1,0) [0|3] ""  DAPP

BO_ 2562391988 SBCMU04_RunState: 8 SBCMU
 SG_ SBCMU04_Address : 7|8@0+ (1,0) [0|255] ""  DAPP
 SG_ SBCMU04_SBICUnum : 15|8@0+ (1,0) [0|255] ""  DAPP
 SG_ SBCMU04_WorkState : 18|3@0+ (1,0) [0|7] ""  DAPP
 SG_ SBCMU04_Contactor_state_Safty : 19|1@0+ (1,0) [0|1] ""  DAPP
 SG_ SBCMU04_SoftVer : 47|8@0+ (1,0) [0|255] ""  DAPP
 SG_ SBCMU04_HardVer : 55|8@0+ (1,0) [0|255] ""  DAPP
 SG_ SBCMU04_AliveCounter : 63|8@0+ (1,0) [0|255] ""  DAPP

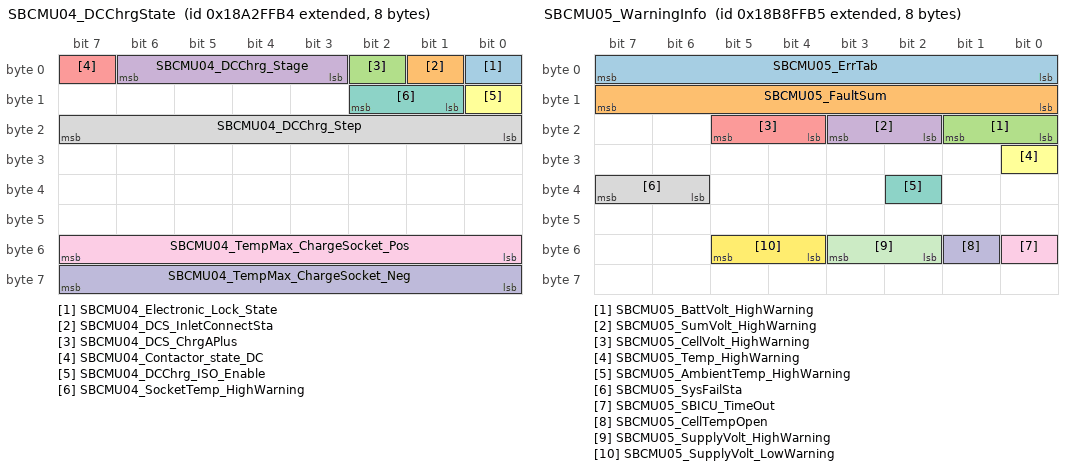
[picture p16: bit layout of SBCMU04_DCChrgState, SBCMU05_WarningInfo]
BO_ 2560819124 SBCMU04_DCChrgState: 8 SBCMU
 SG_ SBCMU04_Electronic_Lock_State : 0|1@0+ (1,0) [0|1] ""  NBCMU,DAPP
 SG_ SBCMU04_DCS_InletConnectSta : 1|1@0+ (1,0) [0|1] ""  NBCMU,DAPP
 SG_ SBCMU04_DCS_ChrgAPlus : 2|1@0+ (1,0) [0|1] ""  NBCMU,DAPP
 SG_ SBCMU04_DCChrg_Stage : 6|4@0+ (1,0) [0|15] ""  NBCMU,DAPP
 SG_ SBCMU04_Contactor_state_DC : 7|1@0+ (1,0) [0|1] ""  NBCMU,DAPP
 SG_ SBCMU04_DCChrg_ISO_Enable : 8|1@0+ (1,0) [0|1] ""  NBCMU,DAPP
 SG_ SBCMU04_SocketTemp_HighWarning : 10|2@0+ (1,0) [0|3] ""  NBCMU,DAPP
 SG_ SBCMU04_DCChrg_Step : 23|8@0+ (1,0) [0|255] ""  NBCMU,DAPP
 SG_ SBCMU04_TempMax_ChargeSocket_Pos : 55|8@0+ (1,-40) [-40|215] "℃"  NBCMU,DAPP
 SG_ SBCMU04_TempMax_ChargeSocket_Neg : 63|8@0+ (1,-40) [-40|215] "℃"  NBCMU,DAPP

BO_ 2564947892 SBCMU04_SW_Info: 8 SBCMU
 SG_ SBCMU04_SW01 : 15|8@0+ (1,0) [0|255] ""  DAPP
 SG_ SBCMU04_SW02 : 23|8@0+ (1,0) [0|255] ""  DAPP
 SG_ SBCMU04_SW03 : 31|8@0+ (1,0) [0|255] ""  DAPP
 SG_ SBCMU04_SW04 : 39|8@0+ (1,0) [0|255] ""  DAPP
 SG_ SBCMU04_SW05 : 47|8@0+ (1,0) [0|255] ""  DAPP
 SG_ SBCMU04_SW06 : 55|8@0+ (1,0) [0|255] ""  DAPP
 SG_ SBCMU04_SW07 : 63|8@0+ (1,0) [0|255] ""  DAPP

BO_ 2565013428 SBCMU04_HW_Info: 8 SBCMU
 SG_ SBCMU04_HW01 : 15|8@0+ (1,0) [0|255] ""  DAPP
 SG_ SBCMU04_HW02 : 23|8@0+ (1,0) [0|255] ""  DAPP
 SG_ SBCMU04_HW03 : 31|8@0+ (1,0) [0|255] ""  DAPP
 SG_ SBCMU04_HW04 : 39|8@0+ (1,0) [0|255] ""  DAPP
 SG_ SBCMU04_HW05 : 47|8@0+ (1,0) [0|255] ""  DAPP
 SG_ SBCMU04_HW06 : 55|8@0+ (1,0) [0|255] ""  DAPP
 SG_ SBCMU04_HW07 : 63|8@0+ (1,0) [0|255] ""  DAPP

BO_ 2562260917 SBCMU05_WarningInfo: 8 SBCMU
 SG_ SBCMU05_ErrTab : 7|8@0+ (1,0) [0|255] ""  DAPP
 SG_ SBCMU05_FaultSum : 15|8@0+ (1,0) [0|255] ""  DAPP
 SG_ SBCMU05_BattVolt_HighWarning : 17|2@0+ (1,0) [0|3] ""  DAPP
 SG_ SBCMU05_SumVolt_HighWarning : 19|2@0+ (1,0) [0|3] ""  DAPP
 SG_ SBCMU05_CellVolt_HighWarning : 21|2@0+ (1,0) [0|3] ""  DAPP
 SG_ SBCMU05_Temp_HighWarning : 24|1@0+ (1,0) [0|1] ""  DAPP
 SG_ SBCMU05_AmbientTemp_HighWarning : 34|1@0+ (1,0) [0|1] ""  DAPP
 SG_ SBCMU05_SysFailSta : 39|2@0+ (1,0) [0|3] ""  DAPP
 SG_ SBCMU05_SBICU_TimeOut : 48|1@0+ (1,0) [0|1] ""  DAPP
 SG_ SBCMU05_CellTempOpen : 49|1@0+ (1,0) [0|1] ""  DAPP
 SG_ SBCMU05_SupplyVolt_HighWarning : 51|2@0+ (1,0) [0|3] ""  DAPP
 SG_ SBCMU05_SupplyVolt_LowWarning : 53|2@0+ (1,0) [0|3] ""  DAPP

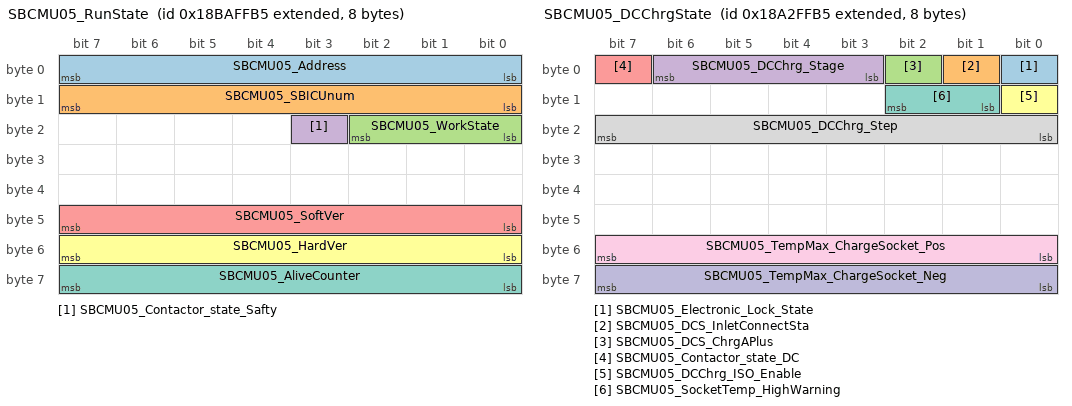
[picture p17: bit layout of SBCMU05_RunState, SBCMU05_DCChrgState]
BO_ 2562391989 SBCMU05_RunState: 8 SBCMU
 SG_ SBCMU05_Address : 7|8@0+ (1,0) [0|255] ""  DAPP
 SG_ SBCMU05_SBICUnum : 15|8@0+ (1,0) [0|255] ""  DAPP
 SG_ SBCMU05_WorkState : 18|3@0+ (1,0) [0|7] ""  DAPP
 SG_ SBCMU05_Contactor_state_Safty : 19|1@0+ (1,0) [0|1] ""  DAPP
 SG_ SBCMU05_SoftVer : 47|8@0+ (1,0) [0|255] ""  DAPP
 SG_ SBCMU05_HardVer : 55|8@0+ (1,0) [0|255] ""  DAPP
 SG_ SBCMU05_AliveCounter : 63|8@0+ (1,0) [0|255] ""  DAPP

BO_ 2560819125 SBCMU05_DCChrgState: 8 SBCMU
 SG_ SBCMU05_Electronic_Lock_State : 0|1@0+ (1,0) [0|1] ""  NBCMU,DAPP
 SG_ SBCMU05_DCS_InletConnectSta : 1|1@0+ (1,0) [0|1] ""  NBCMU,DAPP
 SG_ SBCMU05_DCS_ChrgAPlus : 2|1@0+ (1,0) [0|1] ""  NBCMU,DAPP
 SG_ SBCMU05_DCChrg_Stage : 6|4@0+ (1,0) [0|15] ""  NBCMU,DAPP
 SG_ SBCMU05_Contactor_state_DC : 7|1@0+ (1,0) [0|1] ""  NBCMU,DAPP
 SG_ SBCMU05_DCChrg_ISO_Enable : 8|1@0+ (1,0) [0|1] ""  NBCMU,DAPP
 SG_ SBCMU05_SocketTemp_HighWarning : 10|2@0+ (1,0) [0|3] ""  NBCMU,DAPP
 SG_ SBCMU05_DCChrg_Step : 23|8@0+ (1,0) [0|255] ""  NBCMU,DAPP
 SG_ SBCMU05_TempMax_ChargeSocket_Pos : 55|8@0+ (1,-40) [-40|215] "℃"  NBCMU,DAPP
 SG_ SBCMU05_TempMax_ChargeSocket_Neg : 63|8@0+ (1,-40) [-40|215] "℃"  NBCMU,DAPP

BO_ 2564947893 SBCMU05_SW_Info: 8 SBCMU
 SG_ SBCMU05_SW01 : 15|8@0+ (1,0) [0|255] ""  DAPP
 SG_ SBCMU05_SW02 : 23|8@0+ (1,0) [0|255] ""  DAPP
 SG_ SBCMU05_SW03 : 31|8@0+ (1,0) [0|255] ""  DAPP
 SG_ SBCMU05_SW04 : 39|8@0+ (1,0) [0|255] ""  DAPP
 SG_ SBCMU05_SW05 : 47|8@0+ (1,0) [0|255] ""  DAPP
 SG_ SBCMU05_SW06 : 55|8@0+ (1,0) [0|255] ""  DAPP
 SG_ SBCMU05_SW07 : 63|8@0+ (1,0) [0|255] ""  DAPP

BO_ 2565013429 SBCMU05_HW_Info: 8 SBCMU
 SG_ SBCMU05_HW01 : 15|8@0+ (1,0) [0|255] ""  DAPP
 SG_ SBCMU05_HW02 : 23|8@0+ (1,0) [0|255] ""  DAPP
 SG_ SBCMU05_HW03 : 31|8@0+ (1,0) [0|255] ""  DAPP
 SG_ SBCMU05_HW04 : 39|8@0+ (1,0) [0|255] ""  DAPP
 SG_ SBCMU05_HW05 : 47|8@0+ (1,0) [0|255] ""  DAPP
 SG_ SBCMU05_HW06 : 55|8@0+ (1,0) [0|255] ""  DAPP
 SG_ SBCMU05_HW07 : 63|8@0+ (1,0) [0|255] ""  DAPP

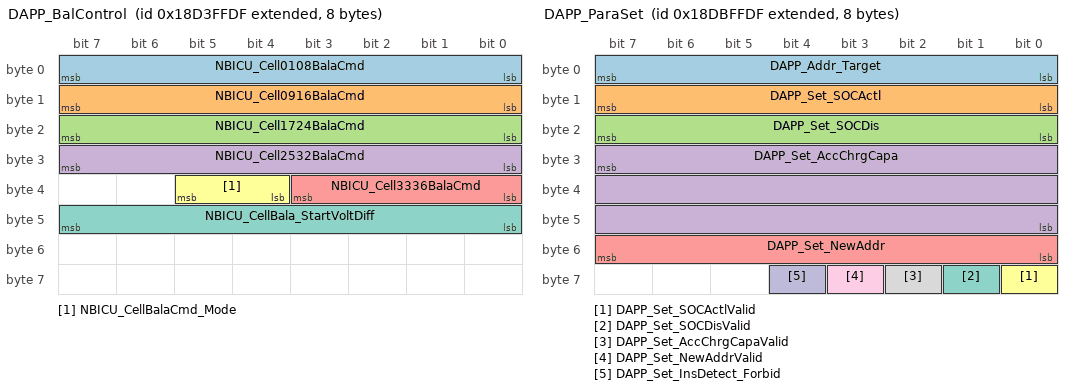
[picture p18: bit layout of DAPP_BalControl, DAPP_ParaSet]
BO_ 2564030431 DAPP_BalControl: 8 DAPP
 SG_ NBICU_Cell0108BalaCmd : 7|8@0+ (1,0) [0|255] ""  NBICU
 SG_ NBICU_Cell0916BalaCmd : 15|8@0+ (1,0) [0|255] ""  NBICU
 SG_ NBICU_Cell1724BalaCmd : 23|8@0+ (1,0) [0|255] ""  NBICU
 SG_ NBICU_Cell2532BalaCmd : 31|8@0+ (1,0) [0|255] ""  NBICU
 SG_ NBICU_Cell3336BalaCmd : 35|4@0+ (1,0) [0|15] ""  NBICU
 SG_ NBICU_CellBalaCmd_Mode : 37|2@0+ (1,0) [0|3] ""  NBICU
 SG_ NBICU_CellBala_StartVoltDiff : 47|8@0+ (1,0) [0|255] "mV"  NBICU

BO_ 2564489183 DAPP_AddressSet: 8 DAPP
 SG_ DAPP_NBCMU_AddConfigCmd : 1|2@0+ (1,0) [0|3] ""  NBICU,SBICU,NBCMU,SBCMU
 SG_ DAPP_SBCMU_AddConfigCmd : 3|2@0+ (1,0) [0|3] ""  NBICU,SBICU,NBCMU,SBCMU
 SG_ DAPP_NBICU_AddConfigCmd : 5|2@0+ (1,0) [0|3] ""  NBICU,SBICU,NBCMU,SBCMU
 SG_ DAPP_SBICU_AddConfigCmd : 7|2@0+ (1,0) [0|3] ""  NBICU,SBICU,NBCMU,SBCMU

BO_ 2564554719 DAPP_ParaSet: 8 DAPP
 SG_ DAPP_Addr_Target : 7|8@0+ (1,0) [0|255] ""  NBICU,SBICU,NBCMU,SBCMU
 SG_ DAPP_Set_SOCActl : 15|8@0+ (1,0) [0|100] "%"  NBICU,SBICU,NBCMU,SBCMU
 SG_ DAPP_Set_SOCDis : 23|8@0+ (1,0) [0|100] "%"  NBICU,SBICU,NBCMU,SBCMU
 SG_ DAPP_Set_AccChrgCapa : 31|24@0+ (1,0) [0|16777215] "Ah"  NBICU,SBICU,NBCMU,SBCMU
 SG_ DAPP_Set_NewAddr : 55|8@0+ (1,0) [0|255] ""  NBICU,SBICU,NBCMU,SBCMU
 SG_ DAPP_Set_SOCActlValid : 56|1@0+ (1,0) [0|1] ""  NBICU,SBICU,NBCMU,SBCMU
 SG_ DAPP_Set_SOCDisValid : 57|1@0+ (1,0) [0|1] ""  NBICU,SBICU,NBCMU,SBCMU
 SG_ DAPP_Set_AccChrgCapaValid : 58|1@0+ (1,0) [0|1] ""  NBICU,SBICU,NBCMU,SBCMU
 SG_ DAPP_Set_NewAddrValid : 59|1@0+ (1,0) [0|1] ""  NBICU,SBICU,NBCMU,SBCMU
 SG_ DAPP_Set_InsDetect_Forbid : 60|1@0+ (1,0) [0|1] ""  NBICU,SBICU,NBCMU,SBCMU

BO_ 2563899359 DAPP_FaultSet: 8 DAPP
 SG_ DAPP_Fault_Addr_Target : 7|8@0+ (1,0) [0|255] ""  NBCMU,SBCMU
 SG_ DAPP_ErrCode : 15|8@0+ (1,0) [0|100] ""  NBCMU,SBCMU
 SG_ DAPP_Set_Fault : 56|1@0+ (1,0) [0|1] ""  NBCMU,SBCMU
 SG_ DAPP_FaultDetect_Mode : 57|1@0+ (1,0) [0|1] ""  NBCMU,SBCMU

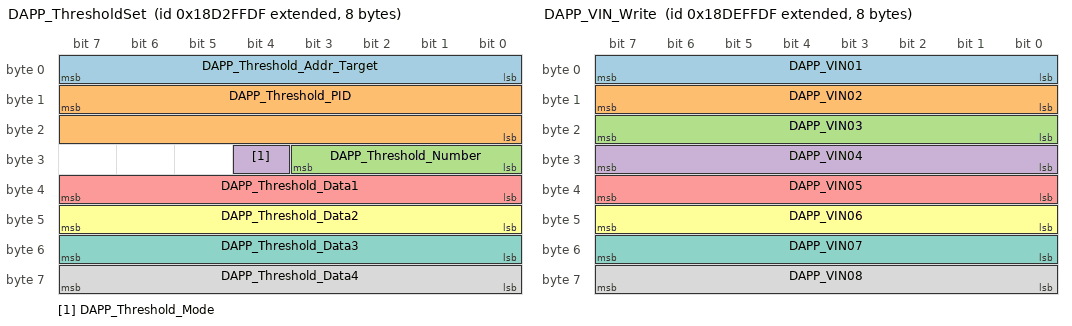
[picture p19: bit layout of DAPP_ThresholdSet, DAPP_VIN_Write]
BO_ 2563964895 DAPP_ThresholdSet: 8 DAPP
 SG_ DAPP_Threshold_Addr_Target : 7|8@0+ (1,0) [0|255] ""  NBCMU,SBCMU
 SG_ DAPP_Threshold_PID : 15|16@0+ (1,0) [0|65535] ""  NBCMU,SBCMU
 SG_ DAPP_Threshold_Number : 27|4@0+ (1,0) [0|15] ""  NBCMU,SBCMU
 SG_ DAPP_Threshold_Mode : 28|1@0+ (1,0) [0|1] ""  NBCMU,SBCMU
 SG_ DAPP_Threshold_Data1 : 39|8@0+ (1,0) [0|255] ""  NBCMU,SBCMU
 SG_ DAPP_Threshold_Data2 : 47|8@0+ (1,0) [0|255] ""  NBCMU,SBCMU
 SG_ DAPP_Threshold_Data3 : 55|8@0+ (1,0) [0|255] ""  NBCMU,SBCMU
 SG_ DAPP_Threshold_Data4 : 63|8@0+ (1,0) [0|255] ""  NBCMU,SBCMU

BO_ 2564751327 DAPP_VIN_Write: 8 DAPP
 SG_ DAPP_VIN01 : 7|8@0+ (1,0) [0|255] ""  NBCMU
 SG_ DAPP_VIN02 : 15|8@0+ (1,0) [0|255] ""  NBCMU
 SG_ DAPP_VIN03 : 23|8@0+ (1,0) [0|255] ""  NBCMU
 SG_ DAPP_VIN04 : 31|8@0+ (1,0) [0|255] ""  NBCMU
 SG_ DAPP_VIN05 : 39|8@0+ (1,0) [0|155] ""  NBCMU
 SG_ DAPP_VIN06 : 47|8@0+ (1,0) [0|255] ""  NBCMU
 SG_ DAPP_VIN07 : 55|8@0+ (1,0) [0|255] ""  NBCMU
 SG_ DAPP_VIN08 : 63|8@0+ (1,0) [0|255] ""  NBCMU

BO_ 2564685791 DAPP_DiagRequest: 8 DAPP
 SG_ Diag_ReqData : 7|64@0+ (1,0) [0|1.84467440737096E+019] ""  NBICU,SBICU,NBCMU,SBCMU

CM_ BO_ 2561802145 "NBCMU Tx and WarningInfo1";
CM_ SG_ 2561802145 NBCMU01_HeatCurr "HeatCurr
加热电流值";
CM_ SG_ 2561802145 NBCMU01_SysFailSta "System Failure Status
NBCMU失效状态";
CM_ SG_ 2561802145 NBCMU01_InsRes_polarity "System InsRes polarity
NBCMU绝缘电阻极性";
CM_ SG_ 2561802145 NBCMU01_BattVolt_HighWarning "总压过压(过充)";
CM_ SG_ 2561802145 NBCMU01_BattVolt_LowWarning "总压欠压(过放)";
CM_ SG_ 2561802145 NBCMU01_CellVolt_HighWarning "单体过压(过充)";
CM_ SG_ 2561802145 NBCMU01_CellVolt_LowWarning "单体欠压(过放)";
CM_ SG_ 2561802145 NBCMU01_ChrgTemp_HighWarning "充电(单体)温度过高";
CM_ SG_ 2561802145 NBCMU01_ChrgTemp_LowWarning "充电(单体)温度过低";
CM_ SG_ 2561802145 NBCMU01_DischrgTemp_HighWarning "放电(单体)温度过高";
CM_ SG_ 2561802145 NBCMU01_DischrgTemp_LowWarning "放电(单体)温度过低";
CM_ SG_ 2561802145 NBCMU01_TempDiff_Warning "(电池)温差过大";
CM_ SG_ 2561802145 NBCMU01_CellVoltDiff_Warning "(电池)压差过大";
CM_ SG_ 2561802145 NBCMU01_DischrgCurr_OverWarning "放电过流";
CM_ SG_ 2561802145 NBCMU01_ChrgCurr_OverWarning "充电过流";
CM_ SG_ 2561802145 NBCMU01_InsulationWarning "绝缘故障";
CM_ SG_ 2561802145 NBCMU01_SOC_LowWarning "SOC过低";
CM_ SG_ 2561802145 NBCMU01_AmbientTemp_HighWarning "环境温度过高";
CM_ SG_ 2561802145 NBCMU01_AmbientTemp_LowWarning "环境温度过低";
CM_ SG_ 2561802145 NBCMU01_ContactorPosi_Fault "主正继电器故障";
CM_ SG_ 2561802145 NBCMU01_ContactorNega_Fault "主负继电器故障";
CM_ SG_ 2561802145 NBCMU01_ContactorBalan_Fault "均衡继电器故障";
CM_ SG_ 2561802145 NBCMU01_ContactorHeat_Fault "加热继电器故障";
CM_ SG_ 2561802145 NBCMU01_CurrSensor_TimeOut "霍尔电流传感器通讯丢失";
CM_ SG_ 2561802145 NBCMU01_SOH_LowWarning "SOH过低";
CM_ SG_ 2561802145 NBCMU01_HVIL_Fault "NBCMU高压互锁故障";
CM_ SG_ 2561802145 NBCMU01_Fuse_Fault "NBCMU熔断器故障";
CM_ BO_ 2562457505 "NBCMU Tx and WarningInfo2";
CM_ SG_ 2562457505 NBCMU01_ErrTab "Error Table
故障码";
CM_ SG_ 2562457505 NBCMU01_FaultSum "Fault Sum
故障总数";
CM_ SG_ 2562457505 NBCMU01_NBICU_TimeOut "BICU通讯丢失";
CM_ SG_ 2562457505 NBCMU01_PrechrgFault "预充失败故障";
CM_ SG_ 2562457505 NBCMU01_SupplyVolt_HighWarning "供电电压过高";
CM_ SG_ 2562457505 NBCMU01_SupplyVolt_LowWarning "供电电压过低";
CM_ SG_ 2562457505 NBCMU01_CellVoltOpen "单体电压采样断线";
CM_ SG_ 2562457505 NBCMU01_CellTempOpen "单体温度采样断线";
CM_ SG_ 2562457505 NBCMU01_AccChrgCapa "NBCMU Acc Charge Capacity
NBCMU累计充电容量";
CM_ SG_ 2562457505 NBCMU01_BoxInterTemp "Ambient Temperature
NBCMU采集箱内温度";
CM_ SG_ 2562457505 NBCMU01_ReservedTemp "Reserved Temperature
NBCMU采集预留温度温度";
CM_ BO_ 2561867681 "NBCMU Tx and VoltExtremeInfo";
CM_ SG_ 2561867681 NBCMU01_SysCellVoltMax "SysCellVoltMax
系统最高单体电压";
CM_ SG_ 2561867681 NBCMU01_SysVMax_NBICUadd "SysVMax_NBICUadd
最高单体电压所处从机地址";
CM_ SG_ 2561867681 NBCMU01_SysVMax_Code "SysVMax_Code
最高单体电压对应编号";
CM_ SG_ 2561867681 NBCMU01_SysCellVoltMin "SysCellVoltMin
系统最低单体电压";
CM_ SG_ 2561867681 NBCMU01_SysVMin_NBICUadd "SysVMin_NBICUadd
最低单体电压所处从机地址";
CM_ SG_ 2561867681 NBCMU01_SysVMin_Code "SysVMinx_Code
最低单体电压对应编号";
CM_ BO_ 2561933217 "NBCMU Tx and TempExtremeInfo";
CM_ SG_ 2561933217 NBCMU01_SysTempMax "系统最高单体温度";
CM_ SG_ 2561933217 NBCMU01_SysTMax_NBICUadd "最高单体温度所处从机地址";
CM_ SG_ 2561933217 NBCMU01_SysTMax_Code "最高单体温度对应编号";
CM_ SG_ 2561933217 NBCMU01_SysTempMin "系统最低单体温度";
CM_ SG_ 2561933217 NBCMU01_SysTMin_NBICUadd "最低单体温度所处从机地址";
CM_ SG_ 2561933217 NBCMU01_SysTMin_Code "最低单体温度对应编号";
CM_ SG_ 2561933217 NBCMU01_AmbientTemp "Ambient Temperature
NBCMU采集环境温度";
CM_ SG_ 2561933217 NBCMU01_BalaResTemp "Balance Resistance Temperature
NBCMU采集均衡电阻温度";
CM_ BO_ 2561998753 "NBCMU Tx and SOX";
CM_ SG_ 2561998753 NBCMU01_SysSOC_Actl "电池簇真实SOC";
CM_ SG_ 2561998753 NBCMU01_SysSOC_Dis "电池簇显示SOC";
CM_ SG_ 2561998753 NBCMU01_SysSOH_ByNBICU "SysSOH
电池簇SOH(统计NBICU)";
CM_ SG_ 2561998753 NBCMU01_SysSOH_Cal "SysSOH
电池簇SOH(NBCMU计算)";
CM_ SG_ 2561998753 NBCMU01_SysSOE "SysSOE
系统剩余能量SOE";
CM_ BO_ 2562064289 "NBCMU Tx andSysHVoltage";
CM_ SG_ 2562064289 NBCMU01_SysHVoltage "SysHVoltage
系统电池总压";
CM_ SG_ 2562064289 NBCMU01_SysSumVoltage "SysSumVoltage
系统累加总压";
CM_ SG_ 2562064289 NBCMU01_SysSampVoltage "SysSampVoltage
系统母线总压";
CM_ SG_ 2562064289 NBCMU01_SysInsRes "SysInsRes
系统绝缘阻值";
CM_ BO_ 2562195361 "NBCMU Tx and DischrgChrg";
CM_ SG_ 2562195361 NBCMU01_MaxConDisCurnt "Maximum continuous discharging current
最大持续放电电流";
CM_ SG_ 2562195361 NBCMU01_MaxConChrgCurnt "Maximum Continuous  Charging Current
最大持续充电电流";
CM_ SG_ 2562195361 NBCMU01_MaxInstanDisCurnt "Maximum Instantaneous Discharging Current
电池最大瞬时放电电流";
CM_ SG_ 2562195361 NBCMU01_MaxInstanChrgCurnt "Maximum  Instantaneous Charging Current
能量回收最大瞬时充电电流";
CM_ BO_ 2560884641 "NBCMU Tx and WarningInfo3 Related";
CM_ SG_ 2560884641 NBCMU01_SumVolt_HighWarning "NBCMU电池包累加总压过压";
CM_ SG_ 2560884641 NBCMU01_SumVolt_LowWarning "NBCMU电池包累加总压欠压";
CM_ SG_ 2560884641 NBCMU01_CurrentLoop_HighWarning "电池簇间环流故障";
CM_ SG_ 2560884641 NBCMU01_ProtectFault "NBCMU保护功能故障";
CM_ SG_ 2560884641 NBCMU01_RunLed_State "NBCMU Run Led State
NBCMU运行LED灯状态";
CM_ SG_ 2560884641 NBCMU01_Buzz_State "NBCMU Buzz State
NBCMU蜂鸣器状态";
CM_ SG_ 2560884641 NBCMU01_Heating_State "NBCMU Heating State
NBCMU加热开启状态";
CM_ SG_ 2560884641 NBCMU01_Cooling_State "NBCMU Cooling State
NBCMU冷却开启状态";
CM_ SG_ 2560884641 NBCMU01_BattVoltDiff_Warning "NBCMU电池包一致性故障";
CM_ SG_ 2560884641 NBCMU01_EmergyShutdown_Fault "NBCMU急停故障";
CM_ SG_ 2560884641 NBCMU01_PCS_TimeOut "NBCMU检测PCS通信失败";
CM_ SG_ 2560884641 NBCMU01_EMS_TimeOut "NBCMU检测EMS通信失败";
CM_ SG_ 2560884641 NBCMU01_TMS_TimeOut "NBCMU检测TMS通信失败";
CM_ SG_ 2560884641 NBCMU01_SBCMU01_TimeOut "NBCMU检测簇安全板通信失败";
CM_ SG_ 2560884641 NBCMU01_InitialFault "NBCMU初始化故障";
CM_ SG_ 2560884641 NBCMU01_ThermalManagement_Fault "NBCMU热管理故障";
CM_ SG_ 2560884641 NBCMU01_DCS_ActOprtMode "DC Charging System Actual Operating Mode
直流充电实际状态";
CM_ SG_ 2560884641 NBCMU01_ChrgFault "NBCMU充电故障";
CM_ SG_ 2560884641 NBCMU01_DC_ChrgEnable "NBCMU直流充电允许";
CM_ SG_ 2560884641 NBCMU01_Contactor_DC_Cmd "直流充电继电器指令";
CM_ SG_ 2560884641 NBCMU01_MaxAllowChrgCur_DC "DC Charging System Maximum Allowed Charging Current
直流充电最大允许充电电流";
CM_ SG_ 2560884641 NBCMU01_MaxAllowChrgVol_DC "DC Charging System Maximum Allowed Charging Voltage
直流充电最大允许充电电压";
CM_ BO_ 2561605537 "NBCMU Tx and VIN FeedBack";
CM_ SG_ 2561605537 NBCMU01_VIN01 "VIN Byte 01
VIN第01个字节";
CM_ SG_ 2561605537 NBCMU01_VIN02 "VIN Byte 02
VIN第02个字节";
CM_ SG_ 2561605537 NBCMU01_VIN03 "VIN Byte 03
VIN第03个字节";
CM_ SG_ 2561605537 NBCMU01_VIN04 "VIN Byte 04
VIN第04个字节";
CM_ SG_ 2561605537 NBCMU01_VIN05 "VIN Byte 05
VIN第05个字节";
CM_ SG_ 2561605537 NBCMU01_VIN06 "VIN Byte 06
VIN第06个字节";
CM_ SG_ 2561605537 NBCMU01_VIN07 "VIN Byte 07
VIN第07个字节";
CM_ SG_ 2561605537 NBCMU01_VIN08 "VIN Byte 08
VIN第08个字节";
CM_ BO_ 2564947873 "NBCMU Tx and Software";
CM_ SG_ 2564947873 NBCMU01_SW01 "NBCMU Software Byte 01
NBCMU软件版本第01字节";
CM_ SG_ 2564947873 NBCMU01_SW02 "NBCMU Software Byte 02
NBCMU软件版本第02字节";
CM_ SG_ 2564947873 NBCMU01_SW03 "NBCMU Software Byte 03
NBCMU软件版本第03字节";
CM_ SG_ 2564947873 NBCMU01_SW04 "NBCMU Software Byte 04
NBCMU软件版本第04字节";
CM_ SG_ 2564947873 NBCMU01_SW05 "NBCMU Software Byte 05
NBCMU软件版本第05字节";
CM_ SG_ 2564947873 NBCMU01_SW06 "NBCMU Software Byte 06
NBCMU软件版本第06字节";
CM_ SG_ 2564947873 NBCMU01_SW07 "NBCMU Software Byte 07
NBCMU软件版本第07字节";
CM_ BO_ 2565013409 "NBCMU Tx and Hardware";
CM_ SG_ 2565013409 NBCMU01_HW01 "NBCMU Hardware Byte 01
NBCMU硬件版本第01字节";
CM_ SG_ 2565013409 NBCMU01_HW02 "NBCMU Hardware Byte 02
NBCMU硬件版本第02字节";
CM_ SG_ 2565013409 NBCMU01_HW03 "NBCMU Hardware Byte 03
NBCMU硬件版本第03字节";
CM_ SG_ 2565013409 NBCMU01_HW04 "NBCMU Hardware Byte 04
NBCMU硬件版本第04字节";
CM_ SG_ 2565013409 NBCMU01_HW05 "NBCMU Hardware Byte 05
NBCMU硬件版本第05字节";
CM_ SG_ 2565013409 NBCMU01_HW06 "NBCMU Hardware Byte 06
NBCMU硬件版本第06字节";
CM_ SG_ 2565013409 NBCMU01_HW07 "NBCMU Hardware Byte 07
NBCMU硬件版本第07字节";
CM_ BO_ 2561736610 "NBCMU Tx and Run State";
CM_ SG_ 2561736610 NBCMU02_Address "NBCMU_Address有效地址";
CM_ SG_ 2561736610 NBCMU02_NBICUnum "NBICUnum
配置电池包管理单元总数";
CM_ SG_ 2561736610 NBCMU02_SysCurr "SysCurr
系统电流值";
CM_ SG_ 2561736610 NBCMU02_Contactor_state_Negative "Negative contactor state
主负继电器状态";
CM_ SG_ 2561736610 NBCMU02_Contactor_state_Positive "Positive contactor state
主正继电器状态";
CM_ SG_ 2561736610 NBCMU02_Contactor_state_PreChrg "Precharge contactor state
预充继电器状态";
CM_ SG_ 2561736610 NBCMU02_Contactor_state_Heat "Heat contactor state
加热继电器状态";
CM_ SG_ 2561736610 NBCMU02_WorkState "Work State
工作状态";
CM_ SG_ 2561736610 NBCMU02_SoftVer "SoftVer
软件版本";
CM_ SG_ 2561736610 NBCMU02_HardVer "HardVer
硬件版本";
CM_ SG_ 2561736610 NBCMU02_AliveCounter "Alive Counter";
CM_ BO_ 2561802146 "NBCMU Tx and WarningInfo1";
CM_ SG_ 2561802146 NBCMU02_HeatCurr "HeatCurr
加热电流值";
CM_ SG_ 2561802146 NBCMU02_SysFailSta "System Failure Status
NBCMU失效状态";
CM_ SG_ 2561802146 NBCMU02_InsRes_polarity "System InsRes polarity
NBCMU绝缘电阻极性";
CM_ SG_ 2561802146 NBCMU02_BattVolt_HighWarning "总压过压(过充)";
CM_ SG_ 2561802146 NBCMU02_BattVolt_LowWarning "总压欠压(过放)";
CM_ SG_ 2561802146 NBCMU02_CellVolt_HighWarning "单体过压(过充)";
CM_ SG_ 2561802146 NBCMU02_CellVolt_LowWarning "单体欠压(过放)";
CM_ SG_ 2561802146 NBCMU02_ChrgTemp_HighWarning "充电(单体)温度过高";
CM_ SG_ 2561802146 NBCMU02_ChrgTemp_LowWarning "充电(单体)温度过低";
CM_ SG_ 2561802146 NBCMU02_DischrgTemp_HighWarning "放电(单体)温度过高";
CM_ SG_ 2561802146 NBCMU02_DischrgTemp_LowWarning "放电(单体)温度过低";
CM_ SG_ 2561802146 NBCMU02_TempDiff_Warning "(电池)温差过大";
CM_ SG_ 2561802146 NBCMU02_CellVoltDiff_Warning "(电池)压差过大";
CM_ SG_ 2561802146 NBCMU02_DischrgCurr_OverWarning "放电过流";
CM_ SG_ 2561802146 NBCMU02_ChrgCurr_OverWarning "充电过流";
CM_ SG_ 2561802146 NBCMU02_InsulationWarning "绝缘故障";
CM_ SG_ 2561802146 NBCMU02_SOC_LowWarning "SOC过低";
CM_ SG_ 2561802146 NBCMU02_AmbientTemp_HighWarning "环境温度过高";
CM_ SG_ 2561802146 NBCMU02_AmbientTemp_LowWarning "环境温度过低";
CM_ SG_ 2561802146 NBCMU02_ContactorPosi_Fault "主正继电器故障";
CM_ SG_ 2561802146 NBCMU02_ContactorNega_Fault "主负继电器故障";
CM_ SG_ 2561802146 NBCMU02_ContactorBalan_Fault "均衡继电器故障";
CM_ SG_ 2561802146 NBCMU02_ContactorHeat_Fault "加热继电器故障";
CM_ SG_ 2561802146 NBCMU02_CurrSensor_TimeOut "霍尔电流传感器通讯丢失";
CM_ SG_ 2561802146 NBCMU02_SOH_LowWarning "SOH过低";
CM_ SG_ 2561802146 NBCMU02_HVIL_Fault "NBCMU高压互锁故障";
CM_ SG_ 2561802146 NBCMU02_Fuse_Fault "NBCMU熔断器故障";
CM_ BO_ 2562457506 "NBCMU Tx and WarningInfo2";
CM_ SG_ 2562457506 NBCMU02_ErrTab "Error Table
故障码";
CM_ SG_ 2562457506 NBCMU02_FaultSum "Fault Sum
故障总数";
CM_ SG_ 2562457506 NBCMU02_NBICU_TimeOut "BICU通讯丢失";
CM_ SG_ 2562457506 NBCMU02_PrechrgFault "预充失败故障";
CM_ SG_ 2562457506 NBCMU02_SupplyVolt_HighWarning "供电电压过高";
CM_ SG_ 2562457506 NBCMU02_SupplyVolt_LowWarning "供电电压过低";
CM_ SG_ 2562457506 NBCMU02_CellVoltOpen "单体电压采样断线";
CM_ SG_ 2562457506 NBCMU02_CellTempOpen "单体温度采样断线";
CM_ SG_ 2562457506 NBCMU02_AccChrgCapa "NBCMU Acc Charge Capacity
NBCMU累计充电容量";
CM_ SG_ 2562457506 NBCMU02_BoxInterTemp "Ambient Temperature
NBCMU采集箱内温度";
CM_ SG_ 2562457506 NBCMU02_ReservedTemp "Reserved Temperature
NBCMU采集预留温度温度";
CM_ BO_ 2561867682 "NBCMU Tx and VoltExtremeInfo";
CM_ SG_ 2561867682 NBCMU02_SysCellVoltMax "SysCellVoltMax
系统最高单体电压";
CM_ SG_ 2561867682 NBCMU02_SysVMax_NBICUadd "SysVMax_NBICUadd
最高单体电压所处从机地址";
CM_ SG_ 2561867682 NBCMU02_SysVMax_Code "SysVMax_Code
最高单体电压对应编号";
CM_ SG_ 2561867682 NBCMU02_SysCellVoltMin "SysCellVoltMin
系统最低单体电压";
CM_ SG_ 2561867682 NBCMU02_SysVMin_NBICUadd "SysVMin_NBICUadd
最低单体电压所处从机地址";
CM_ SG_ 2561867682 NBCMU02_SysVMin_Code "SysVMin_Code
最低单体电压对应编号";
CM_ BO_ 2561933218 "NBCMU Tx and TempExtremeInfo";
CM_ SG_ 2561933218 NBCMU02_SysTempMax "系统最高单体温度";
CM_ SG_ 2561933218 NBCMU02_SysTMax_NBICUadd "最高单体温度所处从机地址";
CM_ SG_ 2561933218 NBCMU02_SysTMax_Code "最高单体温度对应编号";
CM_ SG_ 2561933218 NBCMU02_SysTempMin "系统最低单体温度";
CM_ SG_ 2561933218 NBCMU02_SysTMin_NBICUadd "最低单体温度所处从机地址";
CM_ SG_ 2561933218 NBCMU02_SysTMin_Code "最低单体温度对应编号";
CM_ SG_ 2561933218 NBCMU02_AmbientTemp "Ambient Temperature
NBCMU采集环境温度";
CM_ SG_ 2561933218 NBCMU02_BalaResTemp "Balance Resistance Temperature
NBCMU采集均衡电阻温度";
CM_ BO_ 2561998754 "NBCMU Tx and SOX";
CM_ SG_ 2561998754 NBCMU02_SysSOC_Actl "电池簇真实SOC";
CM_ SG_ 2561998754 NBCMU02_SysSOC_Dis "电池簇显示SOC";
CM_ SG_ 2561998754 NBCMU02_SysSOH_ByNBICU "SysSOH
电池簇SOH(统计NBICU)";
CM_ SG_ 2561998754 NBCMU02_SysSOH_Cal "SysSOH
电池簇SOH(NBCMU计算)";
CM_ SG_ 2561998754 NBCMU02_SysSOE "SysSOE
系统剩余能量SOE";
CM_ BO_ 2562064290 "NBCMU Tx andSysHVoltage";
CM_ SG_ 2562064290 NBCMU02_SysHVoltage "SysHVoltage
系统电池总压";
CM_ SG_ 2562064290 NBCMU02_SysSumVoltage "SysSumVoltage
系统累加总压";
CM_ SG_ 2562064290 NBCMU02_SysSampVoltage "SysSampVoltage
系统母线总压";
CM_ SG_ 2562064290 NBCMU02_SysInsRes "SysInsRes
系统绝缘阻值";
CM_ BO_ 2562195362 "NBCMU Tx and DischrgChrg";
CM_ SG_ 2562195362 NBCMU02_MaxConDisCurnt "Maximum continuous discharging current
最大持续放电电流";
CM_ SG_ 2562195362 NBCMU02_MaxConChrgCurnt "Maximum Continuous  Charging Current
最大持续充电电流";
CM_ SG_ 2562195362 NBCMU02_MaxInstanDisCurnt "Maximum Instantaneous Discharging Current
电池最大瞬时放电电流";
CM_ SG_ 2562195362 NBCMU02_MaxInstanChrgCurnt "Maximum  Instantaneous Charging Current
能量回收最大瞬时充电电流";
CM_ BO_ 2560884642 "NBCMU Tx and WarningInfo3 Related";
CM_ SG_ 2560884642 NBCMU02_SumVolt_HighWarning "NBCMU电池包累加总压过压";
CM_ SG_ 2560884642 NBCMU02_SumVolt_LowWarning "NBCMU电池包累加总压欠压";
CM_ SG_ 2560884642 NBCMU02_CurrentLoop_HighWarning "电池簇间环流故障";
CM_ SG_ 2560884642 NBCMU02_ProtectFault "NBCMU保护功能故障";
CM_ SG_ 2560884642 NBCMU02_RunLed_State "NBCMU Run Led State
NBCMU运行LED灯状态";
CM_ SG_ 2560884642 NBCMU02_Buzz_State "NBCMU Buzz State
NBCMU蜂鸣器状态";
CM_ SG_ 2560884642 NBCMU02_Heating_State "NBCMU Heating State
NBCMU加热开启状态";
CM_ SG_ 2560884642 NBCMU02_Cooling_State "NBCMU Cooling State
NBCMU冷却开启状态";
CM_ SG_ 2560884642 NBCMU02_BattVoltDiff_Warning "NBCMU电池包一致性故障";
CM_ SG_ 2560884642 NBCMU02_EmergyShutdown_Fault "NBCMU急停故障";
CM_ SG_ 2560884642 NBCMU02_PCS_TimeOut "NBCMU检测PCS通信失败";
CM_ SG_ 2560884642 NBCMU02_EMS_TimeOut "NBCMU检测EMS通信失败";
CM_ SG_ 2560884642 NBCMU02_TMS_TimeOut "NBCMU检测TMS通信失败";
CM_ SG_ 2560884642 NBCMU02_SBCMU01_TimeOut "NBCMU检测簇安全板通信失败";
CM_ SG_ 2560884642 NBCMU02_InitialFault "NBCMU初始化故障";
CM_ SG_ 2560884642 NBCMU02_ThermalManagement_Fault "NBCMU热管理故障";
CM_ SG_ 2560884642 NBCMU02_DCS_ActOprtMode "DC Charging System Actual Operating Mode
直流充电实际状态";
CM_ SG_ 2560884642 NBCMU02_ChrgFault "NBCMU充电故障";
CM_ SG_ 2560884642 NBCMU02_DC_ChrgEnable "NBCMU直流充电允许";
CM_ SG_ 2560884642 NBCMU02_Contactor_DC_Cmd "直流充电继电器指令";
CM_ SG_ 2560884642 NBCMU02_MaxAllowChrgCur_DC "DC Charging System Maximum Allowed Charging Current
直流充电最大允许充电电流";
CM_ SG_ 2560884642 NBCMU02_MaxAllowChrgVol_DC "DC Charging System Maximum Allowed Charging Voltage
直流充电最大允许充电电压";
CM_ BO_ 2561605538 "NBCMU Tx and VIN FeedBack";
CM_ SG_ 2561605538 NBCMU02_VIN01 "VIN Byte 01
VIN第01个字节";
CM_ SG_ 2561605538 NBCMU02_VIN02 "VIN Byte 02
VIN第02个字节";
CM_ SG_ 2561605538 NBCMU02_VIN03 "VIN Byte 03
VIN第03个字节";
CM_ SG_ 2561605538 NBCMU02_VIN04 "VIN Byte 04
VIN第04个字节";
CM_ SG_ 2561605538 NBCMU02_VIN05 "VIN Byte 05
VIN第05个字节";
CM_ SG_ 2561605538 NBCMU02_VIN06 "VIN Byte 06
VIN第06个字节";
CM_ SG_ 2561605538 NBCMU02_VIN07 "VIN Byte 07
VIN第07个字节";
CM_ SG_ 2561605538 NBCMU02_VIN08 "VIN Byte 08
VIN第08个字节";
CM_ BO_ 2564947874 "NBCMU Tx and Software";
CM_ SG_ 2564947874 NBCMU02_SW01 "NBCMU Software Byte 01
NBCMU软件版本第01字节";
CM_ SG_ 2564947874 NBCMU02_SW02 "NBCMU Software Byte 02
NBCMU软件版本第02字节";
CM_ SG_ 2564947874 NBCMU02_SW03 "NBCMU Software Byte 03
NBCMU软件版本第03字节";
CM_ SG_ 2564947874 NBCMU02_SW04 "NBCMU Software Byte 04
NBCMU软件版本第04字节";
CM_ SG_ 2564947874 NBCMU02_SW05 "NBCMU Software Byte 05
NBCMU软件版本第05字节";
CM_ SG_ 2564947874 NBCMU02_SW06 "NBCMU Software Byte 06
NBCMU软件版本第06字节";
CM_ SG_ 2564947874 NBCMU02_SW07 "NBCMU Software Byte 07
NBCMU软件版本第07字节";
CM_ BO_ 2565013410 "NBCMU Tx and Hardware";
CM_ SG_ 2565013410 NBCMU02_HW01 "NBCMU Hardware Byte 01
NBCMU硬件版本第01字节";
CM_ SG_ 2565013410 NBCMU02_HW02 "NBCMU Hardware Byte 02
NBCMU硬件版本第02字节";
CM_ SG_ 2565013410 NBCMU02_HW03 "NBCMU Hardware Byte 03
NBCMU硬件版本第03字节";
CM_ SG_ 2565013410 NBCMU02_HW04 "NBCMU Hardware Byte 04
NBCMU硬件版本第04字节";
CM_ SG_ 2565013410 NBCMU02_HW05 "NBCMU Hardware Byte 05
NBCMU硬件版本第05字节";
CM_ SG_ 2565013410 NBCMU02_HW06 "NBCMU Hardware Byte 06
NBCMU硬件版本第06字节";
CM_ SG_ 2565013410 NBCMU02_HW07 "NBCMU Hardware Byte 07
NBCMU硬件版本第07字节";
CM_ BO_ 2561736611 "NBCMU Tx and Run State";
CM_ SG_ 2561736611 NBCMU03_Address "NBCMU_Address有效地址";
CM_ SG_ 2561736611 NBCMU03_NBICUnum "NBICUnum
配置电池包管理单元总数";
CM_ SG_ 2561736611 NBCMU03_SysCurr "SysCurr
系统电流值";
CM_ SG_ 2561736611 NBCMU03_Contactor_state_Negative "Negative contactor state
主负继电器状态";
CM_ SG_ 2561736611 NBCMU03_Contactor_state_Positive "Positive contactor state
主正继电器状态";
CM_ SG_ 2561736611 NBCMU03_Contactor_state_PreChrg "Precharge contactor state
预充继电器状态";
CM_ SG_ 2561736611 NBCMU03_Contactor_state_Heat "Heat contactor state
加热继电器状态";
CM_ SG_ 2561736611 NBCMU03_WorkState "Work State
工作状态";
CM_ SG_ 2561736611 NBCMU03_SoftVer "SoftVer
软件版本";
CM_ SG_ 2561736611 NBCMU03_HardVer "HardVer
硬件版本";
CM_ SG_ 2561736611 NBCMU03_AliveCounter "Alive Counter";
CM_ BO_ 2561802147 "NBCMU Tx and WarningInfo1";
CM_ SG_ 2561802147 NBCMU03_HeatCurr "HeatCurr
加热电流值";
CM_ SG_ 2561802147 NBCMU03_SysFailSta "System Failure Status
NBCMU失效状态";
CM_ SG_ 2561802147 NBCMU03_InsRes_polarity "System InsRes polarity
NBCMU绝缘电阻极性";
CM_ SG_ 2561802147 NBCMU03_BattVolt_HighWarning "总压过压(过充)";
CM_ SG_ 2561802147 NBCMU03_BattVolt_LowWarning "总压欠压(过放)";
CM_ SG_ 2561802147 NBCMU03_CellVolt_HighWarning "单体过压(过充)";
CM_ SG_ 2561802147 NBCMU03_CellVolt_LowWarning "单体欠压(过放)";
CM_ SG_ 2561802147 NBCMU03_ChrgTemp_HighWarning "充电(单体)温度过高";
CM_ SG_ 2561802147 NBCMU03_ChrgTemp_LowWarning "充电(单体)温度过低";
CM_ SG_ 2561802147 NBCMU03_DischrgTemp_HighWarning "放电(单体)温度过高";
CM_ SG_ 2561802147 NBCMU03_DischrgTemp_LowWarning "放电(单体)温度过低";
CM_ SG_ 2561802147 NBCMU03_TempDiff_Warning "(电池)温差过大";
CM_ SG_ 2561802147 NBCMU03_CellVoltDiff_Warning "(电池)压差过大";
CM_ SG_ 2561802147 NBCMU03_DischrgCurr_OverWarning "放电过流";
CM_ SG_ 2561802147 NBCMU03_ChrgCurr_OverWarning "充电过流";
CM_ SG_ 2561802147 NBCMU03_InsulationWarning "绝缘故障";
CM_ SG_ 2561802147 NBCMU03_SOC_LowWarning "SOC过低";
CM_ SG_ 2561802147 NBCMU03_AmbientTemp_HighWarning "环境温度过高";
CM_ SG_ 2561802147 NBCMU03_AmbientTemp_LowWarning "环境温度过低";
CM_ SG_ 2561802147 NBCMU03_ContactorPosi_Fault "主正继电器故障";
CM_ SG_ 2561802147 NBCMU03_ContactorNega_Fault "主负继电器故障";
CM_ SG_ 2561802147 NBCMU03_ContactorBalan_Fault "均衡继电器故障";
CM_ SG_ 2561802147 NBCMU03_ContactorHeat_Fault "加热继电器故障";
CM_ SG_ 2561802147 NBCMU03_CurrSensor_TimeOut "霍尔电流传感器通讯丢失";
CM_ SG_ 2561802147 NBCMU03_SOH_LowWarning "SOH过低";
CM_ SG_ 2561802147 NBCMU03_HVIL_Fault "NBCMU高压互锁故障";
CM_ SG_ 2561802147 NBCMU03_Fuse_Fault "NBCMU熔断器故障";
CM_ BO_ 2562457507 "NBCMU Tx and WarningInfo2";
CM_ SG_ 2562457507 NBCMU03_ErrTab "Error Table
故障码";
CM_ SG_ 2562457507 NBCMU03_FaultSum "Fault Sum
故障总数";
CM_ SG_ 2562457507 NBCMU03_NBICU_TimeOut "BICU通讯丢失";
CM_ SG_ 2562457507 NBCMU03_PrechrgFault "预充失败故障";
CM_ SG_ 2562457507 NBCMU03_SupplyVolt_HighWarning "供电电压过高";
CM_ SG_ 2562457507 NBCMU03_SupplyVolt_LowWarning "供电电压过低";
CM_ SG_ 2562457507 NBCMU03_CellVoltOpen "单体电压采样断线";
CM_ SG_ 2562457507 NBCMU03_CellTempOpen "单体温度采样断线";
CM_ SG_ 2562457507 NBCMU03_AccChrgCapa "NBCMU Acc Charge Capacity
NBCMU累计充电容量";
CM_ SG_ 2562457507 NBCMU03_BoxInterTemp "Ambient Temperature
NBCMU采集箱内温度";
CM_ SG_ 2562457507 NBCMU03_ReservedTemp "Reserved Temperature
NBCMU采集预留温度温度";
CM_ BO_ 2561867683 "NBCMU Tx and VoltExtremeInfo";
CM_ SG_ 2561867683 NBCMU03_SysCellVoltMax "SysCellVoltMax
系统最高单体电压";
CM_ SG_ 2561867683 NBCMU03_SysVMax_NBICUadd "SysVMax_NBICUadd
最高单体电压所处从机地址";
CM_ SG_ 2561867683 NBCMU03_SysVMax_Code "SysVMax_Code
最高单体电压对应编号";
CM_ SG_ 2561867683 NBCMU03_SysCellVoltMin "SysCellVoltMin
系统最低单体电压";
CM_ SG_ 2561867683 NBCMU03_SysVMin_NBICUadd "SysVMin_NBICUadd
最低单体电压所处从机地址";
CM_ SG_ 2561867683 NBCMU03_SysVMin_Code "SysVMinx_Code
最低单体电压对应编号";
CM_ BO_ 2561933219 "NBCMU Tx and TempExtremeInfo";
CM_ SG_ 2561933219 NBCMU03_SysTempMax "系统最高单体温度";
CM_ SG_ 2561933219 NBCMU03_SysTMax_NBICUadd "最高单体温度所处从机地址";
CM_ SG_ 2561933219 NBCMU03_SysTMax_Code "最高单体温度对应编号";
CM_ SG_ 2561933219 NBCMU03_SysTempMin "系统最低单体温度";
CM_ SG_ 2561933219 NBCMU03_SysTMin_NBICUadd "最低单体温度所处从机地址";
CM_ SG_ 2561933219 NBCMU03_SysTMin_Code "最低单体温度对应编号";
CM_ SG_ 2561933219 NBCMU03_AmbientTemp "Ambient Temperature
NBCMU采集环境温度";
CM_ SG_ 2561933219 NBCMU03_BalaResTemp "Balance Resistance Temperature
NBCMU采集均衡电阻温度";
CM_ BO_ 2561998755 "NBCMU Tx and SOX";
CM_ SG_ 2561998755 NBCMU03_SysSOC_Actl "电池簇真实SOC";
CM_ SG_ 2561998755 NBCMU03_SysSOC_Dis "电池簇显示SOC";
CM_ SG_ 2561998755 NBCMU03_SysSOH_ByNBICU "SysSOH
电池簇SOH(统计NBICU)";
CM_ SG_ 2561998755 NBCMU03_SysSOH_Cal "SysSOH
电池簇SOH(NBCMU计算)";
CM_ SG_ 2561998755 NBCMU03_SysSOE "SysSOE
系统剩余能量SOE";
CM_ BO_ 2562064291 "NBCMU Tx andSysHVoltage";
CM_ SG_ 2562064291 NBCMU03_SysHVoltage "SysHVoltage
系统电池总压";
CM_ SG_ 2562064291 NBCMU03_SysSumVoltage "SysSumVoltage
系统累加总压";
CM_ SG_ 2562064291 NBCMU03_SysSampVoltage "SysSampVoltage
系统母线总压";
CM_ SG_ 2562064291 NBCMU03_SysInsRes "SysInsRes
系统绝缘阻值";
CM_ BO_ 2562195363 "NBCMU Tx and DischrgChrg";
CM_ SG_ 2562195363 NBCMU03_MaxConDisCurnt "Maximum continuous discharging current
最大持续放电电流";
CM_ SG_ 2562195363 NBCMU03_MaxConChrgCurnt "Maximum Continuous  Charging Current
最大持续充电电流";
CM_ SG_ 2562195363 NBCMU03_MaxInstanDisCurnt "Maximum Instantaneous Discharging Current
电池最大瞬时放电电流";
CM_ SG_ 2562195363 NBCMU03_MaxInstanChrgCurnt "Maximum  Instantaneous Charging Current
能量回收最大瞬时充电电流";
CM_ BO_ 2560884643 "NBCMU Tx and WarningInfo3 Related";
CM_ SG_ 2560884643 NBCMU03_SumVolt_HighWarning "NBCMU电池包累加总压过压";
CM_ SG_ 2560884643 NBCMU03_SumVolt_LowWarning "NBCMU电池包累加总压欠压";
CM_ SG_ 2560884643 NBCMU03_CurrentLoop_HighWarning "电池簇间环流故障";
CM_ SG_ 2560884643 NBCMU03_ProtectFault "NBCMU保护功能故障";
CM_ SG_ 2560884643 NBCMU03_RunLed_State "NBCMU Run Led State
NBCMU运行LED灯状态";
CM_ SG_ 2560884643 NBCMU03_Buzz_State "NBCMU Buzz State
NBCMU蜂鸣器状态";
CM_ SG_ 2560884643 NBCMU03_Heating_State "NBCMU Heating State
NBCMU加热开启状态";
CM_ SG_ 2560884643 NBCMU03_Cooling_State "NBCMU Cooling State
NBCMU冷却开启状态";
CM_ SG_ 2560884643 NBCMU03_BattVoltDiff_Warning "NBCMU电池包一致性故障";
CM_ SG_ 2560884643 NBCMU03_EmergyShutdown_Fault "NBCMU急停故障";
CM_ SG_ 2560884643 NBCMU03_PCS_TimeOut "NBCMU检测PCS通信失败";
CM_ SG_ 2560884643 NBCMU03_EMS_TimeOut "NBCMU检测EMS通信失败";
CM_ SG_ 2560884643 NBCMU03_TMS_TimeOut "NBCMU检测TMS通信失败";
CM_ SG_ 2560884643 NBCMU03_SBCMU01_TimeOut "NBCMU检测簇安全板通信失败";
CM_ SG_ 2560884643 NBCMU03_InitialFault "NBCMU初始化故障";
CM_ SG_ 2560884643 NBCMU03_ThermalManagement_Fault "NBCMU热管理故障";
CM_ SG_ 2560884643 NBCMU03_DCS_ActOprtMode "DC Charging System Actual Operating Mode
直流充电实际状态";
CM_ SG_ 2560884643 NBCMU03_ChrgFault "NBCMU充电故障";
CM_ SG_ 2560884643 NBCMU03_DC_ChrgEnable "NBCMU直流充电允许";
CM_ SG_ 2560884643 NBCMU03_Contactor_DC_Cmd "直流充电继电器指令";
CM_ SG_ 2560884643 NBCMU03_MaxAllowChrgCur_DC "DC Charging System Maximum Allowed Charging Current
直流充电最大允许充电电流";
CM_ SG_ 2560884643 NBCMU03_MaxAllowChrgVol_DC "DC Charging System Maximum Allowed Charging Voltage
直流充电最大允许充电电压";
CM_ BO_ 2561605539 "NBCMU Tx and VIN FeedBack";
CM_ SG_ 2561605539 NBCMU03_VIN01 "VIN Byte 01
VIN第01个字节";
CM_ SG_ 2561605539 NBCMU03_VIN02 "VIN Byte 02
VIN第02个字节";
CM_ SG_ 2561605539 NBCMU03_VIN03 "VIN Byte 03
VIN第03个字节";
CM_ SG_ 2561605539 NBCMU03_VIN04 "VIN Byte 04
VIN第04个字节";
CM_ SG_ 2561605539 NBCMU03_VIN05 "VIN Byte 05
VIN第05个字节";
CM_ SG_ 2561605539 NBCMU03_VIN06 "VIN Byte 06
VIN第06个字节";
CM_ SG_ 2561605539 NBCMU03_VIN07 "VIN Byte 07
VIN第07个字节";
CM_ SG_ 2561605539 NBCMU03_VIN08 "VIN Byte 08
VIN第08个字节";
CM_ BO_ 2564947875 "NBCMU Tx and Software";
CM_ SG_ 2564947875 NBCMU03_SW01 "NBCMU Software Byte 01
NBCMU软件版本第01字节";
CM_ SG_ 2564947875 NBCMU03_SW02 "NBCMU Software Byte 02
NBCMU软件版本第02字节";
CM_ SG_ 2564947875 NBCMU03_SW03 "NBCMU Software Byte 03
NBCMU软件版本第03字节";
CM_ SG_ 2564947875 NBCMU03_SW04 "NBCMU Software Byte 04
NBCMU软件版本第04字节";
CM_ SG_ 2564947875 NBCMU03_SW05 "NBCMU Software Byte 05
NBCMU软件版本第05字节";
CM_ SG_ 2564947875 NBCMU03_SW06 "NBCMU Software Byte 06
NBCMU软件版本第06字节";
CM_ SG_ 2564947875 NBCMU03_SW07 "NBCMU Software Byte 07
NBCMU软件版本第07字节";
CM_ BO_ 2565013411 "NBCMU Tx and Hardware";
CM_ SG_ 2565013411 NBCMU03_HW01 "NBCMU Hardware Byte 01
NBCMU硬件版本第01字节";
CM_ SG_ 2565013411 NBCMU03_HW02 "NBCMU Hardware Byte 02
NBCMU硬件版本第02字节";
CM_ SG_ 2565013411 NBCMU03_HW03 "NBCMU Hardware Byte 03
NBCMU硬件版本第03字节";
CM_ SG_ 2565013411 NBCMU03_HW04 "NBCMU Hardware Byte 04
NBCMU硬件版本第04字节";
CM_ SG_ 2565013411 NBCMU03_HW05 "NBCMU Hardware Byte 05
NBCMU硬件版本第05字节";
CM_ SG_ 2565013411 NBCMU03_HW06 "NBCMU Hardware Byte 06
NBCMU硬件版本第06字节";
CM_ SG_ 2565013411 NBCMU03_HW07 "NBCMU Hardware Byte 07
NBCMU硬件版本第07字节";
CM_ BO_ 2561736612 "NBCMU Tx and Run State";
CM_ SG_ 2561736612 NBCMU04_Address "NBCMU_Address有效地址";
CM_ SG_ 2561736612 NBCMU04_NBICUnum "NBICUnum
配置电池包管理单元总数";
CM_ SG_ 2561736612 NBCMU04_SysCurr "SysCurr
系统电流值";
CM_ SG_ 2561736612 NBCMU04_Contactor_state_Negative "Negative contactor state
主负继电器状态";
CM_ SG_ 2561736612 NBCMU04_Contactor_state_Positive "Positive contactor state
主正继电器状态";
CM_ SG_ 2561736612 NBCMU04_Contactor_state_PreChrg "Precharge contactor state
预充继电器状态";
CM_ SG_ 2561736612 NBCMU04_Contactor_state_Heat "Heat contactor state
加热继电器状态";
CM_ SG_ 2561736612 NBCMU04_WorkState "Work State
工作状态";
CM_ SG_ 2561736612 NBCMU04_SoftVer "SoftVer
软件版本";
CM_ SG_ 2561736612 NBCMU04_HardVer "HardVer
硬件版本";
CM_ SG_ 2561736612 NBCMU04_AliveCounter "Alive Counter";
CM_ BO_ 2561802148 "NBCMU Tx and WarningInfo1";
CM_ SG_ 2561802148 NBCMU04_HeatCurr "HeatCurr
加热电流值";
CM_ SG_ 2561802148 NBCMU04_SysFailSta "System Failure Status
NBCMU失效状态";
CM_ SG_ 2561802148 NBCMU04_InsRes_polarity "System InsRes polarity
NBCMU绝缘电阻极性";
CM_ SG_ 2561802148 NBCMU04_BattVolt_HighWarning "总压过压(过充)";
CM_ SG_ 2561802148 NBCMU04_BattVolt_LowWarning "总压欠压(过放)";
CM_ SG_ 2561802148 NBCMU04_CellVolt_HighWarning "单体过压(过充)";
CM_ SG_ 2561802148 NBCMU04_CellVolt_LowWarning "单体欠压(过放)";
CM_ SG_ 2561802148 NBCMU04_ChrgTemp_HighWarning "充电(单体)温度过高";
CM_ SG_ 2561802148 NBCMU04_ChrgTemp_LowWarning "充电(单体)温度过低";
CM_ SG_ 2561802148 NBCMU04_DischrgTemp_HighWarning "放电(单体)温度过高";
CM_ SG_ 2561802148 NBCMU04_DischrgTemp_LowWarning "放电(单体)温度过低";
CM_ SG_ 2561802148 NBCMU04_TempDiff_Warning "(电池)温差过大";
CM_ SG_ 2561802148 NBCMU04_CellVoltDiff_Warning "(电池)压差过大";
CM_ SG_ 2561802148 NBCMU04_DischrgCurr_OverWarning "放电过流";
CM_ SG_ 2561802148 NBCMU04_ChrgCurr_OverWarning "充电过流";
CM_ SG_ 2561802148 NBCMU04_InsulationWarning "绝缘故障";
CM_ SG_ 2561802148 NBCMU04_SOC_LowWarning "SOC过低";
CM_ SG_ 2561802148 NBCMU04_AmbientTemp_HighWarning "环境温度过高";
CM_ SG_ 2561802148 NBCMU04_AmbientTemp_LowWarning "环境温度过低";
CM_ SG_ 2561802148 NBCMU04_ContactorPosi_Fault "主正继电器故障";
CM_ SG_ 2561802148 NBCMU04_ContactorNega_Fault "主负继电器故障";
CM_ SG_ 2561802148 NBCMU04_ContactorBalan_Fault "均衡继电器故障";
CM_ SG_ 2561802148 NBCMU04_ContactorHeat_Fault "加热继电器故障";
CM_ SG_ 2561802148 NBCMU04_CurrSensor_TimeOut "霍尔电流传感器通讯丢失";
CM_ SG_ 2561802148 NBCMU04_SOH_LowWarning "SOH过低";
CM_ SG_ 2561802148 NBCMU04_HVIL_Fault "NBCMU高压互锁故障";
CM_ SG_ 2561802148 NBCMU04_Fuse_Fault "NBCMU熔断器故障";
CM_ BO_ 2562457508 "NBCMU Tx and WarningInfo2";
CM_ SG_ 2562457508 NBCMU04_ErrTab "Error Table
故障码";
CM_ SG_ 2562457508 NBCMU04_FaultSum "Fault Sum
故障总数";
CM_ SG_ 2562457508 NBCMU04_NBICU_TimeOut "BICU通讯丢失";
CM_ SG_ 2562457508 NBCMU04_PrechrgFault "预充失败故障";
CM_ SG_ 2562457508 NBCMU04_SupplyVolt_HighWarning "供电电压过高";
CM_ SG_ 2562457508 NBCMU04_SupplyVolt_LowWarning "供电电压过低";
CM_ SG_ 2562457508 NBCMU04_CellVoltOpen "单体电压采样断线";
CM_ SG_ 2562457508 NBCMU04_CellTempOpen "单体温度采样断线";
CM_ SG_ 2562457508 NBCMU04_AccChrgCapa "NBCMU Acc Charge Capacity
NBCMU累计充电容量";
CM_ SG_ 2562457508 NBCMU04_BoxInterTemp "Ambient Temperature
NBCMU采集箱内温度";
CM_ SG_ 2562457508 NBCMU04_ReservedTemp "Reserved Temperature
NBCMU采集预留温度温度";
CM_ BO_ 2561867684 "NBCMU Tx and VoltExtremeInfo";
CM_ SG_ 2561867684 NBCMU04_SysCellVoltMax "SysCellVoltMax
系统最高单体电压";
CM_ SG_ 2561867684 NBCMU04_SysVMax_NBICUadd "SysVMax_NBICUadd
最高单体电压所处从机地址";
CM_ SG_ 2561867684 NBCMU04_SysVMax_Code "SysVMax_Code
最高单体电压对应编号";
CM_ SG_ 2561867684 NBCMU04_SysCellVoltMin "SysCellVoltMin
系统最低单体电压";
CM_ SG_ 2561867684 NBCMU04_SysVMin_NBICUadd "SysVMin_NBICUadd
最低单体电压所处从机地址";
CM_ SG_ 2561867684 NBCMU04_SysVMin_Code "SysVMinx_Code
最低单体电压对应编号";
CM_ BO_ 2561933220 "NBCMU Tx and TempExtremeInfo";
CM_ SG_ 2561933220 NBCMU04_SysTempMax "系统最高单体温度";
CM_ SG_ 2561933220 NBCMU04_SysTMax_NBICUadd "最高单体温度所处从机地址";
CM_ SG_ 2561933220 NBCMU04_SysTMax_Code "最高单体温度对应编号";
CM_ SG_ 2561933220 NBCMU04_SysTempMin "系统最低单体温度";
CM_ SG_ 2561933220 NBCMU04_SysTMin_NBICUadd "最低单体温度所处从机地址";
CM_ SG_ 2561933220 NBCMU04_SysTMin_Code "最低单体温度对应编号";
CM_ SG_ 2561933220 NBCMU04_AmbientTemp "Ambient Temperature
NBCMU采集环境温度";
CM_ SG_ 2561933220 NBCMU04_BalaResTemp "Balance Resistance Temperature
NBCMU采集均衡电阻温度";
CM_ BO_ 2561998756 "NBCMU Tx and SOX";
CM_ SG_ 2561998756 NBCMU04_SysSOC_Actl "电池簇真实SOC";
CM_ SG_ 2561998756 NBCMU04_SysSOC_Dis "电池簇显示SOC";
CM_ SG_ 2561998756 NBCMU04_SysSOH_ByNBICU "SysSOH
电池簇SOH(统计NBICU)";
CM_ SG_ 2561998756 NBCMU04_SysSOH_Cal "SysSOH
电池簇SOH(NBCMU计算)";
CM_ SG_ 2561998756 NBCMU04_SysSOE "SysSOE
系统剩余能量SOE";
CM_ BO_ 2562064292 "NBCMU Tx andSysHVoltage";
CM_ SG_ 2562064292 NBCMU04_SysHVoltage "SysHVoltage
系统电池总压";
CM_ SG_ 2562064292 NBCMU04_SysSumVoltage "SysSumVoltage
系统累加总压";
CM_ SG_ 2562064292 NBCMU04_SysSampVoltage "SysSampVoltage
系统母线总压";
CM_ SG_ 2562064292 NBCMU04_SysInsRes "SysInsRes
系统绝缘阻值";
CM_ BO_ 2562195364 "NBCMU Tx and DischrgChrg";
CM_ SG_ 2562195364 NBCMU04_MaxConDisCurnt "Maximum continuous discharging current
最大持续放电电流";
CM_ SG_ 2562195364 NBCMU04_MaxConChrgCurnt "Maximum Continuous  Charging Current
最大持续充电电流";
CM_ SG_ 2562195364 NBCMU04_MaxInstanDisCurnt "Maximum Instantaneous Discharging Current
电池最大瞬时放电电流";
CM_ SG_ 2562195364 NBCMU04_MaxInstanChrgCurnt "Maximum  Instantaneous Charging Current
能量回收最大瞬时充电电流";
CM_ BO_ 2560884644 "NBCMU Tx and WarningInfo3 Related";
CM_ SG_ 2560884644 NBCMU04_SumVolt_HighWarning "NBCMU电池包累加总压过压";
CM_ SG_ 2560884644 NBCMU04_SumVolt_LowWarning "NBCMU电池包累加总压欠压";
CM_ SG_ 2560884644 NBCMU04_CurrentLoop_HighWarning "电池簇间环流故障";
CM_ SG_ 2560884644 NBCMU04_ProtectFault "NBCMU保护功能故障";
CM_ SG_ 2560884644 NBCMU04_RunLed_State "NBCMU Run Led State
NBCMU运行LED灯状态";
CM_ SG_ 2560884644 NBCMU04_Buzz_State "NBCMU Buzz State
NBCMU蜂鸣器状态";
CM_ SG_ 2560884644 NBCMU04_Heating_State "NBCMU Heating State
NBCMU加热开启状态";
CM_ SG_ 2560884644 NBCMU04_Cooling_State "NBCMU Cooling State
NBCMU冷却开启状态";
CM_ SG_ 2560884644 NBCMU04_BattVoltDiff_Warning "NBCMU电池包一致性故障";
CM_ SG_ 2560884644 NBCMU04_EmergyShutdown_Fault "NBCMU急停故障";
CM_ SG_ 2560884644 NBCMU04_PCS_TimeOut "NBCMU检测PCS通信失败";
CM_ SG_ 2560884644 NBCMU04_EMS_TimeOut "NBCMU检测EMS通信失败";
CM_ SG_ 2560884644 NBCMU04_TMS_TimeOut "NBCMU检测TMS通信失败";
CM_ SG_ 2560884644 NBCMU04_SBCMU01_TimeOut "NBCMU检测簇安全板通信失败";
CM_ SG_ 2560884644 NBCMU04_InitialFault "NBCMU初始化故障";
CM_ SG_ 2560884644 NBCMU04_ThermalManagement_Fault "NBCMU热管理故障";
CM_ SG_ 2560884644 NBCMU04_DCS_ActOprtMode "DC Charging System Actual Operating Mode
直流充电实际状态";
CM_ SG_ 2560884644 NBCMU04_ChrgFault "NBCMU充电故障";
CM_ SG_ 2560884644 NBCMU04_DC_ChrgEnable "NBCMU直流充电允许";
CM_ SG_ 2560884644 NBCMU04_Contactor_DC_Cmd "直流充电继电器指令";
CM_ SG_ 2560884644 NBCMU04_MaxAllowChrgCur_DC "DC Charging System Maximum Allowed Charging Current
直流充电最大允许充电电流";
CM_ SG_ 2560884644 NBCMU04_MaxAllowChrgVol_DC "DC Charging System Maximum Allowed Charging Voltage
直流充电最大允许充电电压";
CM_ BO_ 2561605540 "NBCMU Tx and VIN FeedBack";
CM_ SG_ 2561605540 NBCMU04_VIN01 "VIN Byte 01
VIN第01个字节";
CM_ SG_ 2561605540 NBCMU04_VIN02 "VIN Byte 02
VIN第02个字节";
CM_ SG_ 2561605540 NBCMU04_VIN03 "VIN Byte 03
VIN第03个字节";
CM_ SG_ 2561605540 NBCMU04_VIN04 "VIN Byte 04
VIN第04个字节";
CM_ SG_ 2561605540 NBCMU04_VIN05 "VIN Byte 05
VIN第05个字节";
CM_ SG_ 2561605540 NBCMU04_VIN06 "VIN Byte 06
VIN第06个字节";
CM_ SG_ 2561605540 NBCMU04_VIN07 "VIN Byte 07
VIN第07个字节";
CM_ SG_ 2561605540 NBCMU04_VIN08 "VIN Byte 08
VIN第08个字节";
CM_ BO_ 2564947876 "NBCMU Tx and Software";
CM_ SG_ 2564947876 NBCMU04_SW01 "NBCMU Software Byte 01
NBCMU软件版本第01字节";
CM_ SG_ 2564947876 NBCMU04_SW02 "NBCMU Software Byte 02
NBCMU软件版本第02字节";
CM_ SG_ 2564947876 NBCMU04_SW03 "NBCMU Software Byte 03
NBCMU软件版本第03字节";
CM_ SG_ 2564947876 NBCMU04_SW04 "NBCMU Software Byte 04
NBCMU软件版本第04字节";
CM_ SG_ 2564947876 NBCMU04_SW05 "NBCMU Software Byte 05
NBCMU软件版本第05字节";
CM_ SG_ 2564947876 NBCMU04_SW06 "NBCMU Software Byte 06
NBCMU软件版本第06字节";
CM_ SG_ 2564947876 NBCMU04_SW07 "NBCMU Software Byte 07
NBCMU软件版本第07字节";
CM_ BO_ 2565013412 "NBCMU Tx and Hardware";
CM_ SG_ 2565013412 NBCMU04_HW01 "NBCMU Hardware Byte 01
NBCMU硬件版本第01字节";
CM_ SG_ 2565013412 NBCMU04_HW02 "NBCMU Hardware Byte 02
NBCMU硬件版本第02字节";
CM_ SG_ 2565013412 NBCMU04_HW03 "NBCMU Hardware Byte 03
NBCMU硬件版本第03字节";
CM_ SG_ 2565013412 NBCMU04_HW04 "NBCMU Hardware Byte 04
NBCMU硬件版本第04字节";
CM_ SG_ 2565013412 NBCMU04_HW05 "NBCMU Hardware Byte 05
NBCMU硬件版本第05字节";
CM_ SG_ 2565013412 NBCMU04_HW06 "NBCMU Hardware Byte 06
NBCMU硬件版本第06字节";
CM_ SG_ 2565013412 NBCMU04_HW07 "NBCMU Hardware Byte 07
NBCMU硬件版本第07字节";
CM_ BO_ 2561736613 "NBCMU Tx and Run State";
CM_ SG_ 2561736613 NBCMU05_Address "NBCMU_Address有效地址";
CM_ SG_ 2561736613 NBCMU05_NBICUnum "NBICUnum
配置电池包管理单元总数";
CM_ SG_ 2561736613 NBCMU05_SysCurr "SysCurr
系统电流值";
CM_ SG_ 2561736613 NBCMU05_Contactor_state_Negative "Negative contactor state
主负继电器状态";
CM_ SG_ 2561736613 NBCMU05_Contactor_state_Positive "Positive contactor state
主正继电器状态";
CM_ SG_ 2561736613 NBCMU05_Contactor_state_PreChrg "Precharge contactor state
预充继电器状态";
CM_ SG_ 2561736613 NBCMU05_Contactor_state_Heat "Heat contactor state
加热继电器状态";
CM_ SG_ 2561736613 NBCMU05_WorkState "Work State
工作状态";
CM_ SG_ 2561736613 NBCMU05_SoftVer "SoftVer
软件版本";
CM_ SG_ 2561736613 NBCMU05_HardVer "HardVer
硬件版本";
CM_ SG_ 2561736613 NBCMU05_AliveCounter "Alive Counter";
CM_ BO_ 2561802149 "NBCMU Tx and WarningInfo1";
CM_ SG_ 2561802149 NBCMU05_HeatCurr "HeatCurr
加热电流值";
CM_ SG_ 2561802149 NBCMU05_SysFailSta "System Failure Status
NBCMU失效状态";
CM_ SG_ 2561802149 NBCMU05_InsRes_polarity "System InsRes polarity
NBCMU绝缘电阻极性";
CM_ SG_ 2561802149 NBCMU05_BattVolt_HighWarning "总压过压(过充)";
CM_ SG_ 2561802149 NBCMU05_BattVolt_LowWarning "总压欠压(过放)";
CM_ SG_ 2561802149 NBCMU05_CellVolt_HighWarning "单体过压(过充)";
CM_ SG_ 2561802149 NBCMU05_CellVolt_LowWarning "单体欠压(过放)";
CM_ SG_ 2561802149 NBCMU05_ChrgTemp_HighWarning "充电(单体)温度过高";
CM_ SG_ 2561802149 NBCMU05_ChrgTemp_LowWarning "充电(单体)温度过低";
CM_ SG_ 2561802149 NBCMU05_DischrgTemp_HighWarning "放电(单体)温度过高";
CM_ SG_ 2561802149 NBCMU05_DischrgTemp_LowWarning "放电(单体)温度过低";
CM_ SG_ 2561802149 NBCMU05_TempDiff_Warning "(电池)温差过大";
CM_ SG_ 2561802149 NBCMU05_CellVoltDiff_Warning "(电池)压差过大";
CM_ SG_ 2561802149 NBCMU05_DischrgCurr_OverWarning "放电过流";
CM_ SG_ 2561802149 NBCMU05_ChrgCurr_OverWarning "充电过流";
CM_ SG_ 2561802149 NBCMU05_InsulationWarning "绝缘故障";
CM_ SG_ 2561802149 NBCMU05_SOC_LowWarning "SOC过低";
CM_ SG_ 2561802149 NBCMU05_AmbientTemp_HighWarning "环境温度过高";
CM_ SG_ 2561802149 NBCMU05_AmbientTemp_LowWarning "环境温度过低";
CM_ SG_ 2561802149 NBCMU05_ContactorPosi_Fault "主正继电器故障";
CM_ SG_ 2561802149 NBCMU05_ContactorNega_Fault "主负继电器故障";
CM_ SG_ 2561802149 NBCMU05_ContactorBalan_Fault "均衡继电器故障";
CM_ SG_ 2561802149 NBCMU05_ContactorHeat_Fault "加热继电器故障";
CM_ SG_ 2561802149 NBCMU05_CurrSensor_TimeOut "霍尔电流传感器通讯丢失";
CM_ SG_ 2561802149 NBCMU05_SOH_LowWarning "SOH过低";
CM_ SG_ 2561802149 NBCMU05_HVIL_Fault "NBCMU高压互锁故障";
CM_ SG_ 2561802149 NBCMU05_Fuse_Fault "NBCMU熔断器故障";
CM_ BO_ 2562457509 "NBCMU Tx and WarningInfo2";
CM_ SG_ 2562457509 NBCMU05_ErrTab "Error Table
故障码";
CM_ SG_ 2562457509 NBCMU05_FaultSum "Fault Sum
故障总数";
CM_ SG_ 2562457509 NBCMU05_NBICU_TimeOut "BICU通讯丢失";
CM_ SG_ 2562457509 NBCMU05_PrechrgFault "预充失败故障";
CM_ SG_ 2562457509 NBCMU05_SupplyVolt_HighWarning "供电电压过高";
CM_ SG_ 2562457509 NBCMU05_SupplyVolt_LowWarning "供电电压过低";
CM_ SG_ 2562457509 NBCMU05_CellVoltOpen "单体电压采样断线";
CM_ SG_ 2562457509 NBCMU05_CellTempOpen "单体温度采样断线";
CM_ SG_ 2562457509 NBCMU05_AccChrgCapa "NBCMU Acc Charge Capacity
NBCMU累计充电容量";
CM_ SG_ 2562457509 NBCMU05_BoxInterTemp "Ambient Temperature
NBCMU采集箱内温度";
CM_ SG_ 2562457509 NBCMU05_ReservedTemp "Reserved Temperature
NBCMU采集预留温度温度";
CM_ BO_ 2561867685 "NBCMU Tx and VoltExtremeInfo";
CM_ SG_ 2561867685 NBCMU05_SysCellVoltMax "SysCellVoltMax
系统最高单体电压";
CM_ SG_ 2561867685 NBCMU05_SysVMax_NBICUadd "SysVMax_NBICUadd
最高单体电压所处从机地址";
CM_ SG_ 2561867685 NBCMU05_SysVMax_Code "SysVMax_Code
最高单体电压对应编号";
CM_ SG_ 2561867685 NBCMU05_SysCellVoltMin "SysCellVoltMin
系统最低单体电压";
CM_ SG_ 2561867685 NBCMU05_SysVMin_NBICUadd "SysVMin_NBICUadd
最低单体电压所处从机地址";
CM_ SG_ 2561867685 NBCMU05_SysVMin_Code "SysVMinx_Code
最低单体电压对应编号";
CM_ BO_ 2561933221 "NBCMU Tx and TempExtremeInfo";
CM_ SG_ 2561933221 NBCMU05_SysTempMax "系统最高单体温度";
CM_ SG_ 2561933221 NBCMU05_SysTMax_NBICUadd "最高单体温度所处从机地址";
CM_ SG_ 2561933221 NBCMU05_SysTMax_Code "最高单体温度对应编号";
CM_ SG_ 2561933221 NBCMU05_SysTempMin "系统最低单体温度";
CM_ SG_ 2561933221 NBCMU05_SysTMin_NBICUadd "最低单体温度所处从机地址";
CM_ SG_ 2561933221 NBCMU05_SysTMin_Code "最低单体温度对应编号";
CM_ SG_ 2561933221 NBCMU05_AmbientTemp "Ambient Temperature
NBCMU采集环境温度";
CM_ SG_ 2561933221 NBCMU05_BalaResTemp "Balance Resistance Temperature
NBCMU采集均衡电阻温度";
CM_ BO_ 2561998757 "NBCMU Tx and SOX";
CM_ SG_ 2561998757 NBCMU05_SysSOC_Actl "电池簇真实SOC";
CM_ SG_ 2561998757 NBCMU05_SysSOC_Dis "电池簇显示SOC";
CM_ SG_ 2561998757 NBCMU05_SysSOH_ByNBICU "SysSOH
电池簇SOH(统计NBICU)";
CM_ SG_ 2561998757 NBCMU05_SysSOH_Cal "SysSOH
电池簇SOH(NBCMU计算)";
CM_ SG_ 2561998757 NBCMU05_SysSOE "SysSOE
系统剩余能量SOE";
CM_ BO_ 2562064293 "NBCMU Tx andSysHVoltage";
CM_ SG_ 2562064293 NBCMU05_SysHVoltage "SysHVoltage
系统电池总压";
CM_ SG_ 2562064293 NBCMU05_SysSumVoltage "SysSumVoltage
系统累加总压";
CM_ SG_ 2562064293 NBCMU05_SysSampVoltage "SysSampVoltage
系统母线总压";
CM_ SG_ 2562064293 NBCMU05_SysInsRes "SysInsRes
系统绝缘阻值";
CM_ BO_ 2562195365 "NBCMU Tx and DischrgChrg";
CM_ SG_ 2562195365 NBCMU05_MaxConDisCurnt "Maximum continuous discharging current
最大持续放电电流";
CM_ SG_ 2562195365 NBCMU05_MaxConChrgCurnt "Maximum Continuous  Charging Current
最大持续充电电流";
CM_ SG_ 2562195365 NBCMU05_MaxInstanDisCurnt "Maximum Instantaneous Discharging Current
电池最大瞬时放电电流";
CM_ SG_ 2562195365 NBCMU05_MaxInstanChrgCurnt "Maximum  Instantaneous Charging Current
能量回收最大瞬时充电电流";
CM_ BO_ 2560884645 "NBCMU Tx and WarningInfo3 Related";
CM_ SG_ 2560884645 NBCMU05_SumVolt_HighWarning "NBCMU电池包累加总压过压";
CM_ SG_ 2560884645 NBCMU05_SumVolt_LowWarning "NBCMU电池包累加总压欠压";
CM_ SG_ 2560884645 NBCMU05_CurrentLoop_HighWarning "电池簇间环流故障";
CM_ SG_ 2560884645 NBCMU05_ProtectFault "NBCMU保护功能故障";
CM_ SG_ 2560884645 NBCMU05_RunLed_State "NBCMU Run Led State
NBCMU运行LED灯状态";
CM_ SG_ 2560884645 NBCMU05_Buzz_State "NBCMU Buzz State
NBCMU蜂鸣器状态";
CM_ SG_ 2560884645 NBCMU05_Heating_State "NBCMU Heating State
NBCMU加热开启状态";
CM_ SG_ 2560884645 NBCMU05_Cooling_State "NBCMU Cooling State
NBCMU冷却开启状态";
CM_ SG_ 2560884645 NBCMU05_BattVoltDiff_Warning "NBCMU电池包一致性故障";
CM_ SG_ 2560884645 NBCMU05_EmergyShutdown_Fault "NBCMU急停故障";
CM_ SG_ 2560884645 NBCMU05_PCS_TimeOut "NBCMU检测PCS通信失败";
CM_ SG_ 2560884645 NBCMU05_EMS_TimeOut "NBCMU检测EMS通信失败";
CM_ SG_ 2560884645 NBCMU05_TMS_TimeOut "NBCMU检测TMS通信失败";
CM_ SG_ 2560884645 NBCMU05_SBCMU01_TimeOut "NBCMU检测簇安全板通信失败";
CM_ SG_ 2560884645 NBCMU05_InitialFault "NBCMU初始化故障";
CM_ SG_ 2560884645 NBCMU05_ThermalManagement_Fault "NBCMU热管理故障";
CM_ SG_ 2560884645 NBCMU05_DCS_ActOprtMode "DC Charging System Actual Operating Mode
直流充电实际状态";
CM_ SG_ 2560884645 NBCMU05_ChrgFault "NBCMU充电故障";
CM_ SG_ 2560884645 NBCMU05_DC_ChrgEnable "NBCMU直流充电允许";
CM_ SG_ 2560884645 NBCMU05_Contactor_DC_Cmd "直流充电继电器指令";
CM_ SG_ 2560884645 NBCMU05_MaxAllowChrgCur_DC "DC Charging System Maximum Allowed Charging Current
直流充电最大允许充电电流";
CM_ SG_ 2560884645 NBCMU05_MaxAllowChrgVol_DC "DC Charging System Maximum Allowed Charging Voltage
直流充电最大允许充电电压";
CM_ BO_ 2561605541 "NBCMU Tx and VIN FeedBack";
CM_ SG_ 2561605541 NBCMU05_VIN01 "VIN Byte 01
VIN第01个字节";
CM_ SG_ 2561605541 NBCMU05_VIN02 "VIN Byte 02
VIN第02个字节";
CM_ SG_ 2561605541 NBCMU05_VIN03 "VIN Byte 03
VIN第03个字节";
CM_ SG_ 2561605541 NBCMU05_VIN04 "VIN Byte 04
VIN第04个字节";
CM_ SG_ 2561605541 NBCMU05_VIN05 "VIN Byte 05
VIN第05个字节";
CM_ SG_ 2561605541 NBCMU05_VIN06 "VIN Byte 06
VIN第06个字节";
CM_ SG_ 2561605541 NBCMU05_VIN07 "VIN Byte 07
VIN第07个字节";
CM_ SG_ 2561605541 NBCMU05_VIN08 "VIN Byte 08
VIN第08个字节";
CM_ BO_ 2564947877 "NBCMU Tx and Software";
CM_ SG_ 2564947877 NBCMU05_SW01 "NBCMU Software Byte 01
NBCMU软件版本第01字节";
CM_ SG_ 2564947877 NBCMU05_SW02 "NBCMU Software Byte 02
NBCMU软件版本第02字节";
CM_ SG_ 2564947877 NBCMU05_SW03 "NBCMU Software Byte 03
NBCMU软件版本第03字节";
CM_ SG_ 2564947877 NBCMU05_SW04 "NBCMU Software Byte 04
NBCMU软件版本第04字节";
CM_ SG_ 2564947877 NBCMU05_SW05 "NBCMU Software Byte 05
NBCMU软件版本第05字节";
CM_ SG_ 2564947877 NBCMU05_SW06 "NBCMU Software Byte 06
NBCMU软件版本第06字节";
CM_ SG_ 2564947877 NBCMU05_SW07 "NBCMU Software Byte 07
NBCMU软件版本第07字节";
CM_ BO_ 2565013413 "NBCMU Tx and Hardware";
CM_ SG_ 2565013413 NBCMU05_HW01 "NBCMU Hardware Byte 01
NBCMU硬件版本第01字节";
CM_ SG_ 2565013413 NBCMU05_HW02 "NBCMU Hardware Byte 02
NBCMU硬件版本第02字节";
CM_ SG_ 2565013413 NBCMU05_HW03 "NBCMU Hardware Byte 03
NBCMU硬件版本第03字节";
CM_ SG_ 2565013413 NBCMU05_HW04 "NBCMU Hardware Byte 04
NBCMU硬件版本第04字节";
CM_ SG_ 2565013413 NBCMU05_HW05 "NBCMU Hardware Byte 05
NBCMU硬件版本第05字节";
CM_ SG_ 2565013413 NBCMU05_HW06 "NBCMU Hardware Byte 06
NBCMU硬件版本第06字节";
CM_ SG_ 2565013413 NBCMU05_HW07 "NBCMU Hardware Byte 07
NBCMU硬件版本第07字节";
CM_ BO_ 2562326448 "SBCMU Tx and SBICUControl";
CM_ SG_ 2562326448 SBCMU_OnlineSBICUnum "OnlineSBICUnum
识别在线SBICU总数";
CM_ SG_ 2562326448 SBCMU_SBICU_Address "SBCMU01 SBICU Address
SBCMU01发给SBICU地址";
CM_ BO_ 2562260913 "SBCMU Tx and WarningInfo";
CM_ SG_ 2562260913 SBCMU01_ErrTab "Error Table
故障码";
CM_ SG_ 2562260913 SBCMU01_FaultSum "Fault Sum
故障总数";
CM_ SG_ 2562260913 SBCMU01_BattVolt_HighWarning "总压过压(过充)";
CM_ SG_ 2562260913 SBCMU01_SumVolt_HighWarning "电池包累加总压过压";
CM_ SG_ 2562260913 SBCMU01_CellVolt_HighWarning "单体过压(过充)";
CM_ SG_ 2562260913 SBCMU01_Temp_HighWarning "单体过高温报警";
CM_ SG_ 2562260913 SBCMU01_AmbientTemp_HighWarning "环境过高温报警";
CM_ SG_ 2562260913 SBCMU01_SysFailSta "System Failure Status
SBCMU失效状态";
CM_ SG_ 2562260913 SBCMU01_SBICU_TimeOut "SBICU通讯丢失";
CM_ SG_ 2562260913 SBCMU01_CellTempOpen "单体温度采样断线";
CM_ SG_ 2562260913 SBCMU01_SupplyVolt_HighWarning "供电电压过高";
CM_ SG_ 2562260913 SBCMU01_SupplyVolt_LowWarning "供电电压过低";
CM_ BO_ 2562391985 "SBCMU Tx and Run State";
CM_ SG_ 2562391985 SBCMU01_Address "SBCMU_Address有效地址";
CM_ SG_ 2562391985 SBCMU01_SBICUnum "SBICUnum
配置电池包安全功能从控管理单元总数";
CM_ SG_ 2562391985 SBCMU01_WorkState "Work State
工作状态";
CM_ SG_ 2562391985 SBCMU01_Contactor_state_Safty "安全继电器状态";
CM_ SG_ 2562391985 SBCMU01_SoftVer "SoftVer
软件版本";
CM_ SG_ 2562391985 SBCMU01_HardVer "HardVer
硬件版本";
CM_ SG_ 2562391985 SBCMU01_AliveCounter "Alive Counter";
CM_ BO_ 2560819121 "SBCMU Tx and DC Charge Related";
CM_ SG_ 2560819121 SBCMU01_Electronic_Lock_State "Electronic Lock State
电子锁开关状态";
CM_ SG_ 2560819121 SBCMU01_DCS_InletConnectSta "DC Inlet Connect Status
直流枪插抢连接状态";
CM_ SG_ 2560819121 SBCMU01_DCS_ChrgAPlus "DC Charge A+
充电桩A+辅助信号";
CM_ SG_ 2560819121 SBCMU01_DCChrg_Stage "直流充电阶段";
CM_ SG_ 2560819121 SBCMU01_Contactor_state_DC "直流充电继电器状态";
CM_ SG_ 2560819121 SBCMU01_DCChrg_ISO_Enable "直流充电允许绝缘检测";
CM_ SG_ 2560819121 SBCMU01_SocketTemp_HighWarning "充电插座过温";
CM_ SG_ 2560819121 SBCMU01_DCChrg_Step "直流充电步骤";
CM_ SG_ 2560819121 SBCMU01_TempMax_ChargeSocket_Pos "DC Charge socket positive temperature
直流充电座正极温度";
CM_ SG_ 2560819121 SBCMU01_TempMax_ChargeSocket_Neg "DC Charge socket negative temperature
直流充电座负极温度";
CM_ BO_ 2564947889 "SBCMU Tx and Software";
CM_ SG_ 2564947889 SBCMU01_SW01 "SBCMU Software Byte 01
SBCMU软件版本第01字节";
CM_ SG_ 2564947889 SBCMU01_SW02 "SBCMU Software Byte 02
SBCMU软件版本第02字节";
CM_ SG_ 2564947889 SBCMU01_SW03 "SBCMU Software Byte 03
SBCMU软件版本第03字节";
CM_ SG_ 2564947889 SBCMU01_SW04 "SBCMU Software Byte 04
SBCMU软件版本第04字节";
CM_ SG_ 2564947889 SBCMU01_SW05 "SBCMU Software Byte 05
SBCMU软件版本第05字节";
CM_ SG_ 2564947889 SBCMU01_SW06 "SBCMU Software Byte 06
SBCMU软件版本第06字节";
CM_ SG_ 2564947889 SBCMU01_SW07 "SBCMU Software Byte 07
SBCMU软件版本第07字节";
CM_ BO_ 2565013425 "SBCMU Tx and Hardware";
CM_ SG_ 2565013425 SBCMU01_HW01 "SBCMU Hardware Byte 01
SBCMU硬件版本第01字节";
CM_ SG_ 2565013425 SBCMU01_HW02 "SBCMU Hardware Byte 02
SBCMU硬件版本第02字节";
CM_ SG_ 2565013425 SBCMU01_HW03 "SBCMU Hardware Byte 03
SBCMU硬件版本第03字节";
CM_ SG_ 2565013425 SBCMU01_HW04 "SBCMU Hardware Byte 04
SBCMU硬件版本第04字节";
CM_ SG_ 2565013425 SBCMU01_HW05 "SBCMU Hardware Byte 05
SBCMU硬件版本第05字节";
CM_ SG_ 2565013425 SBCMU01_HW06 "SBCMU Hardware Byte 06
SBCMU硬件版本第06字节";
CM_ SG_ 2565013425 SBCMU01_HW07 "SBCMU Hardware Byte 07
SBCMU硬件版本第07字节";
CM_ BO_ 2562260914 "SBCMU Tx and WarningInfo";
CM_ SG_ 2562260914 SBCMU02_ErrTab "Error Table
故障码";
CM_ SG_ 2562260914 SBCMU02_FaultSum "Fault Sum
故障总数";
CM_ SG_ 2562260914 SBCMU02_BattVolt_HighWarning "总压过压(过充)";
CM_ SG_ 2562260914 SBCMU02_SumVolt_HighWarning "电池包累加总压过压";
CM_ SG_ 2562260914 SBCMU02_CellVolt_HighWarning "单体过压(过充)";
CM_ SG_ 2562260914 SBCMU02_Temp_HighWarning "单体过高温报警";
CM_ SG_ 2562260914 SBCMU02_AmbientTemp_HighWarning "环境过高温报警";
CM_ SG_ 2562260914 SBCMU02_SysFailSta "System Failure Status
SBCMU失效状态";
CM_ SG_ 2562260914 SBCMU02_SBICU_TimeOut "SBICU通讯丢失";
CM_ SG_ 2562260914 SBCMU02_CellTempOpen "单体温度采样断线";
CM_ SG_ 2562260914 SBCMU02_SupplyVolt_HighWarning "供电电压过高";
CM_ SG_ 2562260914 SBCMU02_SupplyVolt_LowWarning "供电电压过低";
CM_ BO_ 2562391986 "SBCMU Tx and Run State";
CM_ SG_ 2562391986 SBCMU02_Address "SBCMU_Address有效地址";
CM_ SG_ 2562391986 SBCMU02_SBICUnum "SBICUnum
配置电池包安全功能从控管理单元总数";
CM_ SG_ 2562391986 SBCMU02_WorkState "Work State
工作状态";
CM_ SG_ 2562391986 SBCMU02_Contactor_state_Safty "安全继电器状态";
CM_ SG_ 2562391986 SBCMU02_SoftVer "SoftVer
软件版本";
CM_ SG_ 2562391986 SBCMU02_HardVer "HardVer
硬件版本";
CM_ SG_ 2562391986 SBCMU02_AliveCounter "Alive Counter";
CM_ BO_ 2560819122 "SBCMU Tx and DC Charge Related";
CM_ SG_ 2560819122 SBCMU02_Electronic_Lock_State "Electronic Lock State
电子锁开关状态";
CM_ SG_ 2560819122 SBCMU02_DCS_InletConnectSta "DC Inlet Connect Status
直流枪插抢连接状态";
CM_ SG_ 2560819122 SBCMU02_DCS_ChrgAPlus "DC Charge A+
充电桩A+辅助信号";
CM_ SG_ 2560819122 SBCMU02_DCChrg_Stage "直流充电阶段";
CM_ SG_ 2560819122 SBCMU02_Contactor_state_DC "直流充电继电器状态";
CM_ SG_ 2560819122 SBCMU02_DCChrg_ISO_Enable "直流充电允许绝缘检测";
CM_ SG_ 2560819122 SBCMU02_SocketTemp_HighWarning "充电插座过温";
CM_ SG_ 2560819122 SBCMU02_DCChrg_Step "直流充电步骤";
CM_ SG_ 2560819122 SBCMU02_TempMax_ChargeSocket_Pos "DC Charge socket positive temperature
直流充电座正极温度";
CM_ SG_ 2560819122 SBCMU02_TempMax_ChargeSocket_Neg "DC Charge socket negative temperature
直流充电座负极温度";
CM_ BO_ 2564947890 "SBCMU Tx and Software";
CM_ SG_ 2564947890 SBCMU02_SW01 "SBCMU Software Byte 01
SBCMU软件版本第01字节";
CM_ SG_ 2564947890 SBCMU02_SW02 "SBCMU Software Byte 02
SBCMU软件版本第02字节";
CM_ SG_ 2564947890 SBCMU02_SW03 "SBCMU Software Byte 03
SBCMU软件版本第03字节";
CM_ SG_ 2564947890 SBCMU02_SW04 "SBCMU Software Byte 04
SBCMU软件版本第04字节";
CM_ SG_ 2564947890 SBCMU02_SW05 "SBCMU Software Byte 05
SBCMU软件版本第05字节";
CM_ SG_ 2564947890 SBCMU02_SW06 "SBCMU Software Byte 06
SBCMU软件版本第06字节";
CM_ SG_ 2564947890 SBCMU02_SW07 "SBCMU Software Byte 07
SBCMU软件版本第07字节";
CM_ BO_ 2565013426 "SBCMU Tx and Hardware";
CM_ SG_ 2565013426 SBCMU02_HW01 "SBCMU Hardware Byte 01
SBCMU硬件版本第01字节";
CM_ SG_ 2565013426 SBCMU02_HW02 "SBCMU Hardware Byte 02
SBCMU硬件版本第02字节";
CM_ SG_ 2565013426 SBCMU02_HW03 "SBCMU Hardware Byte 03
SBCMU硬件版本第03字节";
CM_ SG_ 2565013426 SBCMU02_HW04 "SBCMU Hardware Byte 04
SBCMU硬件版本第04字节";
CM_ SG_ 2565013426 SBCMU02_HW05 "SBCMU Hardware Byte 05
SBCMU硬件版本第05字节";
CM_ SG_ 2565013426 SBCMU02_HW06 "SBCMU Hardware Byte 06
SBCMU硬件版本第06字节";
CM_ SG_ 2565013426 SBCMU02_HW07 "SBCMU Hardware Byte 07
SBCMU硬件版本第07字节";
CM_ BO_ 2562260915 "SBCMU Tx and WarningInfo";
CM_ SG_ 2562260915 SBCMU03_ErrTab "Error Table
故障码";
CM_ SG_ 2562260915 SBCMU03_FaultSum "Fault Sum
故障总数";
CM_ SG_ 2562260915 SBCMU03_BattVolt_HighWarning "总压过压(过充)";
CM_ SG_ 2562260915 SBCMU03_SumVolt_HighWarning "电池包累加总压过压";
CM_ SG_ 2562260915 SBCMU03_CellVolt_HighWarning "单体过压(过充)";
CM_ SG_ 2562260915 SBCMU03_Temp_HighWarning "单体过高温报警";
CM_ SG_ 2562260915 SBCMU03_AmbientTemp_HighWarning "环境过高温报警";
CM_ SG_ 2562260915 SBCMU03_SysFailSta "System Failure Status
SBCMU失效状态";
CM_ SG_ 2562260915 SBCMU03_SBICU_TimeOut "SBICU通讯丢失";
CM_ SG_ 2562260915 SBCMU03_CellTempOpen "单体温度采样断线";
CM_ SG_ 2562260915 SBCMU03_SupplyVolt_HighWarning "供电电压过高";
CM_ SG_ 2562260915 SBCMU03_SupplyVolt_LowWarning "供电电压过低";
CM_ BO_ 2562391987 "SBCMU Tx and Run State";
CM_ SG_ 2562391987 SBCMU03_Address "SBCMU_Address有效地址";
CM_ SG_ 2562391987 SBCMU03_SBICUnum "SBICUnum
配置电池包安全功能从控管理单元总数";
CM_ SG_ 2562391987 SBCMU03_WorkState "Work State
工作状态";
CM_ SG_ 2562391987 SBCMU03_Contactor_state_Safty "安全继电器状态";
CM_ SG_ 2562391987 SBCMU03_SoftVer "SoftVer
软件版本";
CM_ SG_ 2562391987 SBCMU03_HardVer "HardVer
硬件版本";
CM_ SG_ 2562391987 SBCMU03_AliveCounter "Alive Counter";
CM_ BO_ 2560819123 "SBCMU Tx and DC Charge Related";
CM_ SG_ 2560819123 SBCMU03_Electronic_Lock_State "Electronic Lock State
电子锁开关状态";
CM_ SG_ 2560819123 SBCMU03_DCS_InletConnectSta "DC Inlet Connect Status
直流枪插抢连接状态";
CM_ SG_ 2560819123 SBCMU03_DCS_ChrgAPlus "DC Charge A+
充电桩A+辅助信号";
CM_ SG_ 2560819123 SBCMU03_DCChrg_Stage "直流充电阶段";
CM_ SG_ 2560819123 SBCMU03_Contactor_state_DC "直流充电继电器状态";
CM_ SG_ 2560819123 SBCMU03_DCChrg_ISO_Enable "直流充电允许绝缘检测";
CM_ SG_ 2560819123 SBCMU03_SocketTemp_HighWarning "充电插座过温";
CM_ SG_ 2560819123 SBCMU03_DCChrg_Step "直流充电步骤";
CM_ SG_ 2560819123 SBCMU03_TempMax_ChargeSocket_Pos "DC Charge socket positive temperature
直流充电座正极温度";
CM_ SG_ 2560819123 SBCMU03_TempMax_ChargeSocket_Neg "DC Charge socket negative temperature
直流充电座负极温度";
CM_ BO_ 2564947891 "SBCMU Tx and Software";
CM_ SG_ 2564947891 SBCMU03_SW01 "SBCMU Software Byte 01
SBCMU软件版本第01字节";
CM_ SG_ 2564947891 SBCMU03_SW02 "SBCMU Software Byte 02
SBCMU软件版本第02字节";
CM_ SG_ 2564947891 SBCMU03_SW03 "SBCMU Software Byte 03
SBCMU软件版本第03字节";
CM_ SG_ 2564947891 SBCMU03_SW04 "SBCMU Software Byte 04
SBCMU软件版本第04字节";
CM_ SG_ 2564947891 SBCMU03_SW05 "SBCMU Software Byte 05
SBCMU软件版本第05字节";
CM_ SG_ 2564947891 SBCMU03_SW06 "SBCMU Software Byte 06
SBCMU软件版本第06字节";
CM_ SG_ 2564947891 SBCMU03_SW07 "SBCMU Software Byte 07
SBCMU软件版本第07字节";
CM_ BO_ 2565013427 "SBCMU Tx and Hardware";
CM_ SG_ 2565013427 SBCMU03_HW01 "SBCMU Hardware Byte 01
SBCMU硬件版本第01字节";
CM_ SG_ 2565013427 SBCMU03_HW02 "SBCMU Hardware Byte 02
SBCMU硬件版本第02字节";
CM_ SG_ 2565013427 SBCMU03_HW03 "SBCMU Hardware Byte 03
SBCMU硬件版本第03字节";
CM_ SG_ 2565013427 SBCMU03_HW04 "SBCMU Hardware Byte 04
SBCMU硬件版本第04字节";
CM_ SG_ 2565013427 SBCMU03_HW05 "SBCMU Hardware Byte 05
SBCMU硬件版本第05字节";
CM_ SG_ 2565013427 SBCMU03_HW06 "SBCMU Hardware Byte 06
SBCMU硬件版本第06字节";
CM_ SG_ 2565013427 SBCMU03_HW07 "SBCMU Hardware Byte 07
SBCMU硬件版本第07字节";
CM_ BO_ 2562260916 "SBCMU Tx and WarningInfo";
CM_ SG_ 2562260916 SBCMU04_ErrTab "Error Table
故障码";
CM_ SG_ 2562260916 SBCMU04_FaultSum "Fault Sum
故障总数";
CM_ SG_ 2562260916 SBCMU04_BattVolt_HighWarning "总压过压(过充)";
CM_ SG_ 2562260916 SBCMU04_SumVolt_HighWarning "电池包累加总压过压";
CM_ SG_ 2562260916 SBCMU04_CellVolt_HighWarning "单体过压(过充)";
CM_ SG_ 2562260916 SBCMU04_Temp_HighWarning "单体过高温报警";
CM_ SG_ 2562260916 SBCMU04_AmbientTemp_HighWarning "环境过高温报警";
CM_ SG_ 2562260916 SBCMU04_SysFailSta "System Failure Status
SBCMU失效状态";
CM_ SG_ 2562260916 SBCMU04_SBICU_TimeOut "SBICU通讯丢失";
CM_ SG_ 2562260916 SBCMU04_CellTempOpen "单体温度采样断线";
CM_ SG_ 2562260916 SBCMU04_SupplyVolt_HighWarning "供电电压过高";
CM_ SG_ 2562260916 SBCMU04_SupplyVolt_LowWarning "供电电压过低";
CM_ BO_ 2562391988 "SBCMU Tx and Run State";
CM_ SG_ 2562391988 SBCMU04_Address "SBCMU_Address有效地址";
CM_ SG_ 2562391988 SBCMU04_SBICUnum "SBICUnum
配置电池包安全功能从控管理单元总数";
CM_ SG_ 2562391988 SBCMU04_WorkState "Work State
工作状态";
CM_ SG_ 2562391988 SBCMU04_Contactor_state_Safty "安全继电器状态";
CM_ SG_ 2562391988 SBCMU04_SoftVer "SoftVer
软件版本";
CM_ SG_ 2562391988 SBCMU04_HardVer "HardVer
硬件版本";
CM_ SG_ 2562391988 SBCMU04_AliveCounter "Alive Counter";
CM_ BO_ 2560819124 "SBCMU Tx and DC Charge Related";
CM_ SG_ 2560819124 SBCMU04_Electronic_Lock_State "Electronic Lock State
电子锁开关状态";
CM_ SG_ 2560819124 SBCMU04_DCS_InletConnectSta "DC Inlet Connect Status
直流枪插抢连接状态";
CM_ SG_ 2560819124 SBCMU04_DCS_ChrgAPlus "DC Charge A+
充电桩A+辅助信号";
CM_ SG_ 2560819124 SBCMU04_DCChrg_Stage "直流充电阶段";
CM_ SG_ 2560819124 SBCMU04_Contactor_state_DC "直流充电继电器状态";
CM_ SG_ 2560819124 SBCMU04_DCChrg_ISO_Enable "直流充电允许绝缘检测";
CM_ SG_ 2560819124 SBCMU04_SocketTemp_HighWarning "充电插座过温";
CM_ SG_ 2560819124 SBCMU04_DCChrg_Step "直流充电步骤";
CM_ SG_ 2560819124 SBCMU04_TempMax_ChargeSocket_Pos "DC Charge socket positive temperature
直流充电座正极温度";
CM_ SG_ 2560819124 SBCMU04_TempMax_ChargeSocket_Neg "DC Charge socket negative temperature
直流充电座负极温度";
CM_ BO_ 2564947892 "SBCMU Tx and Software";
CM_ SG_ 2564947892 SBCMU04_SW01 "SBCMU Software Byte 01
SBCMU软件版本第01字节";
CM_ SG_ 2564947892 SBCMU04_SW02 "SBCMU Software Byte 02
SBCMU软件版本第02字节";
CM_ SG_ 2564947892 SBCMU04_SW03 "SBCMU Software Byte 03
SBCMU软件版本第03字节";
CM_ SG_ 2564947892 SBCMU04_SW04 "SBCMU Software Byte 04
SBCMU软件版本第04字节";
CM_ SG_ 2564947892 SBCMU04_SW05 "SBCMU Software Byte 05
SBCMU软件版本第05字节";
CM_ SG_ 2564947892 SBCMU04_SW06 "SBCMU Software Byte 06
SBCMU软件版本第06字节";
CM_ SG_ 2564947892 SBCMU04_SW07 "SBCMU Software Byte 07
SBCMU软件版本第07字节";
CM_ BO_ 2565013428 "SBCMU Tx and Hardware";
CM_ SG_ 2565013428 SBCMU04_HW01 "SBCMU Hardware Byte 01
SBCMU硬件版本第01字节";
CM_ SG_ 2565013428 SBCMU04_HW02 "SBCMU Hardware Byte 02
SBCMU硬件版本第02字节";
CM_ SG_ 2565013428 SBCMU04_HW03 "SBCMU Hardware Byte 03
SBCMU硬件版本第03字节";
CM_ SG_ 2565013428 SBCMU04_HW04 "SBCMU Hardware Byte 04
SBCMU硬件版本第04字节";
CM_ SG_ 2565013428 SBCMU04_HW05 "SBCMU Hardware Byte 05
SBCMU硬件版本第05字节";
CM_ SG_ 2565013428 SBCMU04_HW06 "SBCMU Hardware Byte 06
SBCMU硬件版本第06字节";
CM_ SG_ 2565013428 SBCMU04_HW07 "SBCMU Hardware Byte 07
SBCMU硬件版本第07字节";
CM_ BO_ 2562260917 "SBCMU Tx and WarningInfo";
CM_ SG_ 2562260917 SBCMU05_ErrTab "Error Table
故障码";
CM_ SG_ 2562260917 SBCMU05_FaultSum "Fault Sum
故障总数";
CM_ SG_ 2562260917 SBCMU05_BattVolt_HighWarning "总压过压(过充)";
CM_ SG_ 2562260917 SBCMU05_SumVolt_HighWarning "电池包累加总压过压";
CM_ SG_ 2562260917 SBCMU05_CellVolt_HighWarning "单体过压(过充)";
CM_ SG_ 2562260917 SBCMU05_Temp_HighWarning "单体过高温报警";
CM_ SG_ 2562260917 SBCMU05_AmbientTemp_HighWarning "环境过高温报警";
CM_ SG_ 2562260917 SBCMU05_SysFailSta "System Failure Status
SBCMU失效状态";
CM_ SG_ 2562260917 SBCMU05_SBICU_TimeOut "SBICU通讯丢失";
CM_ SG_ 2562260917 SBCMU05_CellTempOpen "单体温度采样断线";
CM_ SG_ 2562260917 SBCMU05_SupplyVolt_HighWarning "供电电压过高";
CM_ SG_ 2562260917 SBCMU05_SupplyVolt_LowWarning "供电电压过低";
CM_ BO_ 2562391989 "SBCMU Tx and Run State";
CM_ SG_ 2562391989 SBCMU05_Address "SBCMU_Address有效地址";
CM_ SG_ 2562391989 SBCMU05_SBICUnum "SBICUnum
配置电池包安全功能从控管理单元总数";
CM_ SG_ 2562391989 SBCMU05_WorkState "Work State
工作状态";
CM_ SG_ 2562391989 SBCMU05_Contactor_state_Safty "安全继电器状态";
CM_ SG_ 2562391989 SBCMU05_SoftVer "SoftVer
软件版本";
CM_ SG_ 2562391989 SBCMU05_HardVer "HardVer
硬件版本";
CM_ SG_ 2562391989 SBCMU05_AliveCounter "Alive Counter";
CM_ BO_ 2560819125 "SBCMU Tx and DC Charge Related";
CM_ SG_ 2560819125 SBCMU05_Electronic_Lock_State "Electronic Lock State
电子锁开关状态";
CM_ SG_ 2560819125 SBCMU05_DCS_InletConnectSta "DC Inlet Connect Status
直流枪插抢连接状态";
CM_ SG_ 2560819125 SBCMU05_DCS_ChrgAPlus "DC Charge A+
充电桩A+辅助信号";
CM_ SG_ 2560819125 SBCMU05_DCChrg_Stage "直流充电阶段";
CM_ SG_ 2560819125 SBCMU05_Contactor_state_DC "直流充电继电器状态";
CM_ SG_ 2560819125 SBCMU05_DCChrg_ISO_Enable "直流充电允许绝缘检测";
CM_ SG_ 2560819125 SBCMU05_SocketTemp_HighWarning "充电插座过温";
CM_ SG_ 2560819125 SBCMU05_DCChrg_Step "直流充电步骤";
CM_ SG_ 2560819125 SBCMU05_TempMax_ChargeSocket_Pos "DC Charge socket positive temperature
直流充电座正极温度";
CM_ SG_ 2560819125 SBCMU05_TempMax_ChargeSocket_Neg "DC Charge socket negative temperature
直流充电座负极温度";
CM_ BO_ 2564947893 "SBCMU Tx and Software";
CM_ SG_ 2564947893 SBCMU05_SW01 "SBCMU Software Byte 01
SBCMU软件版本第01字节";
CM_ SG_ 2564947893 SBCMU05_SW02 "SBCMU Software Byte 02
SBCMU软件版本第02字节";
CM_ SG_ 2564947893 SBCMU05_SW03 "SBCMU Software Byte 03
SBCMU软件版本第03字节";
CM_ SG_ 2564947893 SBCMU05_SW04 "SBCMU Software Byte 04
SBCMU软件版本第04字节";
CM_ SG_ 2564947893 SBCMU05_SW05 "SBCMU Software Byte 05
SBCMU软件版本第05字节";
CM_ SG_ 2564947893 SBCMU05_SW06 "SBCMU Software Byte 06
SBCMU软件版本第06字节";
CM_ SG_ 2564947893 SBCMU05_SW07 "SBCMU Software Byte 07
SBCMU软件版本第07字节";
CM_ BO_ 2565013429 "SBCMU Tx and Hardware";
CM_ SG_ 2565013429 SBCMU05_HW01 "SBCMU Hardware Byte 01
SBCMU硬件版本第01字节";
CM_ SG_ 2565013429 SBCMU05_HW02 "SBCMU Hardware Byte 02
SBCMU硬件版本第02字节";
CM_ SG_ 2565013429 SBCMU05_HW03 "SBCMU Hardware Byte 03
SBCMU硬件版本第03字节";
CM_ SG_ 2565013429 SBCMU05_HW04 "SBCMU Hardware Byte 04
SBCMU硬件版本第04字节";
CM_ SG_ 2565013429 SBCMU05_HW05 "SBCMU Hardware Byte 05
SBCMU硬件版本第05字节";
CM_ SG_ 2565013429 SBCMU05_HW06 "SBCMU Hardware Byte 06
SBCMU硬件版本第06字节";
CM_ SG_ 2565013429 SBCMU05_HW07 "SBCMU Hardware Byte 07
SBCMU硬件版本第07字节";
CM_ BO_ 2564030431 "DAPP Tx and BalControl";
CM_ SG_ 2564030431 NBICU_Cell0108BalaCmd "Cell0108BalaCmd
单体1至8通道均衡指令";
CM_ SG_ 2564030431 NBICU_Cell0916BalaCmd "Cell0916BalaCmd
单体9至16通道均衡指令";
CM_ SG_ 2564030431 NBICU_Cell1724BalaCmd "Cell1724BalaCmd
单体17至24通道均衡指令";
CM_ SG_ 2564030431 NBICU_Cell2532BalaCmd "Cell2532BalaCmd
单体25至32通道均衡指令";
CM_ SG_ 2564030431 NBICU_Cell3336BalaCmd "Cell3336BalaCmd
单体33至36通道均衡指令";
CM_ SG_ 2564030431 NBICU_CellBalaCmd_Mode "CellBalaCmd_Mode
单体强制均衡指令模式";
CM_ SG_ 2564030431 NBICU_CellBala_StartVoltDiff "CellBala_StartVoltDiff
单体均衡开启压差";
CM_ BO_ 2564489183 "DAPP Tx and AddressSET";
CM_ SG_ 2564489183 DAPP_NBCMU_AddConfigCmd "NBCMU AddConfigCmd
NBCMU地址编码指令";
CM_ SG_ 2564489183 DAPP_SBCMU_AddConfigCmd "SBCMU AddConfigCmd
SBCMU地址编码指令";
CM_ SG_ 2564489183 DAPP_NBICU_AddConfigCmd "NBICU AddConfigCmd
NBICU地址编码指令";
CM_ SG_ 2564489183 DAPP_SBICU_AddConfigCmd "SBICU AddConfigCmd
SBICU地址编码指令";
CM_ BO_ 2564554719 "DAPP Tx and ParaSet";
CM_ SG_ 2564554719 DAPP_Addr_Target "DAPP Addr Target
目标地址(FF为广播)";
CM_ SG_ 2564554719 DAPP_Set_SOCActl "DAPP Set SOC Actl Value
设置真实SOC值";
CM_ SG_ 2564554719 DAPP_Set_SOCDis "DAPP Set SOC Display Value
设置显示SOC值";
CM_ SG_ 2564554719 DAPP_Set_AccChrgCapa "DAPP Set Acc Charge Capacity Value
设置累计充电容量";
CM_ SG_ 2564554719 DAPP_Set_NewAddr "DAPP Set New Addr
设置新地址";
CM_ SG_ 2564554719 DAPP_Set_SOCActlValid "DAPP Set SOC Actl Valid
设置真实SOC值有效性";
CM_ SG_ 2564554719 DAPP_Set_SOCDisValid "DAPP Set SOC Display Valid
设置显示SOC值有效性";
CM_ SG_ 2564554719 DAPP_Set_AccChrgCapaValid "DAPP Set Acc Charge Capacity Valid
设置累计充电容量有效性";
CM_ SG_ 2564554719 DAPP_Set_NewAddrValid "DAPP Set New Addr Valid
设置新地址有效性";
CM_ SG_ 2564554719 DAPP_Set_InsDetect_Forbid "DAPP Insulation Detect_Forbid
设置禁止绝缘检测";
CM_ BO_ 2563899359 "DAPP Tx and FaultSet";
CM_ SG_ 2563899359 DAPP_Fault_Addr_Target "DAPP Fault Addr Target
故障设置目标地址(FF为广播)";
CM_ SG_ 2563899359 DAPP_ErrCode "DAPP Error Code
需要设置的故障码";
CM_ SG_ 2563899359 DAPP_Set_Fault "DAPP Set Fault
设置故障";
CM_ SG_ 2563899359 DAPP_FaultDetect_Mode "DAPP Fault Detect Mode
故障检测模式";
CM_ BO_ 2563964895 "DAPP Tx and ThresholdSet";
CM_ SG_ 2563964895 DAPP_Threshold_Addr_Target "DAPP Fault Addr Target
阈值设置目标地址(FF为广播)";
CM_ SG_ 2563964895 DAPP_Threshold_PID "DAPP Threshold PID
需要设置的阈值PID";
CM_ SG_ 2563964895 DAPP_Threshold_Number "DAPP Threshold Number
设置阈值序号(1-5)";
CM_ SG_ 2563964895 DAPP_Threshold_Mode "DAPP Threshold Mode
设置阈值模式";
CM_ SG_ 2563964895 DAPP_Threshold_Data1 "DAPP Threshold Data
待设置的阈值Byte(number-1)*4＋1";
CM_ SG_ 2563964895 DAPP_Threshold_Data2 "DAPP Threshold Data
待设置的阈值Byte(number-1)*4＋2";
CM_ SG_ 2563964895 DAPP_Threshold_Data3 "DAPP Threshold Data
待设置的阈值Byte(number-1)*4＋3";
CM_ SG_ 2563964895 DAPP_Threshold_Data4 "DAPP Threshold Data
待设置的阈值Byte(number-1)*4＋4";
CM_ BO_ 2564751327 "DAPP Tx and VIN_Write";
CM_ SG_ 2564751327 DAPP_VIN01 "VIN Byte 01
VIN第01个字节";
CM_ SG_ 2564751327 DAPP_VIN02 "VIN Byte 02
VIN第02个字节";
CM_ SG_ 2564751327 DAPP_VIN03 "VIN Byte 03
VIN第03个字节";
CM_ SG_ 2564751327 DAPP_VIN04 "VIN Byte 04
VIN第04个字节";
CM_ SG_ 2564751327 DAPP_VIN05 "VIN Byte 05
VIN第05个字节";
CM_ SG_ 2564751327 DAPP_VIN06 "VIN Byte 06
VIN第06个字节";
CM_ SG_ 2564751327 DAPP_VIN07 "VIN Byte 07
VIN第07个字节";
CM_ SG_ 2564751327 DAPP_VIN08 "VIN Byte 08
VIN第08个字节";
CM_ BO_ 2564685791 "DAPP Tx and DiagRequest";
BA_DEF_ SG_  "GenSigSendType" ENUM  "Cycle","OnChangeWithRepetition","OnChange","OnWriteWithRepetition","OnWrite","IfActiveWithRepetition","IfActive";
BA_DEF_ BO_  "GenMsgSendType" ENUM  "Cycle","Event","CycleEvent","IfActive";
BA_DEF_ BO_  "GenMsgCycleTime" INT 0 65536;
BA_DEF_ SG_  "SystemSignalLongSymbol" STRING ;
BA_DEF_DEF_  "GenSigSendType" "Cycle";
BA_DEF_DEF_  "GenMsgSendType" "Cycle";
BA_DEF_DEF_  "GenMsgCycleTime" 0;
BA_DEF_DEF_  "SystemSignalLongSymbol" "";
BA_ "GenMsgCycleTime" BO_ 2561802145 100;
BA_ "GenMsgCycleTime" BO_ 2562457505 100;
BA_ "GenMsgCycleTime" BO_ 2561867681 100;
BA_ "GenMsgCycleTime" BO_ 2561933217 500;
BA_ "GenMsgCycleTime" BO_ 2561998753 500;
BA_ "GenMsgCycleTime" BO_ 2562064289 100;
BA_ "GenMsgCycleTime" BO_ 2562195361 100;
BA_ "GenMsgCycleTime" BO_ 2560884641 100;
BA_ "GenMsgCycleTime" BO_ 2561605537 5000;
BA_ "GenMsgCycleTime" BO_ 2564947873 5000;
BA_ "GenMsgCycleTime" BO_ 2565013409 5000;
BA_ "GenMsgCycleTime" BO_ 2561736610 100;
BA_ "GenMsgCycleTime" BO_ 2561802146 100;
BA_ "GenMsgCycleTime" BO_ 2562457506 100;
BA_ "GenMsgCycleTime" BO_ 2561867682 100;
BA_ "GenMsgCycleTime" BO_ 2561933218 500;
BA_ "GenMsgCycleTime" BO_ 2561998754 500;
BA_ "GenMsgCycleTime" BO_ 2562064290 100;
BA_ "GenMsgCycleTime" BO_ 2562195362 100;
BA_ "GenMsgCycleTime" BO_ 2560884642 100;
BA_ "GenMsgCycleTime" BO_ 2561605538 5000;
BA_ "GenMsgCycleTime" BO_ 2564947874 5000;
BA_ "GenMsgCycleTime" BO_ 2565013410 5000;
BA_ "GenMsgCycleTime" BO_ 2561736611 100;
BA_ "GenMsgCycleTime" BO_ 2561802147 100;
BA_ "GenMsgCycleTime" BO_ 2562457507 100;
BA_ "GenMsgCycleTime" BO_ 2561867683 100;
BA_ "GenMsgCycleTime" BO_ 2561933219 500;
BA_ "GenMsgCycleTime" BO_ 2561998755 500;
BA_ "GenMsgCycleTime" BO_ 2562064291 100;
BA_ "GenMsgCycleTime" BO_ 2562195363 100;
BA_ "GenMsgCycleTime" BO_ 2560884643 100;
BA_ "GenMsgCycleTime" BO_ 2561605539 5000;
BA_ "GenMsgCycleTime" BO_ 2564947875 5000;
BA_ "GenMsgCycleTime" BO_ 2565013411 5000;
BA_ "GenMsgCycleTime" BO_ 2561736612 100;
BA_ "GenMsgCycleTime" BO_ 2561802148 100;
BA_ "GenMsgCycleTime" BO_ 2562457508 100;
BA_ "GenMsgCycleTime" BO_ 2561867684 100;
BA_ "GenMsgCycleTime" BO_ 2561933220 500;
BA_ "GenMsgCycleTime" BO_ 2561998756 500;
BA_ "GenMsgCycleTime" BO_ 2562064292 100;
BA_ "GenMsgCycleTime" BO_ 2562195364 100;
BA_ "GenMsgCycleTime" BO_ 2560884644 100;
BA_ "GenMsgCycleTime" BO_ 2561605540 5000;
BA_ "GenMsgCycleTime" BO_ 2564947876 5000;
BA_ "GenMsgCycleTime" BO_ 2565013412 5000;
BA_ "GenMsgCycleTime" BO_ 2561736613 100;
BA_ "GenMsgCycleTime" BO_ 2561802149 100;
BA_ "GenMsgCycleTime" BO_ 2562457509 100;
BA_ "GenMsgCycleTime" BO_ 2561867685 100;
BA_ "GenMsgCycleTime" BO_ 2561933221 500;
BA_ "GenMsgCycleTime" BO_ 2561998757 500;
BA_ "GenMsgCycleTime" BO_ 2562064293 100;
BA_ "GenMsgCycleTime" BO_ 2562195365 100;
BA_ "GenMsgCycleTime" BO_ 2560884645 100;
BA_ "GenMsgCycleTime" BO_ 2561605541 5000;
BA_ "GenMsgCycleTime" BO_ 2564947877 5000;
BA_ "GenMsgCycleTime" BO_ 2565013413 5000;
BA_ "GenMsgCycleTime" BO_ 2562326448 200;
BA_ "GenMsgCycleTime" BO_ 2562260913 100;
BA_ "GenMsgCycleTime" BO_ 2562391985 100;
BA_ "GenMsgCycleTime" BO_ 2560819121 100;
BA_ "GenMsgCycleTime" BO_ 2564947889 5000;
BA_ "GenMsgCycleTime" BO_ 2565013425 5000;
BA_ "GenMsgCycleTime" BO_ 2562260914 100;
BA_ "GenMsgCycleTime" BO_ 2562391986 100;
BA_ "GenMsgCycleTime" BO_ 2560819122 100;
BA_ "GenMsgCycleTime" BO_ 2564947890 5000;
BA_ "GenMsgCycleTime" BO_ 2565013426 5000;
BA_ "GenMsgCycleTime" BO_ 2562260915 100;
BA_ "GenMsgCycleTime" BO_ 2562391987 100;
BA_ "GenMsgCycleTime" BO_ 2560819123 100;
BA_ "GenMsgCycleTime" BO_ 2564947891 5000;
BA_ "GenMsgCycleTime" BO_ 2565013427 5000;
BA_ "GenMsgCycleTime" BO_ 2562260916 100;
BA_ "GenMsgCycleTime" BO_ 2562391988 100;
BA_ "GenMsgCycleTime" BO_ 2560819124 100;
BA_ "GenMsgCycleTime" BO_ 2564947892 5000;
BA_ "GenMsgCycleTime" BO_ 2565013428 5000;
BA_ "GenMsgCycleTime" BO_ 2562260917 100;
BA_ "GenMsgCycleTime" BO_ 2562391989 100;
BA_ "GenMsgCycleTime" BO_ 2560819125 100;
BA_ "GenMsgCycleTime" BO_ 2564947893 5000;
BA_ "GenMsgCycleTime" BO_ 2565013429 5000;
BA_ "GenMsgSendType" BO_ 2564030431 1;
BA_ "GenMsgSendType" BO_ 2564489183 1;
BA_ "GenMsgSendType" BO_ 2564554719 1;
BA_ "GenMsgSendType" BO_ 2563899359 1;
BA_ "GenMsgSendType" BO_ 2563964895 1;
BA_ "GenMsgSendType" BO_ 2564751327 1;
BA_ "GenMsgSendType" BO_ 2564685791 1;
BA_ "SystemSignalLongSymbol" SG_ 2560819121 SBCMU01_TempMax_ChargeSocket_Pos "SBCMU01_TempMax_ChargeSocket_Posi";
BA_ "SystemSignalLongSymbol" SG_ 2560819121 SBCMU01_TempMax_ChargeSocket_Neg "SBCMU01_TempMax_ChargeSocket_Nega";
BA_ "SystemSignalLongSymbol" SG_ 2560819122 SBCMU02_TempMax_ChargeSocket_Pos "SBCMU02_TempMax_ChargeSocket_Posi";
BA_ "SystemSignalLongSymbol" SG_ 2560819122 SBCMU02_TempMax_ChargeSocket_Neg "SBCMU02_TempMax_ChargeSocket_Nega";
BA_ "SystemSignalLongSymbol" SG_ 2560819123 SBCMU03_TempMax_ChargeSocket_Pos "SBCMU03_TempMax_ChargeSocket_Posi";
BA_ "SystemSignalLongSymbol" SG_ 2560819123 SBCMU03_TempMax_ChargeSocket_Neg "SBCMU03_TempMax_ChargeSocket_Nega";
BA_ "SystemSignalLongSymbol" SG_ 2560819124 SBCMU04_TempMax_ChargeSocket_Pos "SBCMU04_TempMax_ChargeSocket_Posi";
BA_ "SystemSignalLongSymbol" SG_ 2560819124 SBCMU04_TempMax_ChargeSocket_Neg "SBCMU04_TempMax_ChargeSocket_Nega";
BA_ "SystemSignalLongSymbol" SG_ 2560819125 SBCMU05_TempMax_ChargeSocket_Pos "SBCMU05_TempMax_ChargeSocket_Posi";
BA_ "SystemSignalLongSymbol" SG_ 2560819125 SBCMU05_TempMax_ChargeSocket_Neg "SBCMU05_TempMax_ChargeSocket_Nega";
VAL_ 2561802145 NBCMU01_SysFailSta 0 " No Error " 1 " Level_Error " 2 " Leve2_Error " 3 " Leve3_Error " ;
VAL_ 2561802145 NBCMU01_InsRes_polarity 0 " InsResP equal InsResN " 1 " InsResP Lesser " 2 " InsResN Lesser " 3 " Reserved " ;
VAL_ 2561802145 NBCMU01_BattVolt_HighWarning 0 " Normal " 1 " Level 1 Warning " 2 " Level 2 Warning " 3 " Level 3 Warning " ;
VAL_ 2561802145 NBCMU01_BattVolt_LowWarning 0 " Normal " 1 " Level 1 Warning " 2 " Level 2 Warning " 3 " Level 3 Warning " ;
VAL_ 2561802145 NBCMU01_CellVolt_HighWarning 0 " Normal " 1 " Level 1 Warning " 2 " Level 2 Warning " 3 " Level 3 Warning " ;
VAL_ 2561802145 NBCMU01_CellVolt_LowWarning 0 " Normal " 1 " Level 1 Warning " 2 " Level 2 Warning " 3 " Level 3 Warning " ;
VAL_ 2561802145 NBCMU01_ChrgTemp_HighWarning 0 " Normal " 1 " Level 1 Warning " 2 " Level 2 Warning " 3 " Level 3 Warning " ;
VAL_ 2561802145 NBCMU01_ChrgTemp_LowWarning 0 " Normal " 1 " Level 1 Warning " 2 " Level 2 Warning " 3 " Level 3 Warning " ;
VAL_ 2561802145 NBCMU01_DischrgTemp_HighWarning 0 " Normal " 1 " Level 1 Warning " 2 " Level 2 Warning " 3 " Level 3 Warning " ;
VAL_ 2561802145 NBCMU01_DischrgTemp_LowWarning 0 " Normal " 1 " Level 1 Warning " 2 " Level 2 Warning " 3 " Level 3 Warning " ;
VAL_ 2561802145 NBCMU01_TempDiff_Warning 0 " Normal " 1 " Level 1 Warning " 2 " Level 2 Warning " 3 " Level 3 Warning " ;
VAL_ 2561802145 NBCMU01_CellVoltDiff_Warning 0 " Normal " 1 " Level 1 Warning " 2 " Level 2 Warning " 3 " Level 3 Warning " ;
VAL_ 2561802145 NBCMU01_DischrgCurr_OverWarning 0 " Normal " 1 " Level 1 Warning " 2 " Level 2 Warning " 3 " Level 3 Warning " ;
VAL_ 2561802145 NBCMU01_ChrgCurr_OverWarning 0 " Normal " 1 " Level 1 Warning " 2 " Level 2 Warning " 3 " Level 3 Warning " ;
VAL_ 2561802145 NBCMU01_InsulationWarning 0 " Normal " 1 " Level 1 Warning " 2 " Level 2 Warning " 3 " Level 3 Warning " ;
VAL_ 2561802145 NBCMU01_SOC_LowWarning 0 " Normal " 1 " Level 1 Warning " 2 " Level 2 Warning " 3 " Level 3 Warning " ;
VAL_ 2561802145 NBCMU01_AmbientTemp_HighWarning 0 " Normal " 1 " Level 1 Warning " 2 " Level 2 Warning " 3 " Level 3 Warning " ;
VAL_ 2561802145 NBCMU01_AmbientTemp_LowWarning 0 " Normal " 1 " Level 1 Warning " 2 " Level 2 Warning " 3 " Level 3 Warning " ;
VAL_ 2561802145 NBCMU01_ContactorPosi_Fault 0 " Normal " 1 " can not close " 2 " can not open " 3 " reserved " ;
VAL_ 2561802145 NBCMU01_ContactorNega_Fault 0 " Normal " 1 " can not close " 2 " can not open " 3 " reserved " ;
VAL_ 2561802145 NBCMU01_ContactorBalan_Fault 0 " Normal " 1 " can not close " 2 " can not open " 3 " reserved " ;
VAL_ 2561802145 NBCMU01_ContactorHeat_Fault 0 " Normal " 1 " can not close " 2 " can not open " 3 " reserved " ;
VAL_ 2561802145 NBCMU01_CurrSensor_TimeOut 0 " Normal " 1 " TimeOut " ;
VAL_ 2561802145 NBCMU01_SOH_LowWarning 0 " Normal " 1 " Level 1 Warning " 2 " Level 2 Warning " 3 " Level 3 Warning " ;
VAL_ 2561802145 NBCMU01_HVIL_Fault 0 " Normal " 1 " Fault " ;
VAL_ 2561802145 NBCMU01_Fuse_Fault 0 " Normal " 1 " Fault " ;
VAL_ 2562457505 NBCMU01_NBICU_TimeOut 0 " Normal " 1 " TimeOut " ;
VAL_ 2562457505 NBCMU01_PrechrgFault 0 " Normal " 1 " Fault " ;
VAL_ 2562457505 NBCMU01_SupplyVolt_HighWarning 0 " Normal " 1 " Level 1 Warning " 2 " Level 2 Warning " 3 " Level 3 Warning " ;
VAL_ 2562457505 NBCMU01_SupplyVolt_LowWarning 0 " Normal " 1 " Level 1 Warning " 2 " Level 2 Warning " 3 " Level 3 Warning " ;
VAL_ 2562457505 NBCMU01_CellVoltOpen 0 " Normal " 1 " Fault " ;
VAL_ 2562457505 NBCMU01_CellTempOpen 0 " Normal " 1 " Fault " ;
VAL_ 2560884641 NBCMU01_SumVolt_HighWarning 0 " Normal " 1 " Level 1 Warning " 2 " Level 2 Warning " 3 " Level 3 Warning " ;
VAL_ 2560884641 NBCMU01_SumVolt_LowWarning 0 " Normal " 1 " Level 1 Warning " 2 " Level 2 Warning " 3 " Level 3 Warning " ;
VAL_ 2560884641 NBCMU01_CurrentLoop_HighWarning 0 " Normal " 1 " Fault " ;
VAL_ 2560884641 NBCMU01_ProtectFault 0 " Normal " 1 " Fault " ;
VAL_ 2560884641 NBCMU01_RunLed_State 0 " open " 1 " close " ;
VAL_ 2560884641 NBCMU01_Buzz_State 0 " Off " 1 " On " ;
VAL_ 2560884641 NBCMU01_Heating_State 0 " turn off " 1 " turn on " ;
VAL_ 2560884641 NBCMU01_Cooling_State 0 " turn off " 1 " turn on " ;
VAL_ 2560884641 NBCMU01_BattVoltDiff_Warning 0 " Normal " 1 " Fault " ;
VAL_ 2560884641 NBCMU01_EmergyShutdown_Fault 0 " Normal " 1 " Fault " ;
VAL_ 2560884641 NBCMU01_PCS_TimeOut 0 " Normal " 1 " TimeOut " ;
VAL_ 2560884641 NBCMU01_EMS_TimeOut 0 " Normal " 1 " TimeOut " ;
VAL_ 2560884641 NBCMU01_TMS_TimeOut 0 " Normal " 1 " TimeOut " ;
VAL_ 2560884641 NBCMU01_SBCMU01_TimeOut 0 " Normal " 1 " TimeOut " ;
VAL_ 2560884641 NBCMU01_InitialFault 0 " Normal " 1 " Fault " ;
VAL_ 2560884641 NBCMU01_ThermalManagement_Fault 0 " Normal " 1 " Fault " ;
VAL_ 2560884641 NBCMU01_DCS_ActOprtMode 0 " OFF " 1 " Standby " 2 " Connecting to charging station " 3 " Connected to charging station " 4 " Connect charging station failed " 5 " Charging in progress " 6 " Charging finished " 7 " Emergency shutdown " ;
VAL_ 2560884641 NBCMU01_ChrgFault 0 " Normal " 1 " Fault " ;
VAL_ 2560884641 NBCMU01_DC_ChrgEnable 0 " Disable " 1 " Enable " ;
VAL_ 2560884641 NBCMU01_Contactor_DC_Cmd 0 " open " 1 " close " ;
VAL_ 2561736610 NBCMU02_Contactor_state_Negative 0 " open " 1 " close " ;
VAL_ 2561736610 NBCMU02_Contactor_state_Positive 0 " open " 1 " close " ;
VAL_ 2561736610 NBCMU02_Contactor_state_PreChrg 0 " open " 1 " close " ;
VAL_ 2561736610 NBCMU02_Contactor_state_Heat 0 " open " 1 " close " ;
VAL_ 2561736610 NBCMU02_WorkState 0 " Invalid " 1 " Standby " 2 " Discharging " 3 " Charging " 4 " Warning " 5 " Fault " 6 " reserved " 7 " reserved " ;
VAL_ 2561802146 NBCMU02_SysFailSta 0 " No Error " 1 " Level_Error " 2 " Leve2_Error " 3 " Leve3_Error " ;
VAL_ 2561802146 NBCMU02_InsRes_polarity 0 " InsResP equal InsResN " 1 " InsResP Lesser " 2 " InsResN Lesser " 3 " Reserved " ;
VAL_ 2561802146 NBCMU02_BattVolt_HighWarning 0 " Normal " 1 " Level 1 Warning " 2 " Level 2 Warning " 3 " Level 3 Warning " ;
VAL_ 2561802146 NBCMU02_BattVolt_LowWarning 0 " Normal " 1 " Level 1 Warning " 2 " Level 2 Warning " 3 " Level 3 Warning " ;
VAL_ 2561802146 NBCMU02_CellVolt_HighWarning 0 " Normal " 1 " Level 1 Warning " 2 " Level 2 Warning " 3 " Level 3 Warning " ;
VAL_ 2561802146 NBCMU02_CellVolt_LowWarning 0 " Normal " 1 " Level 1 Warning " 2 " Level 2 Warning " 3 " Level 3 Warning " ;
VAL_ 2561802146 NBCMU02_ChrgTemp_HighWarning 0 " Normal " 1 " Level 1 Warning " 2 " Level 2 Warning " 3 " Level 3 Warning " ;
VAL_ 2561802146 NBCMU02_ChrgTemp_LowWarning 0 " Normal " 1 " Level 1 Warning " 2 " Level 2 Warning " 3 " Level 3 Warning " ;
VAL_ 2561802146 NBCMU02_DischrgTemp_HighWarning 0 " Normal " 1 " Level 1 Warning " 2 " Level 2 Warning " 3 " Level 3 Warning " ;
VAL_ 2561802146 NBCMU02_DischrgTemp_LowWarning 0 " Normal " 1 " Level 1 Warning " 2 " Level 2 Warning " 3 " Level 3 Warning " ;
VAL_ 2561802146 NBCMU02_TempDiff_Warning 0 " Normal " 1 " Level 1 Warning " 2 " Level 2 Warning " 3 " Level 3 Warning " ;
VAL_ 2561802146 NBCMU02_CellVoltDiff_Warning 0 " Normal " 1 " Level 1 Warning " 2 " Level 2 Warning " 3 " Level 3 Warning " ;
VAL_ 2561802146 NBCMU02_DischrgCurr_OverWarning 0 " Normal " 1 " Level 1 Warning " 2 " Level 2 Warning " 3 " Level 3 Warning " ;
VAL_ 2561802146 NBCMU02_ChrgCurr_OverWarning 0 " Normal " 1 " Level 1 Warning " 2 " Level 2 Warning " 3 " Level 3 Warning " ;
VAL_ 2561802146 NBCMU02_InsulationWarning 0 " Normal " 1 " Level 1 Warning " 2 " Level 2 Warning " 3 " Level 3 Warning " ;
VAL_ 2561802146 NBCMU02_SOC_LowWarning 0 " Normal " 1 " Level 1 Warning " 2 " Level 2 Warning " 3 " Level 3 Warning " ;
VAL_ 2561802146 NBCMU02_AmbientTemp_HighWarning 0 " Normal " 1 " Level 1 Warning " 2 " Level 2 Warning " 3 " Level 3 Warning " ;
VAL_ 2561802146 NBCMU02_AmbientTemp_LowWarning 0 " Normal " 1 " Level 1 Warning " 2 " Level 2 Warning " 3 " Level 3 Warning " ;
VAL_ 2561802146 NBCMU02_ContactorPosi_Fault 0 " Normal " 1 " can not close " 2 " can not open " 3 " reserved " ;
VAL_ 2561802146 NBCMU02_ContactorNega_Fault 0 " Normal " 1 " can not close " 2 " can not open " 3 " reserved " ;
VAL_ 2561802146 NBCMU02_ContactorBalan_Fault 0 " Normal " 1 " can not close " 2 " can not open " 3 " reserved " ;
VAL_ 2561802146 NBCMU02_ContactorHeat_Fault 0 " Normal " 1 " can not close " 2 " can not open " 3 " reserved " ;
VAL_ 2561802146 NBCMU02_CurrSensor_TimeOut 0 " Normal " 1 " TimeOut " ;
VAL_ 2561802146 NBCMU02_SOH_LowWarning 0 " Normal " 1 " Level 1 Warning " 2 " Level 2 Warning " 3 " Level 3 Warning " ;
VAL_ 2561802146 NBCMU02_HVIL_Fault 0 " Normal " 1 " Fault " ;
VAL_ 2561802146 NBCMU02_Fuse_Fault 0 " Normal " 1 " Fault " ;
VAL_ 2562457506 NBCMU02_NBICU_TimeOut 0 " Normal " 1 " TimeOut " ;
VAL_ 2562457506 NBCMU02_PrechrgFault 0 " Normal " 1 " Fault " ;
VAL_ 2562457506 NBCMU02_SupplyVolt_HighWarning 0 " Normal " 1 " Level 1 Warning " 2 " Level 2 Warning " 3 " Level 3 Warning " ;
VAL_ 2562457506 NBCMU02_SupplyVolt_LowWarning 0 " Normal " 1 " Level 1 Warning " 2 " Level 2 Warning " 3 " Level 3 Warning " ;
VAL_ 2562457506 NBCMU02_CellVoltOpen 0 " Normal " 1 " Fault " ;
VAL_ 2562457506 NBCMU02_CellTempOpen 0 " Normal " 1 " Fault " ;
VAL_ 2560884642 NBCMU02_SumVolt_HighWarning 0 " Normal " 1 " Level 1 Warning " 2 " Level 2 Warning " 3 " Level 3 Warning " ;
VAL_ 2560884642 NBCMU02_SumVolt_LowWarning 0 " Normal " 1 " Level 1 Warning " 2 " Level 2 Warning " 3 " Level 3 Warning " ;
VAL_ 2560884642 NBCMU02_CurrentLoop_HighWarning 0 " Normal " 1 " Fault " ;
VAL_ 2560884642 NBCMU02_ProtectFault 0 " Normal " 1 " Fault " ;
VAL_ 2560884642 NBCMU02_RunLed_State 0 " open " 1 " close " ;
VAL_ 2560884642 NBCMU02_Buzz_State 0 " Off " 1 " On " ;
VAL_ 2560884642 NBCMU02_Heating_State 0 " turn off " 1 " turn on " ;
VAL_ 2560884642 NBCMU02_Cooling_State 0 " turn off " 1 " turn on " ;
VAL_ 2560884642 NBCMU02_BattVoltDiff_Warning 0 " Normal " 1 " Fault " ;
VAL_ 2560884642 NBCMU02_EmergyShutdown_Fault 0 " Normal " 1 " Fault " ;
VAL_ 2560884642 NBCMU02_PCS_TimeOut 0 " Normal " 1 " TimeOut " ;
VAL_ 2560884642 NBCMU02_EMS_TimeOut 0 " Normal " 1 " TimeOut " ;
VAL_ 2560884642 NBCMU02_TMS_TimeOut 0 " Normal " 1 " TimeOut " ;
VAL_ 2560884642 NBCMU02_SBCMU01_TimeOut 0 " Normal " 1 " TimeOut " ;
VAL_ 2560884642 NBCMU02_InitialFault 0 " Normal " 1 " Fault " ;
VAL_ 2560884642 NBCMU02_ThermalManagement_Fault 0 " Normal " 1 " Fault " ;
VAL_ 2560884642 NBCMU02_DCS_ActOprtMode 0 " OFF " 1 " Standby " 2 " Connecting to charging station " 3 " Connected to charging station " 4 " Connect charging station failed " 5 " Charging in progress " 6 " Charging finished " 7 " Emergency shutdown " ;
VAL_ 2560884642 NBCMU02_ChrgFault 0 " Normal " 1 " Fault " ;
VAL_ 2560884642 NBCMU02_DC_ChrgEnable 0 " Disable " 1 " Enable " ;
VAL_ 2560884642 NBCMU02_Contactor_DC_Cmd 0 " open " 1 " close " ;
VAL_ 2561736611 NBCMU03_Contactor_state_Negative 0 " open " 1 " close " ;
VAL_ 2561736611 NBCMU03_Contactor_state_Positive 0 " open " 1 " close " ;
VAL_ 2561736611 NBCMU03_Contactor_state_PreChrg 0 " open " 1 " close " ;
VAL_ 2561736611 NBCMU03_Contactor_state_Heat 0 " open " 1 " close " ;
VAL_ 2561736611 NBCMU03_WorkState 0 " Invalid " 1 " Standby " 2 " Discharging " 3 " Charging " 4 " Warning " 5 " Fault " 6 " reserved " 7 " reserved " ;
VAL_ 2561802147 NBCMU03_SysFailSta 0 " No Error " 1 " Level_Error " 2 " Leve2_Error " 3 " Leve3_Error " ;
VAL_ 2561802147 NBCMU03_InsRes_polarity 0 " InsResP equal InsResN " 1 " InsResP Lesser " 2 " InsResN Lesser " 3 " Reserved " ;
VAL_ 2561802147 NBCMU03_BattVolt_HighWarning 0 " Normal " 1 " Level 1 Warning " 2 " Level 2 Warning " 3 " Level 3 Warning " ;
VAL_ 2561802147 NBCMU03_BattVolt_LowWarning 0 " Normal " 1 " Level 1 Warning " 2 " Level 2 Warning " 3 " Level 3 Warning " ;
VAL_ 2561802147 NBCMU03_CellVolt_HighWarning 0 " Normal " 1 " Level 1 Warning " 2 " Level 2 Warning " 3 " Level 3 Warning " ;
VAL_ 2561802147 NBCMU03_CellVolt_LowWarning 0 " Normal " 1 " Level 1 Warning " 2 " Level 2 Warning " 3 " Level 3 Warning " ;
VAL_ 2561802147 NBCMU03_ChrgTemp_HighWarning 0 " Normal " 1 " Level 1 Warning " 2 " Level 2 Warning " 3 " Level 3 Warning " ;
VAL_ 2561802147 NBCMU03_ChrgTemp_LowWarning 0 " Normal " 1 " Level 1 Warning " 2 " Level 2 Warning " 3 " Level 3 Warning " ;
VAL_ 2561802147 NBCMU03_DischrgTemp_HighWarning 0 " Normal " 1 " Level 1 Warning " 2 " Level 2 Warning " 3 " Level 3 Warning " ;
VAL_ 2561802147 NBCMU03_DischrgTemp_LowWarning 0 " Normal " 1 " Level 1 Warning " 2 " Level 2 Warning " 3 " Level 3 Warning " ;
VAL_ 2561802147 NBCMU03_TempDiff_Warning 0 " Normal " 1 " Level 1 Warning " 2 " Level 2 Warning " 3 " Level 3 Warning " ;
VAL_ 2561802147 NBCMU03_CellVoltDiff_Warning 0 " Normal " 1 " Level 1 Warning " 2 " Level 2 Warning " 3 " Level 3 Warning " ;
VAL_ 2561802147 NBCMU03_DischrgCurr_OverWarning 0 " Normal " 1 " Level 1 Warning " 2 " Level 2 Warning " 3 " Level 3 Warning " ;
VAL_ 2561802147 NBCMU03_ChrgCurr_OverWarning 0 " Normal " 1 " Level 1 Warning " 2 " Level 2 Warning " 3 " Level 3 Warning " ;
VAL_ 2561802147 NBCMU03_InsulationWarning 0 " Normal " 1 " Level 1 Warning " 2 " Level 2 Warning " 3 " Level 3 Warning " ;
VAL_ 2561802147 NBCMU03_SOC_LowWarning 0 " Normal " 1 " Level 1 Warning " 2 " Level 2 Warning " 3 " Level 3 Warning " ;
VAL_ 2561802147 NBCMU03_AmbientTemp_HighWarning 0 " Normal " 1 " Level 1 Warning " 2 " Level 2 Warning " 3 " Level 3 Warning " ;
VAL_ 2561802147 NBCMU03_AmbientTemp_LowWarning 0 " Normal " 1 " Level 1 Warning " 2 " Level 2 Warning " 3 " Level 3 Warning " ;
VAL_ 2561802147 NBCMU03_ContactorPosi_Fault 0 " Normal " 1 " can not close " 2 " can not open " 3 " reserved " ;
VAL_ 2561802147 NBCMU03_ContactorNega_Fault 0 " Normal " 1 " can not close " 2 " can not open " 3 " reserved " ;
VAL_ 2561802147 NBCMU03_ContactorBalan_Fault 0 " Normal " 1 " can not close " 2 " can not open " 3 " reserved " ;
VAL_ 2561802147 NBCMU03_ContactorHeat_Fault 0 " Normal " 1 " can not close " 2 " can not open " 3 " reserved " ;
VAL_ 2561802147 NBCMU03_CurrSensor_TimeOut 0 " Normal " 1 " TimeOut " ;
VAL_ 2561802147 NBCMU03_SOH_LowWarning 0 " Normal " 1 " Level 1 Warning " 2 " Level 2 Warning " 3 " Level 3 Warning " ;
VAL_ 2561802147 NBCMU03_HVIL_Fault 0 " Normal " 1 " Fault " ;
VAL_ 2561802147 NBCMU03_Fuse_Fault 0 " Normal " 1 " Fault " ;
VAL_ 2562457507 NBCMU03_NBICU_TimeOut 0 " Normal " 1 " TimeOut " ;
VAL_ 2562457507 NBCMU03_PrechrgFault 0 " Normal " 1 " Fault " ;
VAL_ 2562457507 NBCMU03_SupplyVolt_HighWarning 0 " Normal " 1 " Level 1 Warning " 2 " Level 2 Warning " 3 " Level 3 Warning " ;
VAL_ 2562457507 NBCMU03_SupplyVolt_LowWarning 0 " Normal " 1 " Level 1 Warning " 2 " Level 2 Warning " 3 " Level 3 Warning " ;
VAL_ 2562457507 NBCMU03_CellVoltOpen 0 " Normal " 1 " Fault " ;
VAL_ 2562457507 NBCMU03_CellTempOpen 0 " Normal " 1 " Fault " ;
VAL_ 2560884643 NBCMU03_SumVolt_HighWarning 0 " Normal " 1 " Level 1 Warning " 2 " Level 2 Warning " 3 " Level 3 Warning " ;
VAL_ 2560884643 NBCMU03_SumVolt_LowWarning 0 " Normal " 1 " Level 1 Warning " 2 " Level 2 Warning " 3 " Level 3 Warning " ;
VAL_ 2560884643 NBCMU03_CurrentLoop_HighWarning 0 " Normal " 1 " Fault " ;
VAL_ 2560884643 NBCMU03_ProtectFault 0 " Normal " 1 " Fault " ;
VAL_ 2560884643 NBCMU03_RunLed_State 0 " open " 1 " close " ;
VAL_ 2560884643 NBCMU03_Buzz_State 0 " Off " 1 " On " ;
VAL_ 2560884643 NBCMU03_Heating_State 0 " turn off " 1 " turn on " ;
VAL_ 2560884643 NBCMU03_Cooling_State 0 " turn off " 1 " turn on " ;
VAL_ 2560884643 NBCMU03_BattVoltDiff_Warning 0 " Normal " 1 " Fault " ;
VAL_ 2560884643 NBCMU03_EmergyShutdown_Fault 0 " Normal " 1 " Fault " ;
VAL_ 2560884643 NBCMU03_PCS_TimeOut 0 " Normal " 1 " TimeOut " ;
VAL_ 2560884643 NBCMU03_EMS_TimeOut 0 " Normal " 1 " TimeOut " ;
VAL_ 2560884643 NBCMU03_TMS_TimeOut 0 " Normal " 1 " TimeOut " ;
VAL_ 2560884643 NBCMU03_SBCMU01_TimeOut 0 " Normal " 1 " TimeOut " ;
VAL_ 2560884643 NBCMU03_InitialFault 0 " Normal " 1 " Fault " ;
VAL_ 2560884643 NBCMU03_ThermalManagement_Fault 0 " Normal " 1 " Fault " ;
VAL_ 2560884643 NBCMU03_DCS_ActOprtMode 0 " OFF " 1 " Standby " 2 " Connecting to charging station " 3 " Connected to charging station " 4 " Connect charging station failed " 5 " Charging in progress " 6 " Charging finished " 7 " Emergency shutdown " ;
VAL_ 2560884643 NBCMU03_ChrgFault 0 " Normal " 1 " Fault " ;
VAL_ 2560884643 NBCMU03_DC_ChrgEnable 0 " Disable " 1 " Enable " ;
VAL_ 2560884643 NBCMU03_Contactor_DC_Cmd 0 " open " 1 " close " ;
VAL_ 2561736612 NBCMU04_Contactor_state_Negative 0 " open " 1 " close " ;
VAL_ 2561736612 NBCMU04_Contactor_state_Positive 0 " open " 1 " close " ;
VAL_ 2561736612 NBCMU04_Contactor_state_PreChrg 0 " open " 1 " close " ;
VAL_ 2561736612 NBCMU04_Contactor_state_Heat 0 " open " 1 " close " ;
VAL_ 2561736612 NBCMU04_WorkState 0 " Invalid " 1 " Standby " 2 " Discharging " 3 " Charging " 4 " Warning " 5 " Fault " 6 " reserved " 7 " reserved " ;
VAL_ 2561802148 NBCMU04_SysFailSta 0 " No Error " 1 " Level_Error " 2 " Leve2_Error " 3 " Leve3_Error " ;
VAL_ 2561802148 NBCMU04_InsRes_polarity 0 " InsResP equal InsResN " 1 " InsResP Lesser " 2 " InsResN Lesser " 3 " Reserved " ;
VAL_ 2561802148 NBCMU04_BattVolt_HighWarning 0 " Normal " 1 " Level 1 Warning " 2 " Level 2 Warning " 3 " Level 3 Warning " ;
VAL_ 2561802148 NBCMU04_BattVolt_LowWarning 0 " Normal " 1 " Level 1 Warning " 2 " Level 2 Warning " 3 " Level 3 Warning " ;
VAL_ 2561802148 NBCMU04_CellVolt_HighWarning 0 " Normal " 1 " Level 1 Warning " 2 " Level 2 Warning " 3 " Level 3 Warning " ;
VAL_ 2561802148 NBCMU04_CellVolt_LowWarning 0 " Normal " 1 " Level 1 Warning " 2 " Level 2 Warning " 3 " Level 3 Warning " ;
VAL_ 2561802148 NBCMU04_ChrgTemp_HighWarning 0 " Normal " 1 " Level 1 Warning " 2 " Level 2 Warning " 3 " Level 3 Warning " ;
VAL_ 2561802148 NBCMU04_ChrgTemp_LowWarning 0 " Normal " 1 " Level 1 Warning " 2 " Level 2 Warning " 3 " Level 3 Warning " ;
VAL_ 2561802148 NBCMU04_DischrgTemp_HighWarning 0 " Normal " 1 " Level 1 Warning " 2 " Level 2 Warning " 3 " Level 3 Warning " ;
VAL_ 2561802148 NBCMU04_DischrgTemp_LowWarning 0 " Normal " 1 " Level 1 Warning " 2 " Level 2 Warning " 3 " Level 3 Warning " ;
VAL_ 2561802148 NBCMU04_TempDiff_Warning 0 " Normal " 1 " Level 1 Warning " 2 " Level 2 Warning " 3 " Level 3 Warning " ;
VAL_ 2561802148 NBCMU04_CellVoltDiff_Warning 0 " Normal " 1 " Level 1 Warning " 2 " Level 2 Warning " 3 " Level 3 Warning " ;
VAL_ 2561802148 NBCMU04_DischrgCurr_OverWarning 0 " Normal " 1 " Level 1 Warning " 2 " Level 2 Warning " 3 " Level 3 Warning " ;
VAL_ 2561802148 NBCMU04_ChrgCurr_OverWarning 0 " Normal " 1 " Level 1 Warning " 2 " Level 2 Warning " 3 " Level 3 Warning " ;
VAL_ 2561802148 NBCMU04_InsulationWarning 0 " Normal " 1 " Level 1 Warning " 2 " Level 2 Warning " 3 " Level 3 Warning " ;
VAL_ 2561802148 NBCMU04_SOC_LowWarning 0 " Normal " 1 " Level 1 Warning " 2 " Level 2 Warning " 3 " Level 3 Warning " ;
VAL_ 2561802148 NBCMU04_AmbientTemp_HighWarning 0 " Normal " 1 " Level 1 Warning " 2 " Level 2 Warning " 3 " Level 3 Warning " ;
VAL_ 2561802148 NBCMU04_AmbientTemp_LowWarning 0 " Normal " 1 " Level 1 Warning " 2 " Level 2 Warning " 3 " Level 3 Warning " ;
VAL_ 2561802148 NBCMU04_ContactorPosi_Fault 0 " Normal " 1 " can not close " 2 " can not open " 3 " reserved " ;
VAL_ 2561802148 NBCMU04_ContactorNega_Fault 0 " Normal " 1 " can not close " 2 " can not open " 3 " reserved " ;
VAL_ 2561802148 NBCMU04_ContactorBalan_Fault 0 " Normal " 1 " can not close " 2 " can not open " 3 " reserved " ;
VAL_ 2561802148 NBCMU04_ContactorHeat_Fault 0 " Normal " 1 " can not close " 2 " can not open " 3 " reserved " ;
VAL_ 2561802148 NBCMU04_CurrSensor_TimeOut 0 " Normal " 1 " TimeOut " ;
VAL_ 2561802148 NBCMU04_SOH_LowWarning 0 " Normal " 1 " Level 1 Warning " 2 " Level 2 Warning " 3 " Level 3 Warning " ;
VAL_ 2561802148 NBCMU04_HVIL_Fault 0 " Normal " 1 " Fault " ;
VAL_ 2561802148 NBCMU04_Fuse_Fault 0 " Normal " 1 " Fault " ;
VAL_ 2562457508 NBCMU04_NBICU_TimeOut 0 " Normal " 1 " TimeOut " ;
VAL_ 2562457508 NBCMU04_PrechrgFault 0 " Normal " 1 " Fault " ;
VAL_ 2562457508 NBCMU04_SupplyVolt_HighWarning 0 " Normal " 1 " Level 1 Warning " 2 " Level 2 Warning " 3 " Level 3 Warning " ;
VAL_ 2562457508 NBCMU04_SupplyVolt_LowWarning 0 " Normal " 1 " Level 1 Warning " 2 " Level 2 Warning " 3 " Level 3 Warning " ;
VAL_ 2562457508 NBCMU04_CellVoltOpen 0 " Normal " 1 " Fault " ;
VAL_ 2562457508 NBCMU04_CellTempOpen 0 " Normal " 1 " Fault " ;
VAL_ 2560884644 NBCMU04_SumVolt_HighWarning 0 " Normal " 1 " Level 1 Warning " 2 " Level 2 Warning " 3 " Level 3 Warning " ;
VAL_ 2560884644 NBCMU04_SumVolt_LowWarning 0 " Normal " 1 " Level 1 Warning " 2 " Level 2 Warning " 3 " Level 3 Warning " ;
VAL_ 2560884644 NBCMU04_CurrentLoop_HighWarning 0 " Normal " 1 " Fault " ;
VAL_ 2560884644 NBCMU04_ProtectFault 0 " Normal " 1 " Fault " ;
VAL_ 2560884644 NBCMU04_RunLed_State 0 " open " 1 " close " ;
VAL_ 2560884644 NBCMU04_Buzz_State 0 " Off " 1 " On " ;
VAL_ 2560884644 NBCMU04_Heating_State 0 " turn off " 1 " turn on " ;
VAL_ 2560884644 NBCMU04_Cooling_State 0 " turn off " 1 " turn on " ;
VAL_ 2560884644 NBCMU04_BattVoltDiff_Warning 0 " Normal " 1 " Fault " ;
VAL_ 2560884644 NBCMU04_EmergyShutdown_Fault 0 " Normal " 1 " Fault " ;
VAL_ 2560884644 NBCMU04_PCS_TimeOut 0 " Normal " 1 " TimeOut " ;
VAL_ 2560884644 NBCMU04_EMS_TimeOut 0 " Normal " 1 " TimeOut " ;
VAL_ 2560884644 NBCMU04_TMS_TimeOut 0 " Normal " 1 " TimeOut " ;
VAL_ 2560884644 NBCMU04_SBCMU01_TimeOut 0 " Normal " 1 " TimeOut " ;
VAL_ 2560884644 NBCMU04_InitialFault 0 " Normal " 1 " Fault " ;
VAL_ 2560884644 NBCMU04_ThermalManagement_Fault 0 " Normal " 1 " Fault " ;
VAL_ 2560884644 NBCMU04_DCS_ActOprtMode 0 " OFF " 1 " Standby " 2 " Connecting to charging station " 3 " Connected to charging station " 4 " Connect charging station failed " 5 " Charging in progress " 6 " Charging finished " 7 " Emergency shutdown " ;
VAL_ 2560884644 NBCMU04_ChrgFault 0 " Normal " 1 " Fault " ;
VAL_ 2560884644 NBCMU04_DC_ChrgEnable 0 " Disable " 1 " Enable " ;
VAL_ 2560884644 NBCMU04_Contactor_DC_Cmd 0 " open " 1 " close " ;
VAL_ 2561736613 NBCMU05_Contactor_state_Negative 0 " open " 1 " close " ;
VAL_ 2561736613 NBCMU05_Contactor_state_Positive 0 " open " 1 " close " ;
VAL_ 2561736613 NBCMU05_Contactor_state_PreChrg 0 " open " 1 " close " ;
VAL_ 2561736613 NBCMU05_Contactor_state_Heat 0 " open " 1 " close " ;
VAL_ 2561736613 NBCMU05_WorkState 0 " Invalid " 1 " Standby " 2 " Discharging " 3 " Charging " 4 " Warning " 5 " Fault " 6 " reserved " 7 " reserved " ;
VAL_ 2561802149 NBCMU05_SysFailSta 0 " No Error " 1 " Level_Error " 2 " Leve2_Error " 3 " Leve3_Error " ;
VAL_ 2561802149 NBCMU05_InsRes_polarity 0 " InsResP equal InsResN " 1 " InsResP Lesser " 2 " InsResN Lesser " 3 " Reserved " ;
VAL_ 2561802149 NBCMU05_BattVolt_HighWarning 0 " Normal " 1 " Level 1 Warning " 2 " Level 2 Warning " 3 " Level 3 Warning " ;
VAL_ 2561802149 NBCMU05_BattVolt_LowWarning 0 " Normal " 1 " Level 1 Warning " 2 " Level 2 Warning " 3 " Level 3 Warning " ;
VAL_ 2561802149 NBCMU05_CellVolt_HighWarning 0 " Normal " 1 " Level 1 Warning " 2 " Level 2 Warning " 3 " Level 3 Warning " ;
VAL_ 2561802149 NBCMU05_CellVolt_LowWarning 0 " Normal " 1 " Level 1 Warning " 2 " Level 2 Warning " 3 " Level 3 Warning " ;
VAL_ 2561802149 NBCMU05_ChrgTemp_HighWarning 0 " Normal " 1 " Level 1 Warning " 2 " Level 2 Warning " 3 " Level 3 Warning " ;
VAL_ 2561802149 NBCMU05_ChrgTemp_LowWarning 0 " Normal " 1 " Level 1 Warning " 2 " Level 2 Warning " 3 " Level 3 Warning " ;
VAL_ 2561802149 NBCMU05_DischrgTemp_HighWarning 0 " Normal " 1 " Level 1 Warning " 2 " Level 2 Warning " 3 " Level 3 Warning " ;
VAL_ 2561802149 NBCMU05_DischrgTemp_LowWarning 0 " Normal " 1 " Level 1 Warning " 2 " Level 2 Warning " 3 " Level 3 Warning " ;
VAL_ 2561802149 NBCMU05_TempDiff_Warning 0 " Normal " 1 " Level 1 Warning " 2 " Level 2 Warning " 3 " Level 3 Warning " ;
VAL_ 2561802149 NBCMU05_CellVoltDiff_Warning 0 " Normal " 1 " Level 1 Warning " 2 " Level 2 Warning " 3 " Level 3 Warning " ;
VAL_ 2561802149 NBCMU05_DischrgCurr_OverWarning 0 " Normal " 1 " Level 1 Warning " 2 " Level 2 Warning " 3 " Level 3 Warning " ;
VAL_ 2561802149 NBCMU05_ChrgCurr_OverWarning 0 " Normal " 1 " Level 1 Warning " 2 " Level 2 Warning " 3 " Level 3 Warning " ;
VAL_ 2561802149 NBCMU05_InsulationWarning 0 " Normal " 1 " Level 1 Warning " 2 " Level 2 Warning " 3 " Level 3 Warning " ;
VAL_ 2561802149 NBCMU05_SOC_LowWarning 0 " Normal " 1 " Level 1 Warning " 2 " Level 2 Warning " 3 " Level 3 Warning " ;
VAL_ 2561802149 NBCMU05_AmbientTemp_HighWarning 0 " Normal " 1 " Level 1 Warning " 2 " Level 2 Warning " 3 " Level 3 Warning " ;
VAL_ 2561802149 NBCMU05_AmbientTemp_LowWarning 0 " Normal " 1 " Level 1 Warning " 2 " Level 2 Warning " 3 " Level 3 Warning " ;
VAL_ 2561802149 NBCMU05_ContactorPosi_Fault 0 " Normal " 1 " can not close " 2 " can not open " 3 " reserved " ;
VAL_ 2561802149 NBCMU05_ContactorNega_Fault 0 " Normal " 1 " can not close " 2 " can not open " 3 " reserved " ;
VAL_ 2561802149 NBCMU05_ContactorBalan_Fault 0 " Normal " 1 " can not close " 2 " can not open " 3 " reserved " ;
VAL_ 2561802149 NBCMU05_ContactorHeat_Fault 0 " Normal " 1 " can not close " 2 " can not open " 3 " reserved " ;
VAL_ 2561802149 NBCMU05_CurrSensor_TimeOut 0 " Normal " 1 " TimeOut " ;
VAL_ 2561802149 NBCMU05_SOH_LowWarning 0 " Normal " 1 " Level 1 Warning " 2 " Level 2 Warning " 3 " Level 3 Warning " ;
VAL_ 2561802149 NBCMU05_HVIL_Fault 0 " Normal " 1 " Fault " ;
VAL_ 2561802149 NBCMU05_Fuse_Fault 0 " Normal " 1 " Fault " ;
VAL_ 2562457509 NBCMU05_NBICU_TimeOut 0 " Normal " 1 " TimeOut " ;
VAL_ 2562457509 NBCMU05_PrechrgFault 0 " Normal " 1 " Fault " ;
VAL_ 2562457509 NBCMU05_SupplyVolt_HighWarning 0 " Normal " 1 " Level 1 Warning " 2 " Level 2 Warning " 3 " Level 3 Warning " ;
VAL_ 2562457509 NBCMU05_SupplyVolt_LowWarning 0 " Normal " 1 " Level 1 Warning " 2 " Level 2 Warning " 3 " Level 3 Warning " ;
VAL_ 2562457509 NBCMU05_CellVoltOpen 0 " Normal " 1 " Fault " ;
VAL_ 2562457509 NBCMU05_CellTempOpen 0 " Normal " 1 " Fault " ;
VAL_ 2560884645 NBCMU05_SumVolt_HighWarning 0 " Normal " 1 " Level 1 Warning " 2 " Level 2 Warning " 3 " Level 3 Warning " ;
VAL_ 2560884645 NBCMU05_SumVolt_LowWarning 0 " Normal " 1 " Level 1 Warning " 2 " Level 2 Warning " 3 " Level 3 Warning " ;
VAL_ 2560884645 NBCMU05_CurrentLoop_HighWarning 0 " Normal " 1 " Fault " ;
VAL_ 2560884645 NBCMU05_ProtectFault 0 " Normal " 1 " Fault " ;
VAL_ 2560884645 NBCMU05_RunLed_State 0 " open " 1 " close " ;
VAL_ 2560884645 NBCMU05_Buzz_State 0 " Off " 1 " On " ;
VAL_ 2560884645 NBCMU05_Heating_State 0 " turn off " 1 " turn on " ;
VAL_ 2560884645 NBCMU05_Cooling_State 0 " turn off " 1 " turn on " ;
VAL_ 2560884645 NBCMU05_BattVoltDiff_Warning 0 " Normal " 1 " Fault " ;
VAL_ 2560884645 NBCMU05_EmergyShutdown_Fault 0 " Normal " 1 " Fault " ;
VAL_ 2560884645 NBCMU05_PCS_TimeOut 0 " Normal " 1 " TimeOut " ;
VAL_ 2560884645 NBCMU05_EMS_TimeOut 0 " Normal " 1 " TimeOut " ;
VAL_ 2560884645 NBCMU05_TMS_TimeOut 0 " Normal " 1 " TimeOut " ;
VAL_ 2560884645 NBCMU05_SBCMU01_TimeOut 0 " Normal " 1 " TimeOut " ;
VAL_ 2560884645 NBCMU05_InitialFault 0 " Normal " 1 " Fault " ;
VAL_ 2560884645 NBCMU05_ThermalManagement_Fault 0 " Normal " 1 " Fault " ;
VAL_ 2560884645 NBCMU05_DCS_ActOprtMode 0 " OFF " 1 " Standby " 2 " Connecting to charging station " 3 " Connected to charging station " 4 " Connect charging station failed " 5 " Charging in progress " 6 " Charging finished " 7 " Emergency shutdown " ;
VAL_ 2560884645 NBCMU05_ChrgFault 0 " Normal " 1 " Fault " ;
VAL_ 2560884645 NBCMU05_DC_ChrgEnable 0 " Disable " 1 " Enable " ;
VAL_ 2560884645 NBCMU05_Contactor_DC_Cmd 0 " open " 1 " close " ;
VAL_ 2562260913 SBCMU01_BattVolt_HighWarning 0 " Normal " 1 " Level 1 Warning " 2 " Level 2 Warning " 3 " Level 3 Warning " ;
VAL_ 2562260913 SBCMU01_SumVolt_HighWarning 0 " Normal " 1 " Level 1 Warning " 2 " Level 2 Warning " 3 " Level 3 Warning " ;
VAL_ 2562260913 SBCMU01_CellVolt_HighWarning 0 " Normal " 1 " Level 1 Warning " 2 " Level 2 Warning " 3 " Level 3 Warning " ;
VAL_ 2562260913 SBCMU01_Temp_HighWarning 0 " Normal " 1 " Level 3 Warning " ;
VAL_ 2562260913 SBCMU01_AmbientTemp_HighWarning 0 " Normal " 1 " Level 3 Warning " ;
VAL_ 2562260913 SBCMU01_SysFailSta 0 " No Error " 1 " Level_Error " 2 " Leve2_Error " 3 " Leve3_Error " ;
VAL_ 2562260913 SBCMU01_SBICU_TimeOut 0 " Normal " 1 " TimeOut " ;
VAL_ 2562260913 SBCMU01_CellTempOpen 0 " Normal " 1 " Fault " ;
VAL_ 2562260913 SBCMU01_SupplyVolt_HighWarning 0 " Normal " 1 " Level 1 Warning " 2 " Level 2 Warning " 3 " Level 3 Warning " ;
VAL_ 2562260913 SBCMU01_SupplyVolt_LowWarning 0 " Normal " 1 " Level 1 Warning " 2 " Level 2 Warning " 3 " Level 3 Warning " ;
VAL_ 2562391985 SBCMU01_WorkState 0 " Invalid " 1 " Standby " 2 " reserved " 3 " reserved " 4 " Warning " 5 " Fault " 6 " reserved " 7 " reserved " ;
VAL_ 2562391985 SBCMU01_Contactor_state_Safty 0 " open " 1 " close " ;
VAL_ 2560819121 SBCMU01_Electronic_Lock_State 0 " unlocked " 1 " locked " ;
VAL_ 2560819121 SBCMU01_DCS_InletConnectSta 0 " Not Connected " 1 " Connected " ;
VAL_ 2560819121 SBCMU01_DCS_ChrgAPlus 0 " Disable " 1 " Enable " ;
VAL_ 2560819121 SBCMU01_DCChrg_Stage 0 " DCS ChrgOFF " 1 " DCS HandShake " 2 " DCS ParaConfig " 3 " DCS Connect " 4 " DCS_Charging " 5 " DCS ChargeFinish " 6 " DCS TimeOut " 7 " DCS WaitCurrDown " 8 " DCS ReConnect " 9 " DCS ShutDown " ;
VAL_ 2560819121 SBCMU01_Contactor_state_DC 0 " open " 1 " close " ;
VAL_ 2560819121 SBCMU01_DCChrg_ISO_Enable 0 " Disable " 1 " Enable " ;
VAL_ 2560819121 SBCMU01_SocketTemp_HighWarning 0 " Normal " 1 " Level 1 Warning " 2 " Level 2 Warning " 3 " Level 3 Warning " ;
VAL_ 2562260914 SBCMU02_BattVolt_HighWarning 0 " Normal " 1 " Level 1 Warning " 2 " Level 2 Warning " 3 " Level 3 Warning " ;
VAL_ 2562260914 SBCMU02_SumVolt_HighWarning 0 " Normal " 1 " Level 1 Warning " 2 " Level 2 Warning " 3 " Level 3 Warning " ;
VAL_ 2562260914 SBCMU02_CellVolt_HighWarning 0 " Normal " 1 " Level 1 Warning " 2 " Level 2 Warning " 3 " Level 3 Warning " ;
VAL_ 2562260914 SBCMU02_Temp_HighWarning 0 " Normal " 1 " Level 3 Warning " ;
VAL_ 2562260914 SBCMU02_AmbientTemp_HighWarning 0 " Normal " 1 " Level 3 Warning " ;
VAL_ 2562260914 SBCMU02_SysFailSta 0 " No Error " 1 " Level_Error " 2 " Leve2_Error " 3 " Leve3_Error " ;
VAL_ 2562260914 SBCMU02_SBICU_TimeOut 0 " Normal " 1 " TimeOut " ;
VAL_ 2562260914 SBCMU02_CellTempOpen 0 " Normal " 1 " Fault " ;
VAL_ 2562260914 SBCMU02_SupplyVolt_HighWarning 0 " Normal " 1 " Level 1 Warning " 2 " Level 2 Warning " 3 " Level 3 Warning " ;
VAL_ 2562260914 SBCMU02_SupplyVolt_LowWarning 0 " Normal " 1 " Level 1 Warning " 2 " Level 2 Warning " 3 " Level 3 Warning " ;
VAL_ 2562391986 SBCMU02_WorkState 0 " Invalid " 1 " Standby " 2 " reserved " 3 " reserved " 4 " Warning " 5 " Fault " 6 " reserved " 7 " reserved " ;
VAL_ 2562391986 SBCMU02_Contactor_state_Safty 0 " open " 1 " close " ;
VAL_ 2560819122 SBCMU02_Electronic_Lock_State 0 " unlocked " 1 " locked " ;
VAL_ 2560819122 SBCMU02_DCS_InletConnectSta 0 " Not Connected " 1 " Connected " ;
VAL_ 2560819122 SBCMU02_DCS_ChrgAPlus 0 " Disable " 1 " Enable " ;
VAL_ 2560819122 SBCMU02_DCChrg_Stage 0 " DCS ChrgOFF " 1 " DCS HandShake " 2 " DCS ParaConfig " 3 " DCS Connect " 4 " DCS_Charging " 5 " DCS ChargeFinish " 6 " DCS TimeOut " 7 " DCS WaitCurrDown " 8 " DCS ReConnect " 9 " DCS ShutDown " ;
VAL_ 2560819122 SBCMU02_Contactor_state_DC 0 " open " 1 " close " ;
VAL_ 2560819122 SBCMU02_DCChrg_ISO_Enable 0 " Disable " 1 " Enable " ;
VAL_ 2560819122 SBCMU02_SocketTemp_HighWarning 0 " Normal " 1 " Level 1 Warning " 2 " Level 2 Warning " 3 " Level 3 Warning " ;
VAL_ 2562260915 SBCMU03_BattVolt_HighWarning 0 " Normal " 1 " Level 1 Warning " 2 " Level 2 Warning " 3 " Level 3 Warning " ;
VAL_ 2562260915 SBCMU03_SumVolt_HighWarning 0 " Normal " 1 " Level 1 Warning " 2 " Level 2 Warning " 3 " Level 3 Warning " ;
VAL_ 2562260915 SBCMU03_CellVolt_HighWarning 0 " Normal " 1 " Level 1 Warning " 2 " Level 2 Warning " 3 " Level 3 Warning " ;
VAL_ 2562260915 SBCMU03_Temp_HighWarning 0 " Normal " 1 " Level 3 Warning " ;
VAL_ 2562260915 SBCMU03_AmbientTemp_HighWarning 0 " Normal " 1 " Level 3 Warning " ;
VAL_ 2562260915 SBCMU03_SysFailSta 0 " No Error " 1 " Level_Error " 2 " Leve2_Error " 3 " Leve3_Error " ;
VAL_ 2562260915 SBCMU03_SBICU_TimeOut 0 " Normal " 1 " TimeOut " ;
VAL_ 2562260915 SBCMU03_CellTempOpen 0 " Normal " 1 " Fault " ;
VAL_ 2562260915 SBCMU03_SupplyVolt_HighWarning 0 " Normal " 1 " Level 1 Warning " 2 " Level 2 Warning " 3 " Level 3 Warning " ;
VAL_ 2562260915 SBCMU03_SupplyVolt_LowWarning 0 " Normal " 1 " Level 1 Warning " 2 " Level 2 Warning " 3 " Level 3 Warning " ;
VAL_ 2562391987 SBCMU03_WorkState 0 " Invalid " 1 " Standby " 2 " reserved " 3 " reserved " 4 " Warning " 5 " Fault " 6 " reserved " 7 " reserved " ;
VAL_ 2562391987 SBCMU03_Contactor_state_Safty 0 " open " 1 " close " ;
VAL_ 2560819123 SBCMU03_Electronic_Lock_State 0 " unlocked " 1 " locked " ;
VAL_ 2560819123 SBCMU03_DCS_InletConnectSta 0 " Not Connected " 1 " Connected " ;
VAL_ 2560819123 SBCMU03_DCS_ChrgAPlus 0 " Disable " 1 " Enable " ;
VAL_ 2560819123 SBCMU03_DCChrg_Stage 0 " DCS ChrgOFF " 1 " DCS HandShake " 2 " DCS ParaConfig " 3 " DCS Connect " 4 " DCS_Charging " 5 " DCS ChargeFinish " 6 " DCS TimeOut " 7 " DCS WaitCurrDown " 8 " DCS ReConnect " 9 " DCS ShutDown " ;
VAL_ 2560819123 SBCMU03_Contactor_state_DC 0 " open " 1 " close " ;
VAL_ 2560819123 SBCMU03_DCChrg_ISO_Enable 0 " Disable " 1 " Enable " ;
VAL_ 2560819123 SBCMU03_SocketTemp_HighWarning 0 " Normal " 1 " Level 1 Warning " 2 " Level 2 Warning " 3 " Level 3 Warning " ;
VAL_ 2562260916 SBCMU04_BattVolt_HighWarning 0 " Normal " 1 " Level 1 Warning " 2 " Level 2 Warning " 3 " Level 3 Warning " ;
VAL_ 2562260916 SBCMU04_SumVolt_HighWarning 0 " Normal " 1 " Level 1 Warning " 2 " Level 2 Warning " 3 " Level 3 Warning " ;
VAL_ 2562260916 SBCMU04_CellVolt_HighWarning 0 " Normal " 1 " Level 1 Warning " 2 " Level 2 Warning " 3 " Level 3 Warning " ;
VAL_ 2562260916 SBCMU04_Temp_HighWarning 0 " Normal " 1 " Level 3 Warning " ;
VAL_ 2562260916 SBCMU04_AmbientTemp_HighWarning 0 " Normal " 1 " Level 3 Warning " ;
VAL_ 2562260916 SBCMU04_SysFailSta 0 " No Error " 1 " Level_Error " 2 " Leve2_Error " 3 " Leve3_Error " ;
VAL_ 2562260916 SBCMU04_SBICU_TimeOut 0 " Normal " 1 " TimeOut " ;
VAL_ 2562260916 SBCMU04_CellTempOpen 0 " Normal " 1 " Fault " ;
VAL_ 2562260916 SBCMU04_SupplyVolt_HighWarning 0 " Normal " 1 " Level 1 Warning " 2 " Level 2 Warning " 3 " Level 3 Warning " ;
VAL_ 2562260916 SBCMU04_SupplyVolt_LowWarning 0 " Normal " 1 " Level 1 Warning " 2 " Level 2 Warning " 3 " Level 3 Warning " ;
VAL_ 2562391988 SBCMU04_WorkState 0 " Invalid " 1 " Standby " 2 " reserved " 3 " reserved " 4 " Warning " 5 " Fault " 6 " reserved " 7 " reserved " ;
VAL_ 2562391988 SBCMU04_Contactor_state_Safty 0 " open " 1 " close " ;
VAL_ 2560819124 SBCMU04_Electronic_Lock_State 0 " unlocked " 1 " locked " ;
VAL_ 2560819124 SBCMU04_DCS_InletConnectSta 0 " Not Connected " 1 " Connected " ;
VAL_ 2560819124 SBCMU04_DCS_ChrgAPlus 0 " Disable " 1 " Enable " ;
VAL_ 2560819124 SBCMU04_DCChrg_Stage 0 " DCS ChrgOFF " 1 " DCS HandShake " 2 " DCS ParaConfig " 3 " DCS Connect " 4 " DCS_Charging " 5 " DCS ChargeFinish " 6 " DCS TimeOut " 7 " DCS WaitCurrDown " 8 " DCS ReConnect " 9 " DCS ShutDown " ;
VAL_ 2560819124 SBCMU04_Contactor_state_DC 0 " open " 1 " close " ;
VAL_ 2560819124 SBCMU04_DCChrg_ISO_Enable 0 " Disable " 1 " Enable " ;
VAL_ 2560819124 SBCMU04_SocketTemp_HighWarning 0 " Normal " 1 " Level 1 Warning " 2 " Level 2 Warning " 3 " Level 3 Warning " ;
VAL_ 2562260917 SBCMU05_BattVolt_HighWarning 0 " Normal " 1 " Level 1 Warning " 2 " Level 2 Warning " 3 " Level 3 Warning " ;
VAL_ 2562260917 SBCMU05_SumVolt_HighWarning 0 " Normal " 1 " Level 1 Warning " 2 " Level 2 Warning " 3 " Level 3 Warning " ;
VAL_ 2562260917 SBCMU05_CellVolt_HighWarning 0 " Normal " 1 " Level 1 Warning " 2 " Level 2 Warning " 3 " Level 3 Warning " ;
VAL_ 2562260917 SBCMU05_Temp_HighWarning 0 " Normal " 1 " Level 3 Warning " ;
VAL_ 2562260917 SBCMU05_AmbientTemp_HighWarning 0 " Normal " 1 " Level 3 Warning " ;
VAL_ 2562260917 SBCMU05_SysFailSta 0 " No Error " 1 " Level_Error " 2 " Leve2_Error " 3 " Leve3_Error " ;
VAL_ 2562260917 SBCMU05_SBICU_TimeOut 0 " Normal " 1 " TimeOut " ;
VAL_ 2562260917 SBCMU05_CellTempOpen 0 " Normal " 1 " Fault " ;
VAL_ 2562260917 SBCMU05_SupplyVolt_HighWarning 0 " Normal " 1 " Level 1 Warning " 2 " Level 2 Warning " 3 " Level 3 Warning " ;
VAL_ 2562260917 SBCMU05_SupplyVolt_LowWarning 0 " Normal " 1 " Level 1 Warning " 2 " Level 2 Warning " 3 " Level 3 Warning " ;
VAL_ 2562391989 SBCMU05_WorkState 0 " Invalid " 1 " Standby " 2 " reserved " 3 " reserved " 4 " Warning " 5 " Fault " 6 " reserved " 7 " reserved " ;
VAL_ 2562391989 SBCMU05_Contactor_state_Safty 0 " open " 1 " close " ;
VAL_ 2560819125 SBCMU05_Electronic_Lock_State 0 " unlocked " 1 " locked " ;
VAL_ 2560819125 SBCMU05_DCS_InletConnectSta 0 " Not Connected " 1 " Connected " ;
VAL_ 2560819125 SBCMU05_DCS_ChrgAPlus 0 " Disable " 1 " Enable " ;
VAL_ 2560819125 SBCMU05_DCChrg_Stage 0 " DCS ChrgOFF " 1 " DCS HandShake " 2 " DCS ParaConfig " 3 " DCS Connect " 4 " DCS_Charging " 5 " DCS ChargeFinish " 6 " DCS TimeOut " 7 " DCS WaitCurrDown " 8 " DCS ReConnect " 9 " DCS ShutDown " ;
VAL_ 2560819125 SBCMU05_Contactor_state_DC 0 " open " 1 " close " ;
VAL_ 2560819125 SBCMU05_DCChrg_ISO_Enable 0 " Disable " 1 " Enable " ;
VAL_ 2560819125 SBCMU05_SocketTemp_HighWarning 0 " Normal " 1 " Level 1 Warning " 2 " Level 2 Warning " 3 " Level 3 Warning " ;
VAL_ 2564030431 NBICU_CellBalaCmd_Mode 0 " No Cmd " 1 " ByChannel " 2 " ByCellDiff " 3 " Reserverd " ;
VAL_ 2564489183 DAPP_NBCMU_AddConfigCmd 0 " NoRequest " 1 " Start configuration " 2 " Successfully configured " 3 " Configure failed " ;
VAL_ 2564489183 DAPP_SBCMU_AddConfigCmd 0 " NoRequest " 1 " Start configuration " 2 " Successfully configured " 3 " Configure failed " ;
VAL_ 2564489183 DAPP_NBICU_AddConfigCmd 0 " NoRequest " 1 " Start configuration " 2 " Successfully configured " 3 " Configure failed " ;
VAL_ 2564489183 DAPP_SBICU_AddConfigCmd 0 " NoRequest " 1 " Start configuration " 2 " Successfully configured " 3 " Configure failed " ;
VAL_ 2564554719 DAPP_Set_SOCActlValid 0 " Invalid " 1 " Valid " ;
VAL_ 2564554719 DAPP_Set_SOCDisValid 0 " Invalid " 1 " Valid " ;
VAL_ 2564554719 DAPP_Set_AccChrgCapaValid 0 " Invalid " 1 " Valid " ;
VAL_ 2564554719 DAPP_Set_NewAddrValid 0 " Invalid " 1 " Valid " ;
VAL_ 2564554719 DAPP_Set_InsDetect_Forbid 0 " Allow " 1 " Forbid " ;
VAL_ 2563899359 DAPP_Set_Fault 0 " Clear Fault " 1 " Set Fault " ;
VAL_ 2563899359 DAPP_FaultDetect_Mode 0 " Automatic Detection " 1 " Manual Setting " ;
VAL_ 2563964895 DAPP_Threshold_Mode 0 " Program Setting " 1 " Manual Setting " ;
